[part 2 of 2: packages /CommunicationClusters/CANFD1_Cluster4 to /Gateways]
AUTOSAR XML (schema 00046)
package /CommunicationClusters/CANFD1_Cluster4
  can cluster CANFD1_Cluster4: baudrate=500000, protocol-name=CAN, protocol-version=can2.0b, can-fd-baudrate=1000000
    can physical channel CANFD1_Cluster4: comm-connectors=ECU4_CRN_CANFD1_Cluster4_bx4qzxpu7xp7napnh6bsrtlzq
      frame FBL_CFG_Star3_ST3: id 0x68, to ECU4_CRN, frame-length=1, can-addressing-mode=STANDARD, can-frame-rx-behavior=CAN-20, can-frame-tx-behavior=CAN-20  # FBL_CFG_Star2
        pdu FBL_Cfg_Star3_ST3: length=1, transmission-mode-true-timing=cyclic-timing={time-offset=0.005, time-period=0.2}, unused-bit-pattern=255  # FBL Konfigurationsinfo für Star2 / FBL configuration info for Star2
          signal Platform_Stat_Star3: start 0, 8 bit, little-endian, data-type-policy=OVERRIDE, i-signal-type=PRIMITIVE, init-value=4, base-type=uint8, invalid-value=255, compu-method=c08_Platform_Stat, data-constr=c08_Platform_Stat, transfer-property=PENDING, to ECU4_CRN  # Plattformstatus / Platform state
      frame GTS_Main_CAN_CTP: id 0x79, from ECU4_CRN, frame-length=8, can-addressing-mode=STANDARD, can-frame-rx-behavior=CAN-FD, can-frame-tx-behavior=CAN-FD  # Status Uhrsynchronisation / Clock synchronisation state
        carries pdu PKG_CANFD1_Cluster4/GTS_Main_CAN_CTP: packing-byte-order=big-endian, start-position=7
        general purpose pdu GTS_Main_CAN_CTP: category=GLOBAL_TIME, length=8  # Status Uhrsynchronisation / Clock synchronisation state
      frame C04_CANFD_1_Container_ST3: id 0x107, from ECU4_CRN, frame-length=64, can-addressing-mode=STANDARD, can-frame-rx-behavior=CAN-FD, can-frame-tx-behavior=CAN-FD  # C04 CANFD 1 Container ST3
        container i pdu C04_CANFD_1_Container_ST3_ContainerIPdu:  # C04 CANFD 1 Container ST3
          length=64
          contained-pdu-triggering=[C04_CANFD_1_Container_ST3_C04_CANFD_1_Container_ST3_Ign_Stat_ST3_1992kn5c94live1gqwsimzuwp, C04_CANFD_1_Container_ST3_C04_CANFD_1_Container_ST3_VSS_TP_Auth_ST3_2eg1fyiq81m97nelj47qvj2c4, C04_CANFD_1_Container_ST3_C04_CANFD_1_Container_ST3_VSS_TP_RealTmOffset_ST3_767nxsua3lonorooj3kljw1y8, C04_CANFD_1_Container_ST3_C04_CANFD_1_Container_ST3_VSS_TP_SecTickCount_Lvl2_ST3_84mjad6vrcpq4g3ks3442sp4d, C04_CANFD_1_Container_ST3_C04_CANFD_1_Container_ST3_VSS_TP_SharedSecret_ST3_f0ex48v4v693mvj1jphzyeobi, C04_CANFD_1_Container_ST3_C04_CANFD_1_Container_ST3_VSS_TP_VIN_ST3_do07meelbyu42egzxd3kh7khc]
          container-timeout=0.1
          container-trigger=DEFAULT-TRIGGER
          header-type=SHORT-HEADER
          minimum-tx-container-queue-size=2
          rx-accept-contained-i-pdu=ACCEPT-ALL
      frame TPA_Eth_CANFD_ST3: id 0x538, from ECU4_CRN, frame-length=64, can-addressing-mode=STANDARD, can-frame-rx-behavior=CAN-FD, can-frame-tx-behavior=CAN-FD  # Transport Protokoll zwischen Ethernet ECU und CAN-FD ECU / Transport protocol between Ethernet ECU and CAN-FD ECU
        n pdu TPA_Eth_CANFD_ST3: length=64  # Transport Protokoll zwischen Ethernet ECU und CAN-FD ECU / Transport protocol between Ethernet ECU and CAN-FD ECU
      frame TPA_CANFD_Eth_ST3: id 0x539, to ECU4_CRN, frame-length=64, can-addressing-mode=STANDARD, can-frame-rx-behavior=CAN-FD, can-frame-tx-behavior=CAN-FD  # Transport Protokoll zwischen CAN-FD ECU und Ethernet ECU / Transport protocol between CAN-FD ECU and Ethernet ECU
        n pdu TPA_CANFD_Eth_ST3: length=64  # Transport Protokoll zwischen CAN-FD ECU und Ethernet ECU / Transport protocol between CAN-FD ECU and Ethernet ECU
      frame COM_C04_Frm05: id 0xFF04005, from ECU4_CRN, frame-length=64, can-addressing-mode=EXTENDED, can-frame-rx-behavior=CAN-FD, can-frame-tx-behavior=CAN-FD  # COM C04 Pdu 05 and 06 content
        container i pdu COM_C04_Frm05_ContainerIPdu:  # COM C04 Pdu 05 and 06 content
          length=64
          contained-pdu-triggering=[COM_C04_Frm05_COM_C04_Frm05_COM_C04_Pdu05_5cqlmwzd8myffc611phcjhxa4, COM_C04_Frm05_COM_C04_Frm05_COM_C04_Pdu06_folytbvba5csarvaoqp75nzd, COM_C04_Frm05_COM_C04_Frm05_COM_C04_Pdu07_8bg7ik63nrgfru7ss58km9ssf]
          container-timeout=0.01
          container-trigger=DEFAULT-TRIGGER
          header-type=SHORT-HEADER
          minimum-tx-container-queue-size=1
          rx-accept-contained-i-pdu=ACCEPT-CONFIGURED
          threshold-size=60
      frame COM_C04_Frm01_PN08: id 0xFF04008, from ECU4_CRN, frame-length=8, can-addressing-mode=EXTENDED, can-frame-rx-behavior=CAN-FD, can-frame-tx-behavior=CAN-FD
        pdu COM_C04_Pdu01_PN08: length=8, transmission-mode-true-timing=cyclic-timing={time-offset=0.005, time-period=1}, unused-bit-pattern=0
          signal COM_C04_Sig01_PN08: start 0, 8 bit, little-endian, data-type-policy=OVERRIDE, i-signal-type=PRIMITIVE, init-value=255, base-type=uint8, data-constr=DT_uint8, transfer-property=PENDING
      frame COM_C04_Frm01_PN44: id 0xFF04044, from ECU4_CRN, frame-length=8, can-addressing-mode=EXTENDED, can-frame-rx-behavior=CAN-FD, can-frame-tx-behavior=CAN-FD
        pdu COM_C04_Pdu01_PN44: length=8, transmission-mode-true-timing=cyclic-timing={time-offset=0.005, time-period=1}, unused-bit-pattern=0
          signal COM_C04_Sig01_PN44: start 0, 8 bit, little-endian, data-type-policy=OVERRIDE, i-signal-type=PRIMITIVE, init-value=255, base-type=uint8, data-constr=DT_uint8, transfer-property=PENDING
      frame COM_C19_Frm02: id 0xFF19002, to ECU4_CRN, frame-length=64, can-addressing-mode=EXTENDED, can-frame-rx-behavior=CAN-FD, can-frame-tx-behavior=CAN-FD
        container i pdu COM_C19_Frm02_ContainerIPdu: length=64, contained-pdu-triggering=[COM_C19_Frm02_COM_C19_Frm02_COM_C19_Pdu02_37e9ffargwldan1o9511gdf3l, COM_C19_Frm02_COM_C19_Frm02_COM_C19_Pdu03_7s8sxqr1q39kt7z01g1ljxbt4, COM_C19_Frm02_COM_C19_Frm02_COM_C19_Pdu04_2wy38anjtuz6dz1pwsv6c1i23], container-timeout=0.01, container-trigger=DEFAULT-TRIGGER, header-type=SHORT-HEADER, rx-accept-contained-i-pdu=ACCEPT-CONFIGURED, threshold-size=60
      frame COM_C19_Frm01_PN08: id 0xFF19008, to ECU4_CRN, frame-length=8, can-addressing-mode=EXTENDED, can-frame-rx-behavior=CAN-FD, can-frame-tx-behavior=CAN-FD
        pdu COM_C19_Pdu01_PN08: length=8, transmission-mode-true-timing=cyclic-timing=time-period=1, unused-bit-pattern=0
          signal COM_C19_Sig01_PN08: start 0, 8 bit, little-endian, data-type-policy=OVERRIDE, i-signal-type=PRIMITIVE, init-value=255, base-type=uint8, data-constr=DT_uint8, transfer-property=PENDING, to ECU4_CRN(timeout 1.1 s)
      frame COM_C19_Frm01_PN44: id 0xFF19044, to ECU4_CRN, frame-length=8, can-addressing-mode=EXTENDED, can-frame-rx-behavior=CAN-FD, can-frame-tx-behavior=CAN-FD
        pdu COM_C19_Pdu01_PN44: length=8, transmission-mode-true-timing=cyclic-timing=time-period=1, unused-bit-pattern=0
          signal COM_C19_Sig01_PN44: start 0, 8 bit, little-endian, data-type-policy=OVERRIDE, i-signal-type=PRIMITIVE, init-value=255, base-type=uint8, data-constr=DT_uint8, transfer-property=PENDING, to ECU4_CRN(timeout 1.1 s)
      frame NM_C04: id 0x14420004, from ECU4_CRN, frame-length=8, can-addressing-mode=EXTENDED, can-frame-rx-behavior=CAN-20, can-frame-tx-behavior=CAN-20  # NM C04
        nm pdu NM_C04: length=8, nm-data-information=true, unused-bit-pattern=0  # NM C04
          signal NM_C04_PNC: start 8, 56 bit, opaque, data-type-policy=OVERRIDE, i-signal-type=ARRAY, init-value=7 x 0, base-type=uint8, transfer-property=PENDING  # PNC_Vector
      frame NM_Dummy_ST3: id 0x14420FFF, to ECU4_CRN, frame-length=8, can-addressing-mode=EXTENDED, can-frame-rx-behavior=CAN-20, can-frame-tx-behavior=CAN-20, rx-identifier-range={lower-can-id=339869696, upper-can-id=339873791}  # Netzwerk-Management / Network Management
        nm pdu NM_Dummy_ST3: length=8, nm-data-information=true, unused-bit-pattern=0  # Netzwerk-Management / Network Management
          signal NM_Dummy_ST3_PNC: start 8, 56 bit, opaque, data-type-policy=OVERRIDE, i-signal-type=ARRAY, init-value=7 x 0, base-type=uint8, transfer-property=PENDING  # PNC_Vector
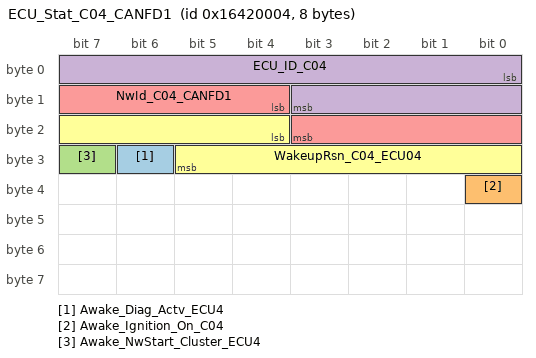
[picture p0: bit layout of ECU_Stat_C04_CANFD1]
      frame ECU_Stat_C04_CANFD1: id 0x16420004, from ECU4_CRN, frame-length=8, can-addressing-mode=EXTENDED, can-frame-rx-behavior=CAN-FD, can-frame-tx-behavior=CAN-FD
        pdu ECU_Stat_C04_CANFD1: length=8, transmission-mode-true-timing=cyclic-timing={time-offset=0.01, time-period=1}, unused-bit-pattern=255
          signal Awake_Diag_Actv_ECU4: start 30, 1 bit, little-endian, data-type-policy=OVERRIDE, i-signal-type=PRIMITIVE, init-value=1, base-type=boolean, transfer-property=PENDING
          signal Awake_Ignition_On_C04: start 32, 1 bit, little-endian, data-type-policy=OVERRIDE, i-signal-type=PRIMITIVE, init-value=1, base-type=boolean, transfer-property=PENDING
          signal Awake_NwStart_Cluster_ECU4: start 31, 1 bit, little-endian, data-type-policy=OVERRIDE, i-signal-type=PRIMITIVE, init-value=0, base-type=boolean, transfer-property=PENDING
          signal ECU_ID_C04: start 0, 12 bit, little-endian, data-type-policy=OVERRIDE, i-signal-type=PRIMITIVE, init-value=4, base-type=uint16, invalid-value=4095, data-constr=c12_na_0_to_4095_1, transfer-property=PENDING
          signal NwId_C04_CANFD1: start 12, 8 bit, little-endian, data-type-policy=OVERRIDE, i-signal-type=PRIMITIVE, init-value=3, base-type=uint8, invalid-value=255, data-constr=c08_na_0_to_255_1, transfer-property=PENDING
          signal WakeupRsn_C04_ECU04: start 20, 10 bit, little-endian, data-type-policy=OVERRIDE, i-signal-type=PRIMITIVE, init-value=1023, base-type=uint16, invalid-value=1023, compu-method=c10_WU_REASON_ECUx, data-constr=c10_WU_REASON_ECUx, transfer-property=PENDING
      frame DIAG_ECU4_CTP_03_ExtCAN_RS_FD_ST3: id 0x18E00481, from ECU4_CRN, frame-length=64, can-addressing-mode=EXTENDED, can-frame-rx-behavior=CAN-FD, can-frame-tx-behavior=CAN-FD  # Diagnoseanwort an ExtCAN von ECU4_CTP FD / Diagnostic Response to ExtCAN from ECU4_CTP FD
        n pdu DIAG_ECU4_CTP_03_ExtCAN_RS_FD_ST3: length=64  # Diagnoseanwort an ExtCAN von ECU4_CTP FD / Diagnostic Response to ExtCAN from ECU4_CTP FD
      frame DIAG_ECU4_CTP_03_ExtCAN_RQ_FD_ST3: id 0x18E00489, to ECU4_CRN, frame-length=64, can-addressing-mode=EXTENDED, can-frame-rx-behavior=CAN-FD, can-frame-tx-behavior=CAN-FD  # Diagnoseanfrage vom ExtCAN für ECU4_CTP FD / Diagnostic Request from ExtCAN for ECU4_CTP FD
        n pdu DIAG_ECU4_CTP_03_ExtCAN_RQ_FD_ST3: length=64  # Diagnoseanfrage vom ExtCAN für ECU4_CTP FD / Diagnostic Request from ExtCAN for ECU4_CTP FD
      frame DIAG_C19_ExtEth_RS_CANFD1_CTP: id 0x18E01980, to ECU4_CRN, frame-length=64, can-addressing-mode=EXTENDED  # DIAG C19 Ext Eth RS CANFD1 CTP
        n pdu DIAG_C19_ExtEth_RS_CANFD1_CTP: length=64  # DIAG C19 Ext Eth RS CANFD1 CTP
      frame DIAG_C19_IntEth_RS_CANFD1_CTP: id 0x18E01985, to ECU4_CRN, frame-length=64, can-addressing-mode=EXTENDED, can-frame-rx-behavior=CAN-FD, can-frame-tx-behavior=CAN-FD  # DIAG C19 Int Eth RS CANFD1 CTP
        n pdu DIAG_C19_IntEth_RS_CANFD1_CTP: length=64  # DIAG C19 Int Eth RS CANFD1 CTP
      frame DIAG_C19_ExtEth_RQ_CANFD1_CTP: id 0x18E01988, from ECU4_CRN, frame-length=64, can-addressing-mode=EXTENDED, can-frame-rx-behavior=CAN-FD, can-frame-tx-behavior=CAN-FD  # DIAG C19 Ext Eth RQ CANFD1 CTP
        n pdu DIAG_C19_ExtEth_RQ_CANFD1_CTP: length=64  # DIAG C19 Ext Eth RQ CANFD1 CTP
      frame DIAG_C19_IntEth_RQ_CANFD1_CTP: id 0x18E0198D, from ECU4_CRN, frame-length=64, can-addressing-mode=EXTENDED, can-frame-rx-behavior=CAN-FD, can-frame-tx-behavior=CAN-FD  # DIAG C19 Int Eth RQ CANFD1 CTP
        n pdu DIAG_C19_IntEth_RQ_CANFD1_CTP: length=64  # DIAG C19 Int Eth RQ CANFD1 CTP
      frame DIAG_RQ_GLOBAL_ExtEth_FD_ST3: id 0x18EEF888, from ECU4_CRN, frame-length=64, can-addressing-mode=EXTENDED, can-frame-rx-behavior=CAN-FD, can-frame-tx-behavior=CAN-FD  # Funktionaler Diagnose-Request vom Off-Board Tester (via Ethernet) / Functional Diagnostic Request from Off-Board Tester (via Ethernet)
        n pdu DIAG_RQ_GLOBAL_ExtEth_FD_ST3: length=64  # Funktionale Diagnoseanfrage (UDS) vom ExtEth FD / Functional Diagnostic Request (UDS) from ExtEth FD
      frame DIAG_RQ_GLOBAL_ExtCAN_FD_ST3: id 0x18EEF989, to ECU4_CRN, frame-length=64, can-addressing-mode=EXTENDED, can-frame-rx-behavior=CAN-FD, can-frame-tx-behavior=CAN-FD  # Funktionaler Diagnose-Request vom Off-Board Tester (via CAN) / Functional Diagnostic Request from Off-Board Tester (via CAN)
        n pdu DIAG_RQ_GLOBAL_ExtCAN_FD_ST3: length=64  # Funktionale Diagnoseanfrage (UDS) vom ExtCAN FD / Functional Diagnostic Request (UDS) from ExtCAN FD
      frame DIAG_RQ_GLOBAL_IntEth_FD_ST3: id 0x18EF0D8D, from ECU4_CRN, frame-length=64, can-addressing-mode=EXTENDED, can-frame-rx-behavior=CAN-FD, can-frame-tx-behavior=CAN-FD  # Funktionaler Diagnose-Request vom On-Board Tester (via Ethernet) / Functional Diagnostic Request from On-Board Tester (via Ethernet)
        n pdu DIAG_RQ_GLOBAL_IntEth_FD_ST3: length=64  # Funktionale Diagnoseanfrage (UDS) vom IntEth FD / Functional Diagnostic Request (UDS) from IntEth FD
      pdu triggering C04_CANFD_1_Container_ST3_C04_CANFD_1_Container_ST3_Ign_Stat_ST3_eexaxtkd214droewntksh6wv: pdu=C04_CANFD_1_Container_ST3_Ign_Stat_ST3, from ECU4_CRN
      pdu triggering C04_CANFD_1_Container_ST3_C04_CANFD_1_Container_ST3_Ign_Stat_ST3_1992kn5c94live1gqwsimzuwp: pdu=C04_CANFD_1_Container_ST3_C04_CANFD_1_Container_ST3_Ign_Stat_ST3_secured, from ECU4_CRN
      pdu triggering C04_CANFD_1_Container_ST3_C04_CANFD_1_Container_ST3_VSS_TP_Auth_ST3_2eg1fyiq81m97nelj47qvj2c4: pdu=C04_CANFD_1_Container_ST3_VSS_TP_Auth_ST3, from ECU4_CRN
      pdu triggering C04_CANFD_1_Container_ST3_C04_CANFD_1_Container_ST3_VSS_TP_RealTmOffset_ST3_767nxsua3lonorooj3kljw1y8: pdu=C04_CANFD_1_Container_ST3_VSS_TP_RealTmOffset_ST3, from ECU4_CRN
      pdu triggering C04_CANFD_1_Container_ST3_C04_CANFD_1_Container_ST3_VSS_TP_SecTickCount_Lvl2_ST3_84mjad6vrcpq4g3ks3442sp4d: pdu=C04_CANFD_1_Container_ST3_VSS_TP_SecTickCount_Lvl2_ST3, from ECU4_CRN
      pdu triggering C04_CANFD_1_Container_ST3_C04_CANFD_1_Container_ST3_VSS_TP_SharedSecret_ST3_f0ex48v4v693mvj1jphzyeobi: pdu=C04_CANFD_1_Container_ST3_VSS_TP_SharedSecret_ST3, from ECU4_CRN
      pdu triggering C04_CANFD_1_Container_ST3_C04_CANFD_1_Container_ST3_VSS_TP_VIN_ST3_do07meelbyu42egzxd3kh7khc: pdu=C04_CANFD_1_Container_ST3_VSS_TP_VIN_ST3, from ECU4_CRN
      pdu triggering COM_C04_Frm05_COM_C04_Frm05_COM_C04_Pdu05_5cqlmwzd8myffc611phcjhxa4: pdu=COM_C04_Frm05_COM_C04_Pdu05, from ECU4_CRN
      pdu triggering COM_C04_Frm05_COM_C04_Frm05_COM_C04_Pdu06_folytbvba5csarvaoqp75nzd: pdu=COM_C04_Frm05_COM_C04_Pdu06, from ECU4_CRN
      pdu triggering COM_C04_Frm05_COM_C04_Frm05_COM_C04_Pdu07_8bg7ik63nrgfru7ss58km9ssf: pdu=COM_C04_Frm05_COM_C04_Pdu07, from ECU4_CRN
      pdu triggering COM_C19_Frm02_COM_C19_Frm02_COM_C19_Pdu02_37e9ffargwldan1o9511gdf3l: pdu=COM_C19_Frm02_COM_C19_Pdu02, to ECU4_CRN
      pdu triggering COM_C19_Frm02_COM_C19_Frm02_COM_C19_Pdu03_7s8sxqr1q39kt7z01g1ljxbt4: pdu=COM_C19_Frm02_COM_C19_Pdu03, to ECU4_CRN
      pdu triggering COM_C19_Frm02_COM_C19_Frm02_COM_C19_Pdu04_2wy38anjtuz6dz1pwsv6c1i23: pdu=COM_C19_Frm02_COM_C19_Pdu04, to ECU4_CRN
      pdu triggering SDU_DIAG_C19_ExtEth_RQ_CANFD1_CTP_eyvcacykr98fcvkcggj4dhrfu: pdu=SDU_DIAG_C19_ExtEth_RQ_CANFD1_CTP, from ECU4_CRN
      pdu triggering SDU_DIAG_C19_ExtEth_RS_CANFD1_CTP_bhijhykhhudk93cghpikxa48z: pdu=SDU_DIAG_C19_ExtEth_RS_CANFD1_CTP, to ECU4_CRN
      pdu triggering SDU_DIAG_C19_IntEth_RQ_CANFD1_CTP_2akb334vpy7broagwjotlwysj: pdu=SDU_DIAG_C19_IntEth_RQ_CANFD1_CTP, from ECU4_CRN
      pdu triggering SDU_DIAG_C19_IntEth_RS_CANFD1_CTP_2y5n7celggbq23uuvdl3soavl: pdu=SDU_DIAG_C19_IntEth_RS_CANFD1_CTP, to ECU4_CRN
      pdu triggering SDU_DIAG_ECU4_CTP_03_ExtCAN_RQ_FD1_ST3_8f6vot3usfcxgkduwzu8gi3jc: pdu=SDU_DIAG_ECU4_CTP_03_ExtCAN_RQ_FD1_ST3, to ECU4_CRN
      pdu triggering SDU_DIAG_ECU4_CTP_03_ExtCAN_RS_FD1_ST3_by97dcvzr4fgxi453b11nanb4: pdu=SDU_DIAG_ECU4_CTP_03_ExtCAN_RS_FD1_ST3, from ECU4_CRN
      pdu triggering SDU_DIAG_GLOBAL_ExtCAN_RQ_CANFD1_ST3_11tito4firwdw41sk72ywzj3u: pdu=SDU_DIAG_GLOBAL_ExtCAN_RQ_CANFD1_ST3, to ECU4_CRN
      pdu triggering SDU_DIAG_GLOBAL_ExtEth_RQ_CANFD1_ST3_bm2khh4k5j0ahsiarvpnr3xfw: pdu=SDU_DIAG_GLOBAL_ExtEth_RQ_CANFD1_ST3, from ECU4_CRN
      pdu triggering SDU_DIAG_GLOBAL_IntEth_RQ_CANFD1_ST3_er43low3fmuv5pz3oqfwqhzx6: pdu=SDU_DIAG_GLOBAL_IntEth_RQ_CANFD1_ST3, from ECU4_CRN
      pdu triggering SDU_TPA_CANFD_Eth_ST3_223y18kpjajvocx2jd9qi9m6d: pdu=SDU_TPA_CANFD_Eth_ST3, to ECU4_CRN
      pdu triggering SDU_TPA_Eth_CANFD_ST3_3qyvbrq6q4y6bx7f9mo5p0pxc: pdu=SDU_TPA_Eth_CANFD_ST3, from ECU4_CRN
package /CommunicationClusters/Eth_Cluster4
  ethernet cluster Eth_Cluster4: baudrate=100000000, protocol-name=ETHERNET, coupling-port-connection{first-port=COUPLING_PORT, second-port=ECU4_CRN_Switch}
    7 x ethernet physical channel:
      Eth_Cluster4_1: comm-connectors=ECU4_CRN_Eth_Cluster4_7f3fu4rgtopbi2t35la2b13rd
        pdu triggering DIAG_ROE_C04_Container_ST3_DIAG_ROE_C04_Container_ST3_ROE_C04_PDU01_46sqdttlzgs8yhldm3zvniwzz: pdu=DIAG_ROE_C04_Container_ST3_ROE_C04_PDU01, from ECU4_CRN
        pdu triggering DIAG_RQ_Eth_CTP_92bp3piwe38d7dnrvgoj3ceig: pdu=PKG_Eth_Cluster4_1/DIAG_RQ_Eth_CTP_2, to ECU4_CRN
        pdu triggering DIAG_RS_Eth_CTP_a6gdsu2lmo0bwmubukysvxxv4: pdu=PKG_Eth_Cluster4_1/DIAG_RS_Eth_CTP, from ECU4_CRN
        pdu triggering DIAG_RS_Eth_CTP_apthu8x7onsavwv8i2qflovju: pdu=PKG_Eth_Cluster4_1/DIAG_RS_Eth_CTP_2, from ECU4_CRN
        pdu triggering SDU_DIAG_RQ_ExtEth_MAIN_OFBD_ST3_ECU04_C04_4dmveypo3w1bhqotywiq097t1: pdu=SDU_DIAG_RQ_ExtEth_MAIN_OFBD_ST3_ECU04_C04, to ECU4_CRN
        pdu triggering SDU_DIAG_RQ_ExtEth_MAIN_OFBD_ST3_ECU04_C10_8bs9x8gur62w6bwg0or3xlt1n: pdu=SDU_DIAG_RQ_ExtEth_MAIN_OFBD_ST3_ECU04_C10, to ECU4_CRN
        pdu triggering SDU_DIAG_RQ_ExtEth_MAIN_OFBD_ST3_ECU04_C19_e3yd3agiopsan0f18roz4lg4c: pdu=SDU_DIAG_RQ_ExtEth_MAIN_OFBD_ST3_ECU04_C19, to ECU4_CRN
        pdu triggering SDU_DIAG_RQ_ExtEth_MAIN_OFBD_ST3_ECU04_GLOBAL_6t0nz984eogl3mw7cjfi70hic: pdu=SDU_DIAG_RQ_ExtEth_MAIN_OFBD_ST3_ECU04_GLOBAL, to ECU4_CRN
        pdu triggering SDU_DIAG_RQ_ExtEth_MAIN_OFBD_ST3_ECU04_Lin_S5_6ggxi1acxe71ypczxg09dp6fi: pdu=SDU_DIAG_RQ_ExtEth_MAIN_OFBD_ST3_ECU04_Lin_S5, to ECU4_CRN
        pdu triggering SDU_DIAG_RS_ExtEth_MAIN_OFBD_ST3_ECU04_C04_3vlwsmbmh08dnwhynpcmg7w3: pdu=SDU_DIAG_RS_ExtEth_MAIN_OFBD_ST3_ECU04_C04, from ECU4_CRN
        pdu triggering SDU_DIAG_RS_ExtEth_MAIN_OFBD_ST3_ECU04_C10_4so8pe6xjjiiuv0vyru6o8ni0: pdu=SDU_DIAG_RS_ExtEth_MAIN_OFBD_ST3_ECU04_C10, from ECU4_CRN
        pdu triggering SDU_DIAG_RS_ExtEth_MAIN_OFBD_ST3_ECU04_C19_2rqbwg8zxyohi6w3cknvf6a5o: pdu=SDU_DIAG_RS_ExtEth_MAIN_OFBD_ST3_ECU04_C19, from ECU4_CRN
        pdu triggering SDU_DIAG_RS_ExtEth_MAIN_OFBD_ST3_ECU04_Lin_S5_68xvz5qpob04lqj41rwbz17ff: pdu=SDU_DIAG_RS_ExtEth_MAIN_OFBD_ST3_ECU04_Lin_S5, from ECU4_CRN
        pdu triggering DIAG_RS_Eth_CTP_TCP_SC_DoIP_NACK_TCP_Any_13400: pdu=PKG_Eth_Cluster4_1/DIAG_RS_Eth_CTP_TCP_2, from ECU4_CRN
        pdu triggering DIAG_RS_Eth_CTP_TCP_SC_ECU4_CRN_TCP_XDIS_1fowdhneodog21hxguso5ftv0: pdu=PKG_Eth_Cluster4_1/DIAG_RS_Eth_CTP_TCP, from ECU4_CRN
        pdu triggering DIAG_RQ_Eth_CTP_TCP_SC_DoIP_NACK_TCP_Any_13400: pdu=PKG_Eth_Cluster4_1/DIAG_RQ_Eth_CTP_TCP_2, to ECU4_CRN
        pdu triggering DIAG_RQ_Eth_CTP_TCP_SC_ECU4_CRN_TCP_XDIS_1fowdhneodog21hxguso5ftv0: pdu=PKG_Eth_Cluster4_1/DIAG_RQ_Eth_CTP_TCP, to ECU4_CRN
        4 x network endpoint:
          NE_dhcpv4AndFixed_169_254_17_4: infrastructure-services=do-ip-entity=do-ip-entity-role=GATEWAY, priority=0
            network-endpoint-addresses:
              assignment-priority=1, ip-address-keep-behavior=FORGET, ipv-4-address-source=DHCPV-4, ttl=1
              assignment-priority=2, ip-address-keep-behavior=FORGET, ipv-4-address=169.254.17.4, ipv-4-address-source=FIXED, network-mask=255.255.0.0, ttl=1
          NE_fixed_255_255_255_255: network-endpoint-addresses=ipv-4-configuration={ipv-4-address=255.255.255.255, ipv-4-address-source=FIXED}
          NE_Any: network-endpoint-addresses=ipv-4-configuration=ipv-4-address=ANY
          NE_Multicast_Rx_fixed_239_1_0_8: network-endpoint-addresses=ipv-4-configuration={ipv-4-address=239.1.0.8, ipv-4-address-source=FIXED}
        so-ad-config:
          socket connection bundle SCB_ECU4_CRN_UDP_dhcpv4AndFixed_169_254_17_4_13400: server-port=SA_ECU4_CRN_UDP_dhcpv4AndFixed_169_254_17_4_13400
            bundled-connections:
              {client-port=Eth_Cluster4_1/SA_ECU4_CRN_UDP_fixed_255_255_255_255_13400_Remote, pdus=socket-connection-ipdu-identifier={pdu-collection-semantics=QUEUED, pdu-triggering=DIAG_RS_Eth_CTP_a6gdsu2lmo0bwmubukysvxxv4}, short-label=SC_ECU4_CRN_DoIP_Broad_UDP_fixed_255_255_255_255_13400_Remote}
              {client-port-from-connection-request=true, client-port=Eth_Cluster4_1/SA_ECU4_CRN_UDP_Any_DynamicPort_Remote, pdus=[{pdu-collection-semantics=QUEUED, pdu-triggering=DIAG_RS_Eth_CTP_apthu8x7onsavwv8i2qflovju}, {pdu-collection-semantics=QUEUED, pdu-triggering=DIAG_RQ_Eth_CTP_92bp3piwe38d7dnrvgoj3ceig}], short-label=SC_ECU4_CRN_UDP_Any_DynamicPort_Remote}
          socket connection bundle SCB_ECU4_CRN_UDP_dhcpv4AndFixed_169_254_17_4_60000: socket-connection{client-port=SA_ECU4_CRN_UDP_Multicast_fixed_239_1_0_8_60000_Remote, pdus=socket-connection-ipdu-identifier={header-id=1073840129, pdu-collection-pdu-timeout=0.02, pdu-collection-semantics=QUEUED, pdu-collection-trigger=NEVER, pdu-triggering=DIAG_ROE_C04_Container_ST3_DIAG_ROE_C04_Container_ST3_ROE_C04_PDU01_46sqdttlzgs8yhldm3zvniwzz}, pdu-collection-max-buffer-size=1472, pdu-collection-timeout=0.1, short-label=SC_ECU4_CRN_UDP_Multicast_fixed_239_1_0_8_60000_Remote}, server-port=SA_ECU4_CRN_UDP_dhcpv4AndFixed_169_254_17_4_60000
          socket connection bundle SCB_ECU4_CRN_DoIP_TCP_dhcpv4AndFixed_169_254_17_4_13400: server-port=SA_TCP_dhcpv4AndFixed_169_254_17_4_13400
            bundled-connections:
              client-ip-addr-from-connection-request=true, client-port-from-connection-request=true, client-port=Eth_Cluster4_1/SA_TCP_Any_DynamicPort, pdus=[DIAG_RS_Eth_CTP_TCP_SC_ECU4_CRN_TCP_XDIS_1fowdhneodog21hxguso5ftv0, DIAG_RQ_Eth_CTP_TCP_SC_ECU4_CRN_TCP_XDIS_1fowdhneodog21hxguso5ftv0], short-label=SC_ECU4_CRN_TCP_XDIS_1fowdhneodog21hxguso5ftv0
              client-ip-addr-from-connection-request=true, client-port-from-connection-request=true, client-port=Eth_Cluster4_1/SA_TCP_Any_13400, pdus=[Eth_Cluster4_1/DIAG_RS_Eth_CTP_TCP_SC_DoIP_NACK_TCP_Any_13400, Eth_Cluster4_1/DIAG_RQ_Eth_CTP_TCP_SC_DoIP_NACK_TCP_Any_13400], short-label=SC_DoIP_NACK_TCP_Any_13400
          8 x socket address:
            SA_ECU4_CRN_UDP_dhcpv4AndFixed_169_254_17_4_13400: connector=ECU4_CRN_Eth_Cluster4_7f3fu4rgtopbi2t35la2b13rd
              application endpoint AE_ECU4_CRN_UDP_dhcpv4AndFixed_169_254_17_4_13400: network-endpoint=NE_dhcpv4AndFixed_169_254_17_4, tp-configuration=udp-tp=udp-tp-port=port-number=13400
            SA_ECU4_CRN_UDP_fixed_255_255_255_255_13400_Remote
              application endpoint AE_ECU4_CRN_UDP_fixed_255_255_255_255_13400_Remote: network-endpoint=Eth_Cluster4_1/NE_fixed_255_255_255_255, tp-configuration=udp-tp=udp-tp-port=port-number=13400
            SA_ECU4_CRN_UDP_Any_DynamicPort_Remote
              application endpoint AE_ECU4_CRN_UDP_Any_DynamicPort_Remote: network-endpoint=Eth_Cluster4_1/NE_Any, tp-configuration=udp-tp=udp-tp-port=dynamically-assigned=true
            SA_ECU4_CRN_UDP_dhcpv4AndFixed_169_254_17_4_60000: connector=ECU4_CRN_Eth_Cluster4_7f3fu4rgtopbi2t35la2b13rd
              application endpoint AE_ECU4_CRN_UDP_dhcpv4AndFixed_169_254_17_4_60000: network-endpoint=NE_dhcpv4AndFixed_169_254_17_4, tp-configuration=udp-tp=udp-tp-port=port-number=60000
            SA_ECU4_CRN_UDP_Multicast_fixed_239_1_0_8_60000_Remote
              application endpoint AE_ECU4_CRN_UDP_Multicast_fixed_239_1_0_8_60000_Remote: network-endpoint=NE_Multicast_Rx_fixed_239_1_0_8, tp-configuration=udp-tp=udp-tp-port=port-number=60000
            SA_TCP_dhcpv4AndFixed_169_254_17_4_13400: connector=ECU4_CRN_Eth_Cluster4_7f3fu4rgtopbi2t35la2b13rd
              application endpoint AE_TCP_dhcpv4AndFixed_169_254_17_4_13400: network-endpoint=NE_dhcpv4AndFixed_169_254_17_4, tp-configuration=tcp-tp=tcp-tp-port=port-number=13400
            SA_TCP_Any_DynamicPort
              application endpoint AE_TCP_Any_DynamicPort: network-endpoint=Eth_Cluster4_1/NE_Any, tp-configuration=tcp-tp=tcp-tp-port=dynamically-assigned=true
            SA_TCP_Any_13400
              application endpoint AE_TCP_Any_13400: network-endpoint=Eth_Cluster4_1/NE_Any, tp-configuration=tcp-tp=tcp-tp-port=port-number=13400
        vlan Eth_Cluster4_1: vlan-identifier=1
      Eth_Cluster4_127: comm-connectors=ECU4_CRN_Eth_Cluster4_3g6xoesclytkmkqofl9pi6ol1, managed-physical-channel=[Eth_Cluster4_1, Eth_Cluster4_2, Eth_Cluster4_20]
        pdu triggering ECU_Stat_C04_ETH_Container_ECU_Stat_C04_ETH_Container_ECU_Stat_C04_ETH_50cq56gch124sh541fjk0jp4e: pdu=ECU_Stat_C04_ETH_Container_ECU_Stat_C04_ETH, from ECU4_CRN
        pdu triggering NM_C04_66vse8d86zvcn96zhhel5euom: pdu=PKG_Eth_Cluster4_127/NM_C04, from ECU4_CRN
        pdu triggering NM_Dummy__ST3_d8seiuisaba6dac7c7f43ftk6: pdu=NM_Dummy__ST3, to ECU4_CRN
        6 x network endpoint:
          NE_Multicast_Rx_fixed_239_127_0_1: network-endpoint-addresses=ipv-4-configuration={ipv-4-address=239.127.0.1, ipv-4-address-source=FIXED}
          NE_Any: network-endpoint-addresses=ipv-4-configuration=ipv-4-address=ANY
          NE_fixed_10_127_1_4: network-endpoint-addresses=ipv-4-configuration={ipv-4-address=10.127.1.4, ipv-4-address-source=FIXED, network-mask=255.255.0.0, ttl=1}, priority=5
          NE_fixed_10_127_1_1: network-endpoint-addresses=ipv-4-configuration={ipv-4-address=10.127.1.1, ipv-4-address-source=FIXED, network-mask=255.255.0.0, ttl=1}, priority=5
          NE_fixed_10_127_1_5: network-endpoint-addresses=ipv-4-configuration={ipv-4-address=10.127.1.5, ipv-4-address-source=FIXED, network-mask=255.255.0.0, ttl=1}, priority=5
          NE_fixed_10_127_1_7: network-endpoint-addresses=ipv-4-configuration={ipv-4-address=10.127.1.7, ipv-4-address-source=FIXED, network-mask=255.255.0.0, ttl=1}, priority=5
        so-ad-config:
          socket connection bundle SCB_ECU4_CRN_UDP_Multicast_Rx_fixed_239_127_0_1_20000: socket-connection{client-port-from-connection-request=true, client-port=Eth_Cluster4_127/SA_ECU4_CRN_UDP_Any_DynamicPort_Remote, pdus=socket-connection-ipdu-identifier={pdu-collection-semantics=QUEUED, pdu-triggering=NM_Dummy__ST3_d8seiuisaba6dac7c7f43ftk6}, short-label=SC_ECU4_CRN_UDP_Any_DynamicPort_Remote}, server-port=SA_ECU4_CRN_UDP_Multicast_Rx_fixed_239_127_0_1_20000
          socket connection bundle SCB_ECU4_CRN_UDP_fixed_10_127_1_4_20000: socket-connection{client-ip-addr-from-connection-request=true, client-port-from-connection-request=true, client-port=SA_ECU4_CRN_UDP_Multicast_fixed_239_127_0_1_20000_Remote, pdus=socket-connection-ipdu-identifier={pdu-collection-semantics=QUEUED, pdu-triggering=NM_C04_66vse8d86zvcn96zhhel5euom}, short-label=SC_ECU4_CRN_UDP_Multicast_fixed_239_127_0_1_20000_Remote}, server-port=SA_ECU4_CRN_UDP_fixed_10_127_1_4_20000
          socket connection bundle SCB_ECU4_CRN_UDP_fixed_10_127_1_4_40002: server-port=SA_ECU4_CRN_UDP_fixed_10_127_1_4_40002
            bundled-connections:
              {client-port=SA_ECU4_CRN_UDP_fixed_10_127_1_1_40002_Remote, pdus=socket-connection-ipdu-identifier={header-id=972980228, pdu-collection-semantics=QUEUED, pdu-collection-trigger=NEVER, pdu-triggering=ECU_Stat_C04_ETH_Container_ECU_Stat_C04_ETH_Container_ECU_Stat_C04_ETH_50cq56gch124sh541fjk0jp4e}, pdu-collection-max-buffer-size=1472, pdu-collection-timeout=0.01, short-label=SC_ECU4_CRN_UDP_fixed_10_127_1_1_40002_Remote}
              {client-port=SA_ECU4_CRN_UDP_fixed_10_127_1_5_40002_Remote, pdus=socket-connection-ipdu-identifier={header-id=972980228, pdu-collection-semantics=QUEUED, pdu-collection-trigger=NEVER, pdu-triggering=ECU_Stat_C04_ETH_Container_ECU_Stat_C04_ETH_Container_ECU_Stat_C04_ETH_50cq56gch124sh541fjk0jp4e}, pdu-collection-max-buffer-size=1472, pdu-collection-timeout=0.01, short-label=SC_ECU4_CRN_UDP_fixed_10_127_1_5_40002_Remote}
              {client-port=SA_ECU4_CRN_UDP_fixed_10_127_1_7_40002_Remote, pdus=socket-connection-ipdu-identifier={header-id=972980228, pdu-collection-semantics=QUEUED, pdu-collection-trigger=NEVER, pdu-triggering=ECU_Stat_C04_ETH_Container_ECU_Stat_C04_ETH_Container_ECU_Stat_C04_ETH_50cq56gch124sh541fjk0jp4e}, pdu-collection-max-buffer-size=1472, pdu-collection-timeout=0.01, short-label=SC_ECU4_CRN_UDP_fixed_10_127_1_7_40002_Remote}
          8 x socket address:
            SA_ECU4_CRN_UDP_Multicast_Rx_fixed_239_127_0_1_20000: multicast-connector=ECU4_CRN_Eth_Cluster4_3g6xoesclytkmkqofl9pi6ol1
              application endpoint AE_ECU4_CRN_UDP_Multicast_Rx_fixed_239_127_0_1_20000: network-endpoint=NE_Multicast_Rx_fixed_239_127_0_1, tp-configuration=udp-tp=udp-tp-port=port-number=20000
            SA_ECU4_CRN_UDP_Any_DynamicPort_Remote
              application endpoint AE_ECU4_CRN_UDP_Any_DynamicPort_Remote: network-endpoint=Eth_Cluster4_127/NE_Any, tp-configuration=udp-tp=udp-tp-port=dynamically-assigned=true
            SA_ECU4_CRN_UDP_fixed_10_127_1_4_20000: connector=ECU4_CRN_Eth_Cluster4_3g6xoesclytkmkqofl9pi6ol1
              application endpoint AE_ECU4_CRN_UDP_fixed_10_127_1_4_20000: network-endpoint=NE_fixed_10_127_1_4, tp-configuration=udp-tp=udp-tp-port=port-number=20000
            SA_ECU4_CRN_UDP_Multicast_fixed_239_127_0_1_20000_Remote
              application endpoint AE_ECU4_CRN_UDP_Multicast_fixed_239_127_0_1_20000_Remote: network-endpoint=NE_Multicast_Rx_fixed_239_127_0_1, tp-configuration=udp-tp=udp-tp-port=port-number=20000
            SA_ECU4_CRN_UDP_fixed_10_127_1_4_40002: connector=ECU4_CRN_Eth_Cluster4_3g6xoesclytkmkqofl9pi6ol1
              application endpoint AE_ECU4_CRN_UDP_fixed_10_127_1_4_40002: network-endpoint=NE_fixed_10_127_1_4, tp-configuration=udp-tp=udp-tp-port=port-number=40002
            SA_ECU4_CRN_UDP_fixed_10_127_1_1_40002_Remote
              application endpoint AE_ECU4_CRN_UDP_fixed_10_127_1_1_40002_Remote: network-endpoint=NE_fixed_10_127_1_1, tp-configuration=udp-tp=udp-tp-port=port-number=40002
            SA_ECU4_CRN_UDP_fixed_10_127_1_5_40002_Remote
              application endpoint AE_ECU4_CRN_UDP_fixed_10_127_1_5_40002_Remote: network-endpoint=NE_fixed_10_127_1_5, tp-configuration=udp-tp=udp-tp-port=port-number=40002
            SA_ECU4_CRN_UDP_fixed_10_127_1_7_40002_Remote
              application endpoint AE_ECU4_CRN_UDP_fixed_10_127_1_7_40002_Remote: network-endpoint=NE_fixed_10_127_1_7, tp-configuration=udp-tp=udp-tp-port=port-number=40002
        vlan Eth_Cluster4_127: vlan-identifier=127
      Eth_Cluster4_2: comm-connectors=ECU4_CRN_Eth_Cluster4_a4tivcve7b3dlvxw1emxbqzmz
        pdu triggering DIAG_C01_ONBD_Container_ST3_DIAG_C01_ONBD_Container_ST3_DIAG_Stat_ST3_ai26rj2l6x4vcdimgt9rtd4lr: pdu=DIAG_C01_ONBD_Container_ST3_DIAG_Stat_ST3, to ECU4_CRN
        pdu triggering DIAG_RQ_Eth_CTP_36cxv9alsl7ovfjegh7ccgshu: pdu=PKG_Eth_Cluster4_2/DIAG_RQ_Eth_CTP_2, to ECU4_CRN
        pdu triggering DIAG_RS_Eth_CTP_4zfaog9k8ca7q3h7nr30e3lyk: pdu=PKG_Eth_Cluster4_2/DIAG_RS_Eth_CTP, from ECU4_CRN
        pdu triggering DIAG_RS_Eth_CTP_4wn8ypb98gjeuccwqbke7b5iq: pdu=PKG_Eth_Cluster4_2/DIAG_RS_Eth_CTP_2, from ECU4_CRN
        pdu triggering SDU_DIAG_RQ_IntEth_MAIN_ONBD_ST3_ECU04_C04_9sg7qwlojfjz042n6cetze6lz: pdu=SDU_DIAG_RQ_IntEth_MAIN_ONBD_ST3_ECU04_C04, to ECU4_CRN
        pdu triggering SDU_DIAG_RQ_IntEth_MAIN_ONBD_ST3_ECU04_C10_bu43aca6egev4kodpfgkbh2q1: pdu=SDU_DIAG_RQ_IntEth_MAIN_ONBD_ST3_ECU04_C10, to ECU4_CRN
        pdu triggering SDU_DIAG_RQ_IntEth_MAIN_ONBD_ST3_ECU04_C19_ewow239n0d9my3gr29d7sf5d9: pdu=SDU_DIAG_RQ_IntEth_MAIN_ONBD_ST3_ECU04_C19, to ECU4_CRN
        pdu triggering SDU_DIAG_RQ_IntEth_MAIN_ONBD_ST3_ECU04_GLOBAL_18bpy3o9ynyikhmp6htlekvij: pdu=SDU_DIAG_RQ_IntEth_MAIN_ONBD_ST3_ECU04_GLOBAL, to ECU4_CRN
        pdu triggering SDU_DIAG_RQ_IntEth_MAIN_ONBD_ST3_ECU04_Lin_S5_1axuns5to494ige1q6fv1uhrf: pdu=SDU_DIAG_RQ_IntEth_MAIN_ONBD_ST3_ECU04_Lin_S5, to ECU4_CRN
        pdu triggering SDU_DIAG_RS_IntEth_MAIN_ONBD_ST3_ECU04_C04_27f5t9nk82ncecf7od0bwxpx4: pdu=SDU_DIAG_RS_IntEth_MAIN_ONBD_ST3_ECU04_C04, from ECU4_CRN
        pdu triggering SDU_DIAG_RS_IntEth_MAIN_ONBD_ST3_ECU04_C10_b7en6eeo4kov60pvr8pzr8ijy: pdu=SDU_DIAG_RS_IntEth_MAIN_ONBD_ST3_ECU04_C10, from ECU4_CRN
        pdu triggering SDU_DIAG_RS_IntEth_MAIN_ONBD_ST3_ECU04_C19_b9uku0tcwh0dsl79rtmnbfkkp: pdu=SDU_DIAG_RS_IntEth_MAIN_ONBD_ST3_ECU04_C19, from ECU4_CRN
        pdu triggering SDU_DIAG_RS_IntEth_MAIN_ONBD_ST3_ECU04_Lin_S5_6wuc0r472khlvbka0p3xs4gvu: pdu=SDU_DIAG_RS_IntEth_MAIN_ONBD_ST3_ECU04_Lin_S5, from ECU4_CRN
        pdu triggering DIAG_RS_Eth_CTP_TCP_SC_DoIP_NACK_TCP_Any_13400: pdu=PKG_Eth_Cluster4_2/DIAG_RS_Eth_CTP_TCP_2, from ECU4_CRN
        pdu triggering DIAG_RS_Eth_CTP_TCP_SC_ECU4_CRN_TCP_XDIS_5ihozhx5chpshf5e200ea13ho: pdu=PKG_Eth_Cluster4_2/DIAG_RS_Eth_CTP_TCP, from ECU4_CRN
        pdu triggering DIAG_RQ_Eth_CTP_TCP_SC_DoIP_NACK_TCP_Any_13400: pdu=PKG_Eth_Cluster4_2/DIAG_RQ_Eth_CTP_TCP_2, to ECU4_CRN
        pdu triggering DIAG_RQ_Eth_CTP_TCP_SC_ECU4_CRN_TCP_XDIS_5ihozhx5chpshf5e200ea13ho: pdu=PKG_Eth_Cluster4_2/DIAG_RQ_Eth_CTP_TCP, to ECU4_CRN
        5 x network endpoint:
          NE_Multicast_Rx_fixed_239_2_0_17: network-endpoint-addresses=ipv-4-configuration={ipv-4-address=239.2.0.17, ipv-4-address-source=FIXED}
          NE_fixed_10_2_1_1: infrastructure-services=do-ip-entity=do-ip-entity-role=GATEWAY, network-endpoint-addresses=ipv-4-configuration={ipv-4-address=10.2.1.1, ipv-4-address-source=FIXED, network-mask=255.255.0.0, ttl=1}, priority=0
          NE_fixed_10_2_1_4: infrastructure-services=do-ip-entity=do-ip-entity-role=GATEWAY, network-endpoint-addresses=ipv-4-configuration={ipv-4-address=10.2.1.4, ipv-4-address-source=FIXED, network-mask=255.255.0.0, ttl=1}, priority=0
          NE_fixed_255_255_255_255: network-endpoint-addresses=ipv-4-configuration={ipv-4-address=255.255.255.255, ipv-4-address-source=FIXED}
          NE_Any: network-endpoint-addresses=ipv-4-configuration=ipv-4-address=ANY
        so-ad-config:
          socket connection bundle SCB_ECU4_CRN_UDP_Multicast_Rx_fixed_239_2_0_17_40001: socket-connection{client-port=SA_ECU4_CRN_UDP_fixed_10_2_1_1_40001_Remote, pdus=socket-connection-ipdu-identifier={header-id=973242368, pdu-collection-semantics=QUEUED, pdu-triggering=DIAG_C01_ONBD_Container_ST3_DIAG_C01_ONBD_Container_ST3_DIAG_Stat_ST3_ai26rj2l6x4vcdimgt9rtd4lr}, short-label=SC_ECU4_CRN_UDP_fixed_10_2_1_1_40001_Remote}, server-port=SA_ECU4_CRN_UDP_Multicast_Rx_fixed_239_2_0_17_40001
          socket connection bundle SCB_ECU4_CRN_UDP_fixed_10_2_1_4_13400: server-port=SA_ECU4_CRN_UDP_fixed_10_2_1_4_13400
            bundled-connections:
              {client-port=Eth_Cluster4_2/SA_ECU4_CRN_UDP_fixed_255_255_255_255_13400_Remote, pdus=socket-connection-ipdu-identifier={pdu-collection-semantics=QUEUED, pdu-triggering=DIAG_RS_Eth_CTP_4zfaog9k8ca7q3h7nr30e3lyk}, short-label=SC_ECU4_CRN_DoIP_Broad_UDP_fixed_255_255_255_255_13400_Remote}
              {client-port-from-connection-request=true, client-port=Eth_Cluster4_2/SA_ECU4_CRN_UDP_Any_DynamicPort_Remote, pdus=[{pdu-collection-semantics=QUEUED, pdu-triggering=DIAG_RQ_Eth_CTP_36cxv9alsl7ovfjegh7ccgshu}, {pdu-collection-semantics=QUEUED, pdu-triggering=DIAG_RS_Eth_CTP_4wn8ypb98gjeuccwqbke7b5iq}], short-label=SC_ECU4_CRN_UDP_Any_DynamicPort_Remote}
          socket connection bundle SCB_ECU4_CRN_DoIP_TCP_fixed_10_2_1_4_13400: server-port=SA_TCP_fixed_10_2_1_4_13400
            bundled-connections:
              client-ip-addr-from-connection-request=true, client-port-from-connection-request=true, client-port=Eth_Cluster4_2/SA_TCP_Any_DynamicPort, pdus=[DIAG_RQ_Eth_CTP_TCP_SC_ECU4_CRN_TCP_XDIS_5ihozhx5chpshf5e200ea13ho, DIAG_RS_Eth_CTP_TCP_SC_ECU4_CRN_TCP_XDIS_5ihozhx5chpshf5e200ea13ho], short-label=SC_ECU4_CRN_TCP_XDIS_5ihozhx5chpshf5e200ea13ho
              client-ip-addr-from-connection-request=true, client-port-from-connection-request=true, client-port=Eth_Cluster4_2/SA_TCP_Any_13400, pdus=[Eth_Cluster4_2/DIAG_RQ_Eth_CTP_TCP_SC_DoIP_NACK_TCP_Any_13400, Eth_Cluster4_2/DIAG_RS_Eth_CTP_TCP_SC_DoIP_NACK_TCP_Any_13400], short-label=SC_DoIP_NACK_TCP_Any_13400
          8 x socket address:
            SA_ECU4_CRN_UDP_Multicast_Rx_fixed_239_2_0_17_40001: multicast-connector=ECU4_CRN_Eth_Cluster4_a4tivcve7b3dlvxw1emxbqzmz
              application endpoint AE_ECU4_CRN_UDP_Multicast_Rx_fixed_239_2_0_17_40001: network-endpoint=NE_Multicast_Rx_fixed_239_2_0_17, tp-configuration=udp-tp=udp-tp-port=port-number=40001
            SA_ECU4_CRN_UDP_fixed_10_2_1_1_40001_Remote
              application endpoint AE_ECU4_CRN_UDP_fixed_10_2_1_1_40001_Remote: network-endpoint=NE_fixed_10_2_1_1, tp-configuration=udp-tp=udp-tp-port=port-number=40001
            SA_ECU4_CRN_UDP_fixed_10_2_1_4_13400: connector=ECU4_CRN_Eth_Cluster4_a4tivcve7b3dlvxw1emxbqzmz
              application endpoint AE_ECU4_CRN_UDP_fixed_10_2_1_4_13400: network-endpoint=NE_fixed_10_2_1_4, tp-configuration=udp-tp=udp-tp-port=port-number=13400
            SA_ECU4_CRN_UDP_fixed_255_255_255_255_13400_Remote
              application endpoint AE_ECU4_CRN_UDP_fixed_255_255_255_255_13400_Remote: network-endpoint=Eth_Cluster4_2/NE_fixed_255_255_255_255, tp-configuration=udp-tp=udp-tp-port=port-number=13400
            SA_ECU4_CRN_UDP_Any_DynamicPort_Remote
              application endpoint AE_ECU4_CRN_UDP_Any_DynamicPort_Remote: network-endpoint=Eth_Cluster4_2/NE_Any, tp-configuration=udp-tp=udp-tp-port=dynamically-assigned=true
            SA_TCP_fixed_10_2_1_4_13400: connector=ECU4_CRN_Eth_Cluster4_a4tivcve7b3dlvxw1emxbqzmz
              application endpoint AE_TCP_fixed_10_2_1_4_13400: network-endpoint=NE_fixed_10_2_1_4, tp-configuration=tcp-tp=tcp-tp-port=port-number=13400
            SA_TCP_Any_DynamicPort
              application endpoint AE_TCP_Any_DynamicPort: network-endpoint=Eth_Cluster4_2/NE_Any, tp-configuration=tcp-tp=tcp-tp-port=dynamically-assigned=true
            SA_TCP_Any_13400
              application endpoint AE_TCP_Any_13400: network-endpoint=Eth_Cluster4_2/NE_Any, tp-configuration=tcp-tp=tcp-tp-port=port-number=13400
        vlan Eth_Cluster4_2: vlan-identifier=2
      Eth_Cluster4_20: comm-connectors=ECU4_CRN_Eth_Cluster4_3l8iyw65auc022so95pkbhyzp
        pdu triggering COM_C01_Pdu01_PN08_14nchd0xrsp16eatohwyvd0yn: pdu=COM_C01_Pdu01_PN08, to ECU4_CRN
        pdu triggering COM_C01_Pdu01_PN17_t5x7ypqupmw6t1vvvbdfiq1q: pdu=COM_C01_Pdu01_PN17, to ECU4_CRN
        pdu triggering COM_C01_Pdu01_PN44_79jo2y5q2g7vui3dm644yi6a8: pdu=COM_C01_Pdu01_PN44, to ECU4_CRN
        pdu triggering COM_C01_Pdu01_PN53_bn79607brxh5lqo6npnnk39v4: pdu=COM_C01_Pdu01_PN53, to ECU4_CRN
        pdu triggering COM_C01_Pdu01_PN62_3ewvslo65igcqw48k8or945c5: pdu=COM_C01_Pdu01_PN62, to ECU4_CRN
        pdu triggering COM_C04_C08_Pdu02_TpConnection_38mgt7iec7njwdafureyvik07: pdu=COM_C04_C08_Pdu02_TpConnection, from ECU4_CRN
        pdu triggering COM_C04_C14_Pdu01_TpConnection_2suv1h3y7s8zil9mqelpj09fb: pdu=COM_C04_C14_Pdu01_TpConnection, from ECU4_CRN
        pdu triggering COM_C04_Pdu01_PN08_9xfkwwsurl5dz23x6gzupcla0: pdu=PKG_Eth_Cluster4_20/COM_C04_Pdu01_PN08, from ECU4_CRN
        pdu triggering COM_C04_Pdu01_PN17_dyd4zz2qvz0iunxjvi4dz22je: pdu=PKG_Eth_Cluster4_20/COM_C04_Pdu01_PN17, from ECU4_CRN
        pdu triggering COM_C04_Pdu01_PN44_bwqmtrj1w4ncbhb1i3862q7ph: pdu=PKG_Eth_Cluster4_20/COM_C04_Pdu01_PN44, from ECU4_CRN
        pdu triggering COM_C04_Pdu01_PN53_2ow5jv5l0jpimjovzueadkz22: pdu=COM_C04_Pdu01_PN53, from ECU4_CRN
        pdu triggering COM_C04_Pdu01_PN62_8akuj9pa5l45hl8tene7v58yj: pdu=COM_C04_Pdu01_PN62, from ECU4_CRN
        pdu triggering COM_C07_Pdu01_PN08_e7kh7yba4tumnm1xmzc547zxg: pdu=COM_C07_Pdu01_PN08, to ECU4_CRN
        pdu triggering COM_C07_Pdu01_PN44_193fgvg43ycmn2q8rdwahkz7i: pdu=COM_C07_Pdu01_PN44, to ECU4_CRN
        pdu triggering COM_C07_Pdu01_PN53_bxee2qebk053r5722p382iw1r: pdu=COM_C07_Pdu01_PN53, to ECU4_CRN
        pdu triggering COM_C08_C04_Pdu02_TpConnection_ahupw1o3wkhij3htd6mdolsex: pdu=COM_C08_C04_Pdu02_TpConnection, to ECU4_CRN
        pdu triggering COM_C14_C04_Pdu01_TpConnection_99bzc1cznv5p7ploau5n3z3zj: pdu=COM_C14_C04_Pdu01_TpConnection, to ECU4_CRN
        pdu triggering DI_OdoSpeedometer_ST3_7jb3acjj567zcinfjaciyzmox: pdu=DI_OdoSpeedometer_ST3, to ECU4_CRN
        pdu triggering DI_OdoSpeedometer_ST3_6dk4m56tw8zae1rhfo9kqar8l: pdu=DI_OdoSpeedometer_ST3_secured, to ECU4_CRN
        pdu triggering Ign_Stat_ST3_30i7ve981yksfyg7upd5w1x1e: pdu=PKG_Eth_Cluster4_20/Ign_Stat_ST3, to ECU4_CRN
        pdu triggering Ign_Stat_ST3_323m4iypknq8f8i8a46eo81mh: pdu=PKG_Eth_Cluster4_20/Ign_Stat_ST3_secured, to ECU4_CRN
        pdu triggering PN14_Master_Stat1_ST3_1c1yt5wkb7eltvmd1nhzl575e: pdu=PN14_Master_Stat1_ST3, to ECU4_CRN
        pdu triggering PN14_Master_Stat1_ST3_7bsnhlhyrlzz28b3fagttaog4: pdu=PN14_Master_Stat1_ST3_secured, to ECU4_CRN
        pdu triggering PT4_PTCoor4_ST3_1rx6hv5wn01u44037z5f7jia2: pdu=PT4_PTCoor4_ST3, to ECU4_CRN
        pdu triggering PT4_PTCoor4_ST3_7w1aheif1ybq7bpqs3bcbtqsf: pdu=PT4_PTCoor4_ST3_secured, to ECU4_CRN
        pdu triggering VSS_TP_Auth_ST3_brlg54e6j6ut3jgrbyrvds5r1: pdu=PKG_Eth_Cluster4_20/VSS_TP_Auth_ST3, to ECU4_CRN
        pdu triggering VSS_TP_RealTmOffset_ST3_4ref1poho6hv4l0gks5bbceub: pdu=PKG_Eth_Cluster4_20/VSS_TP_RealTmOffset_ST3, to ECU4_CRN
        pdu triggering VSS_TP_SecTickCount_Lvl1_ST3_de7lqhsqtn1u4kjz85fjvrjll: pdu=VSS_TP_SecTickCount_Lvl1_ST3, to ECU4_CRN
        pdu triggering VSS_TP_SharedSecret_ST3_107qjbgt3r0kjosska3jxxrb9: pdu=PKG_Eth_Cluster4_20/VSS_TP_SharedSecret_ST3, to ECU4_CRN
        pdu triggering VSS_TP_VIN_ST3_6rtjf8y29spxl705nvbfxtc9t: pdu=PKG_Eth_Cluster4_20/VSS_TP_VIN_ST3, to ECU4_CRN
        pdu triggering COM_C04_Pdu02_b7b80koapl4g7495qodougyua: pdu=COM_C04_Pdu02, from ECU4_CRN
        pdu triggering COM_C04_Pdu02_Call_6fdemzkhykz9nccnggqbr6j2g: pdu=COM_C04_Pdu02_Call, to ECU4_CRN
        pdu triggering COM_C04_Pdu03_bpm1c6e6o44uhe1w6yumyf8wa: pdu=COM_C04_Pdu03, from ECU4_CRN
        pdu triggering COM_C04_Pdu03_ee8amlymwx093h6g6qybwhgyu: pdu=COM_C04_Pdu03_secured, from ECU4_CRN
        pdu triggering VehSpd_8_ST3_rw4rwzepv4zq3afl7px8fqvx: pdu=VehSpd_8_ST3, to ECU4_CRN
        pdu triggering VehSpd_8_ST3_lvrrj7faag04zml4ehjh0nq4: pdu=VehSpd_8_ST3_secured, to ECU4_CRN
        pdu triggering COM_C04_Pdu10_erod9kvk36fdl7uszv8ct7ly3: pdu=COM_C04_Pdu10, from ECU4_CRN
        pdu triggering COM_C04_Pdu11_b2vr7gb4fbovbo7a82cc99g5l: pdu=COM_C04_Pdu11, from ECU4_CRN
        pdu triggering COM_C04_Pdu12_694wnjkk2c76ymtfqqtfny3oy: pdu=COM_C04_Pdu12, from ECU4_CRN
        pdu triggering COM_C04_Pdu13_rro8jh3ligzel60xvn5stk66: pdu=COM_C04_Pdu13, from ECU4_CRN
        pdu triggering COM_C04_Pdu14_91aobymftfp4im9g50r12g4w7: pdu=COM_C04_Pdu14, from ECU4_CRN
        pdu triggering COM_C04_Pdu15_36kogvjrphv5uhgliggs4fgyy: pdu=COM_C04_Pdu15, from ECU4_CRN
        pdu triggering COM_C04_Pdu16_4sqcx4cxbiooq3eo7th24hsv8: pdu=COM_C04_Pdu16, from ECU4_CRN
        pdu triggering COM_C04_Pdu17_3p34yat25qrg7x8cu11w6lb8y: pdu=COM_C04_Pdu17, from ECU4_CRN
        pdu triggering COM_C04_Pdu18_15otxcsgh4z345of59njrx4j5: pdu=COM_C04_Pdu18, from ECU4_CRN
        pdu triggering COM_C04_Pdu19_5qytogopzq6pxkd8la5uyb3zn: pdu=COM_C04_Pdu19, from ECU4_CRN
        pdu triggering COM_C04_Pdu20_9id8jbpo37ngpr9vzagg7wxtz: pdu=COM_C04_Pdu20, from ECU4_CRN
        pdu triggering COM_C04_Pdu20_23k4flf2cc5dnz7yqehkllajo: pdu=COM_C04_Pdu20_secured, from ECU4_CRN
        pdu triggering COM_C04_Pdu21_483xtibj7phlywn0mrpsj0p4u: pdu=COM_C04_Pdu21, from ECU4_CRN
        pdu triggering COM_C04_Pdu21_eb0pqzdto0c4dh129x7n7b0bm: pdu=COM_C04_Pdu21_secured, from ECU4_CRN
        pdu triggering COM_C0X_Pdu10_78pflb0dh807b7g4sj26x9nxn: pdu=COM_C0X_Pdu10, to ECU4_CRN
        pdu triggering COM_C0X_Pdu11_96p7zk2fk1ycqwn7z9eoypj37: pdu=COM_C0X_Pdu11, to ECU4_CRN
        pdu triggering COM_C0X_Pdu12_9d33ltenthreeih3018061do8: pdu=COM_C0X_Pdu12, to ECU4_CRN
        pdu triggering COM_C0X_Pdu13_bx0r89ifrdctz8gbavwlv3vza: pdu=COM_C0X_Pdu13, to ECU4_CRN
        pdu triggering COM_C0X_Pdu14_34r3khbc2vm54zao5ln016daw: pdu=COM_C0X_Pdu14, to ECU4_CRN
        pdu triggering COM_C0X_Pdu15_5ij249g44iv5zya2pneoifwni: pdu=COM_C0X_Pdu15, to ECU4_CRN
        pdu triggering COM_C0X_Pdu16_3f1v9nrhmarb9dws1h2jbee0b: pdu=COM_C0X_Pdu16, to ECU4_CRN
        pdu triggering COM_C0X_Pdu17_14bidtywh5l2p3q3fovab8ka9: pdu=COM_C0X_Pdu17, to ECU4_CRN
        pdu triggering COM_C0X_Pdu18_88czwl82bbw5mwmq8lydbq9cu: pdu=COM_C0X_Pdu18, to ECU4_CRN
        pdu triggering COM_C0X_Pdu19_74kb362y50jt1pcwosz97j0uk: pdu=COM_C0X_Pdu19, to ECU4_CRN
        pdu triggering COM_C0X_Pdu20_dqc5kce35r6zcc0zkw8xmpfiv: pdu=COM_C0X_Pdu20, to ECU4_CRN
        pdu triggering COM_C0X_Pdu20_6gautmu8u3v0gfc0bjkiaecqn: pdu=COM_C0X_Pdu20_secured, to ECU4_CRN
        pdu triggering COM_C0X_Pdu21_bm3n8flkrwzfl90nw3nm3vvzs: pdu=COM_C0X_Pdu21, to ECU4_CRN
        pdu triggering COM_C0X_Pdu21_4upg7bmsgn7yrmvfjv7sk904t: pdu=COM_C0X_Pdu21_secured, to ECU4_CRN
        pdu triggering CANFD_Eth_ST3_TPA_7ek96ff2ffqu2r1f6vuo3klkz: pdu=CANFD_Eth_ST3_TPA, from ECU4_CRN
        pdu triggering Eth_CANFD_ST3_TPA_4j0ewx68js6iny6awlpfddx9g: pdu=Eth_CANFD_ST3_TPA, to ECU4_CRN
        pdu triggering ECU4_CRN_SD_Ctrl_Rx_TRIGGERING: pdu=SD_Ctrl_Rx, to ECU4_CRN
        pdu triggering ECU4_CRN_SD_Ctrl_Rx_Multicast_TRIGGERING: pdu=SD_Ctrl_Rx_Multicast, to ECU4_CRN
        pdu triggering ECU4_CRN_SD_Ctrl_Tx_TRIGGERING: pdu=SD_Ctrl_Tx, from ECU4_CRN
        7 x network endpoint:
          NE_fixed_10_20_1_1: network-endpoint-addresses=ipv-4-configuration={ipv-4-address=10.20.1.1, ipv-4-address-source=FIXED, network-mask=255.255.0.0, ttl=1}, priority=5
          NE_fixed_10_20_1_4: network-endpoint-addresses=ipv-4-configuration={ipv-4-address=10.20.1.4, ipv-4-address-source=FIXED, network-mask=255.255.0.0, ttl=1}, priority=5
          NE_fixed_10_20_1_7: network-endpoint-addresses=ipv-4-configuration={ipv-4-address=10.20.1.7, ipv-4-address-source=FIXED, network-mask=255.255.0.0, ttl=1}, priority=5
          NE_Multicast_Rx_Any: network-endpoint-addresses=ipv-4-configuration=ipv-4-address=239.20.0.3
          NE_Multicast_Rx_fixed_239_20_0_3: network-endpoint-addresses=ipv-4-configuration={ipv-4-address=239.20.0.3, ipv-4-address-source=FIXED}
          NE_Any: network-endpoint-addresses=ipv-4-configuration=ipv-4-address=ANY
          NE_Multicast_Rx_fixed_239_20_0_2: network-endpoint-addresses=ipv-4-configuration={ipv-4-address=239.20.0.2, ipv-4-address-source=FIXED}
        so-ad-config:
          23 x socket connection bundle:
            SCB_TCP_fixed_10_20_1_1_50022: socket-connection{client-port=SA_TCP_fixed_10_20_1_4_50022, pdus=socket-connection-ipdu-identifier={header-id=4261494788, pdu-collection-semantics=QUEUED, pdu-triggering=COM_C14_C04_Pdu01_TpConnection_99bzc1cznv5p7ploau5n3z3zj}, short-label=SC_ECU4_CRN_TCP_fixed_10_20_1_4_50022}, server-port=SA_TCP_fixed_10_20_1_1_50022
            SCB_TCP_fixed_10_20_1_1_50031: socket-connection{client-port=SA_TCP_fixed_10_20_1_4_50031, pdus=socket-connection-ipdu-identifier={header-id=4261445636, pdu-collection-semantics=QUEUED, pdu-triggering=COM_C08_C04_Pdu02_TpConnection_ahupw1o3wkhij3htd6mdolsex}, short-label=SC_ECU4_CRN_TCP_fixed_10_20_1_4_50031}, server-port=SA_TCP_fixed_10_20_1_1_50031
            SCB_ECU4_CRN_UDP_fixed_10_20_1_4_50001: socket-connection{client-port=SA_ECU4_CRN_UDP_fixed_10_20_1_1_50001_Remote, pdus=socket-connection-ipdu-identifier={pdu-collection-semantics=QUEUED, pdu-triggering=COM_C01_Pdu01_PN08_14nchd0xrsp16eatohwyvd0yn}, short-label=SC_ECU4_CRN_UDP_fixed_10_20_1_1_50001_Remote}, server-port=SA_ECU4_CRN_UDP_fixed_10_20_1_4_50001
            SCB_ECU4_CRN_UDP_fixed_10_20_1_4_50002: socket-connection{client-port=SA_ECU4_CRN_UDP_fixed_10_20_1_1_50002_Remote, pdus=socket-connection-ipdu-identifier={pdu-collection-semantics=QUEUED, pdu-triggering=COM_C01_Pdu01_PN17_t5x7ypqupmw6t1vvvbdfiq1q}, short-label=SC_ECU4_CRN_UDP_fixed_10_20_1_1_50002_Remote}, server-port=SA_ECU4_CRN_UDP_fixed_10_20_1_4_50002
            SCB_ECU4_CRN_UDP_fixed_10_20_1_4_50005: socket-connection{client-port=SA_ECU4_CRN_UDP_fixed_10_20_1_1_50005_Remote, pdus=socket-connection-ipdu-identifier={pdu-collection-semantics=QUEUED, pdu-triggering=COM_C01_Pdu01_PN44_79jo2y5q2g7vui3dm644yi6a8}, short-label=SC_ECU4_CRN_UDP_fixed_10_20_1_1_50005_Remote}, server-port=SA_ECU4_CRN_UDP_fixed_10_20_1_4_50005
            SCB_ECU4_CRN_UDP_fixed_10_20_1_4_50006: socket-connection{client-port=SA_ECU4_CRN_UDP_fixed_10_20_1_1_50006_Remote, pdus=socket-connection-ipdu-identifier={pdu-collection-semantics=QUEUED, pdu-triggering=COM_C01_Pdu01_PN53_bn79607brxh5lqo6npnnk39v4}, short-label=SC_ECU4_CRN_UDP_fixed_10_20_1_1_50006_Remote}, server-port=SA_ECU4_CRN_UDP_fixed_10_20_1_4_50006
            SCB_ECU4_CRN_UDP_fixed_10_20_1_4_50007: socket-connection{client-port=SA_ECU4_CRN_UDP_fixed_10_20_1_1_50007_Remote, pdus=socket-connection-ipdu-identifier={pdu-collection-semantics=QUEUED, pdu-triggering=COM_C01_Pdu01_PN62_3ewvslo65igcqw48k8or945c5}, short-label=SC_ECU4_CRN_UDP_fixed_10_20_1_1_50007_Remote}, server-port=SA_ECU4_CRN_UDP_fixed_10_20_1_4_50007
            SCB_ECU4_CRN_UDP_fixed_10_20_1_4_50013: server-port=SA_ECU4_CRN_UDP_fixed_10_20_1_4_50013
              bundled-connections:
                {client-port=SA_ECU4_CRN_UDP_fixed_10_20_1_1_50013_Remote, pdus=socket-connection-ipdu-identifier={pdu-collection-semantics=QUEUED, pdu-triggering=COM_C04_Pdu01_PN08_9xfkwwsurl5dz23x6gzupcla0}, short-label=SC_ECU4_CRN_UDP_fixed_10_20_1_1_50013_Remote}
                {client-port=SA_ECU4_CRN_UDP_fixed_10_20_1_7_50013_Remote, pdus=socket-connection-ipdu-identifier={pdu-collection-semantics=QUEUED, pdu-triggering=COM_C04_Pdu01_PN08_9xfkwwsurl5dz23x6gzupcla0}, short-label=SC_ECU4_CRN_UDP_fixed_10_20_1_7_50013_Remote}
            SCB_ECU4_CRN_UDP_fixed_10_20_1_4_50014: socket-connection{client-port=SA_ECU4_CRN_UDP_fixed_10_20_1_1_50014_Remote, pdus=socket-connection-ipdu-identifier={pdu-collection-semantics=QUEUED, pdu-triggering=COM_C04_Pdu01_PN17_dyd4zz2qvz0iunxjvi4dz22je}, short-label=SC_ECU4_CRN_UDP_fixed_10_20_1_1_50014_Remote}, server-port=SA_ECU4_CRN_UDP_fixed_10_20_1_4_50014
            SCB_ECU4_CRN_UDP_fixed_10_20_1_4_50015: server-port=SA_ECU4_CRN_UDP_fixed_10_20_1_4_50015
              bundled-connections:
                {client-port=SA_ECU4_CRN_UDP_fixed_10_20_1_1_50015_Remote, pdus=socket-connection-ipdu-identifier={pdu-collection-semantics=QUEUED, pdu-triggering=COM_C04_Pdu01_PN44_bwqmtrj1w4ncbhb1i3862q7ph}, short-label=SC_ECU4_CRN_UDP_fixed_10_20_1_1_50015_Remote}
                {client-port=SA_ECU4_CRN_UDP_fixed_10_20_1_7_50015_Remote, pdus=socket-connection-ipdu-identifier={pdu-collection-semantics=QUEUED, pdu-triggering=COM_C04_Pdu01_PN44_bwqmtrj1w4ncbhb1i3862q7ph}, short-label=SC_ECU4_CRN_UDP_fixed_10_20_1_7_50015_Remote}
            SCB_ECU4_CRN_UDP_fixed_10_20_1_4_50016: server-port=SA_ECU4_CRN_UDP_fixed_10_20_1_4_50016
              bundled-connections:
                {client-port=SA_ECU4_CRN_UDP_fixed_10_20_1_1_50016_Remote, pdus=socket-connection-ipdu-identifier={pdu-collection-semantics=QUEUED, pdu-triggering=COM_C04_Pdu01_PN53_2ow5jv5l0jpimjovzueadkz22}, short-label=SC_ECU4_CRN_UDP_fixed_10_20_1_1_50016_Remote}
                {client-port=SA_ECU4_CRN_UDP_fixed_10_20_1_7_50016_Remote, pdus=socket-connection-ipdu-identifier={pdu-collection-semantics=QUEUED, pdu-triggering=COM_C04_Pdu01_PN53_2ow5jv5l0jpimjovzueadkz22}, short-label=SC_ECU4_CRN_UDP_fixed_10_20_1_7_50016_Remote}
            SCB_ECU4_CRN_UDP_fixed_10_20_1_4_50017: socket-connection{client-port=SA_ECU4_CRN_UDP_fixed_10_20_1_1_50017_Remote, pdus=socket-connection-ipdu-identifier={pdu-collection-semantics=QUEUED, pdu-triggering=COM_C04_Pdu01_PN62_8akuj9pa5l45hl8tene7v58yj}, short-label=SC_ECU4_CRN_UDP_fixed_10_20_1_1_50017_Remote}, server-port=SA_ECU4_CRN_UDP_fixed_10_20_1_4_50017
            SCB_ECU4_CRN_TCP_fixed_10_20_1_4_50021: socket-connection{client-port=SA_TCP_fixed_10_20_1_1_50021, pdus=socket-connection-ipdu-identifier={header-id=4261429268, pdu-collection-semantics=QUEUED, pdu-triggering=COM_C04_C14_Pdu01_TpConnection_2suv1h3y7s8zil9mqelpj09fb}, short-label=SC_ECU1_CRN_TCP_fixed_10_20_1_1_50021}, server-port=SA_TCP_fixed_10_20_1_4_50021
            SCB_ECU4_CRN_TCP_fixed_10_20_1_4_50030: server-port=SA_TCP_fixed_10_20_1_4_50030
              bundled-connections:
                {client-port=SA_TCP_fixed_10_20_1_1_50030, pdus=socket-connection-ipdu-identifier={header-id=4261429256, pdu-collection-semantics=QUEUED, pdu-triggering=COM_C04_C08_Pdu02_TpConnection_38mgt7iec7njwdafureyvik07}, short-label=SC_ECU1_CRN_TCP_fixed_10_20_1_1_50030}
                {client-port=SA_ECU4_CRN_UDP_fixed_10_20_1_7_50030_Remote, pdus=socket-connection-ipdu-identifier={header-id=268992513, pdu-collection-semantics=QUEUED, pdu-triggering=COM_C07_Pdu01_PN08_e7kh7yba4tumnm1xmzc547zxg}, short-label=SC_ECU4_CRN_UDP_fixed_10_20_1_7_50030_Remote}
            SCB_ECU4_CRN_UDP_fixed_10_20_1_4_50031: socket-connection{client-port=SA_ECU4_CRN_UDP_fixed_10_20_1_7_50031_Remote, pdus=socket-connection-ipdu-identifier={header-id=268992514, pdu-collection-semantics=QUEUED, pdu-triggering=COM_C07_Pdu01_PN44_193fgvg43ycmn2q8rdwahkz7i}, short-label=SC_ECU4_CRN_UDP_fixed_10_20_1_7_50031_Remote}, server-port=SA_ECU4_CRN_UDP_fixed_10_20_1_4_50031
            SCB_ECU4_CRN_UDP_fixed_10_20_1_4_50032: socket-connection{client-port=SA_ECU4_CRN_UDP_fixed_10_20_1_7_50032_Remote, pdus=socket-connection-ipdu-identifier={header-id=268992515, pdu-collection-semantics=QUEUED, pdu-triggering=COM_C07_Pdu01_PN53_bxee2qebk053r5722p382iw1r}, short-label=SC_ECU4_CRN_UDP_fixed_10_20_1_7_50032_Remote}, server-port=SA_ECU4_CRN_UDP_fixed_10_20_1_4_50032
            SCB_ECU4_CRN_UDP_fixed_10_20_1_4_40000: server-port=SA_ECU4_CRN_UDP_fixed_10_20_1_4_40000
              bundled-connections:
                client-port=SA_ECU4_CRN_UDP_Multicast_fixed_239_20_0_3_40000_Remote, pdu-collection-max-buffer-size=1472, pdu-collection-timeout=0.01, short-label=SC_ECU4_CRN_UDP_Multicast_fixed_239_20_0_3_40000_Remote
                client-ip-addr-from-connection-request=true, client-port-from-connection-request=true, client-port=Eth_Cluster4_20/SA_ECU4_CRN_UDP_Any_DynamicPort_Remote, pdu-collection-max-buffer-size=1472, pdu-collection-timeout=0.01, runtime-ip-address-configuration=SD, runtime-port-configuration=SD, short-label=SC_ECU4_CRN_{0..6}_UDP_Any_DynamicPort_Remote
              pdus:
                header-id=1090551808, pdu-collection-semantics=QUEUED, pdu-collection-trigger=NEVER, pdu-triggering=VSS_TP_VIN_ST3_6rtjf8y29spxl705nvbfxtc9t, routing-group=Service_Id_16640_SI_ID_0_VSS_ACT
                header-id=1090551809, pdu-collection-semantics=QUEUED, pdu-collection-trigger=NEVER, pdu-triggering=VSS_TP_Auth_ST3_brlg54e6j6ut3jgrbyrvds5r1, routing-group=Service_Id_16640_SI_ID_0_VSS_ACT
                header-id=1090551811, pdu-collection-semantics=QUEUED, pdu-collection-trigger=NEVER, pdu-triggering=VSS_TP_SharedSecret_ST3_107qjbgt3r0kjosska3jxxrb9, routing-group=Service_Id_16640_SI_ID_0_VSS_ACT
                header-id=1090551810, pdu-collection-semantics=QUEUED, pdu-collection-trigger=NEVER, pdu-triggering=VSS_TP_RealTmOffset_ST3_4ref1poho6hv4l0gks5bbceub, routing-group=Service_Id_16640_SI_ID_0_VSS_ACT
                header-id=1090551812, pdu-collection-semantics=QUEUED, pdu-collection-trigger=NEVER, pdu-triggering=VSS_TP_SecTickCount_Lvl1_ST3_de7lqhsqtn1u4kjz85fjvrjll, routing-group=Service_Id_16640_SI_ID_0_VSS_ACT
                header-id=956596230, pdu-collection-semantics=QUEUED, pdu-collection-trigger=NEVER, pdu-triggering=PT4_PTCoor4_ST3_7w1aheif1ybq7bpqs3bcbtqsf, routing-group=Service_Id_14596_SI_ID_0_PT4_PTCoor4_AC
                header-id=67174401, pdu-collection-semantics=QUEUED, pdu-collection-trigger=NEVER, pdu-triggering=COM_C04_Pdu02_Call_6fdemzkhykz9nccnggqbr6j2g, routing-group=Service_1025_SI_ID_1_Methods
                header-id=511868937, pdu-collection-semantics=QUEUED, pdu-collection-trigger=NEVER, pdu-triggering=VehSpd_8_ST3_lvrrj7faag04zml4ehjh0nq4, routing-group=Service_Id_7810_SI_ID_1_Vehspd_8_AC
                header-id=839155712, pdu-collection-semantics=QUEUED, pdu-collection-trigger=NEVER, pdu-triggering=DI_OdoSpeedometer_ST3_6dk4m56tw8zae1rhfo9kqar8l, routing-group=Service_Id_12804_SI_ID_0_DI_Master_Odometer_AC
                header-id=269778965, pdu-collection-semantics=QUEUED, pdu-collection-trigger=NEVER, pdu-triggering=COM_C04_Pdu15_36kogvjrphv5uhgliggs4fgyy, routing-group=[Service_Id_4116_SI_ID_10_Event_1_AC, Service_Id_4116_SI_ID_10_Event_1_AM, Service_Id_4116_SI_ID_10_Event_2_AC, Service_Id_4116_SI_ID_10_Event_2_AM]
                header-id=269778968, pdu-collection-semantics=QUEUED, pdu-collection-trigger=NEVER, pdu-triggering=COM_C04_Pdu18_15otxcsgh4z345of59njrx4j5, routing-group=[Service_Id_4116_SI_ID_10_Event_1_AC, Service_Id_4116_SI_ID_10_Event_1_AM]
                header-id=269778969, pdu-collection-semantics=QUEUED, pdu-collection-trigger=NEVER, pdu-triggering=COM_C04_Pdu19_5qytogopzq6pxkd8la5uyb3zn, routing-group=[Service_Id_4116_SI_ID_10_Event_1_AC, Service_Id_4116_SI_ID_10_Event_1_AM]
                header-id=269778962, pdu-collection-semantics=QUEUED, pdu-collection-trigger=NEVER, pdu-triggering=COM_C04_Pdu12_694wnjkk2c76ymtfqqtfny3oy, routing-group=[Service_Id_4116_SI_ID_10_Event_1_AC, Service_Id_4116_SI_ID_10_Event_1_AM, Service_Id_4116_SI_ID_10_Event_2_AC, Service_Id_4116_SI_ID_10_Event_2_AM]
                header-id=269778966, pdu-collection-semantics=QUEUED, pdu-collection-trigger=NEVER, pdu-triggering=COM_C04_Pdu16_4sqcx4cxbiooq3eo7th24hsv8, routing-group=[Service_Id_4116_SI_ID_10_Event_1_AC, Service_Id_4116_SI_ID_10_Event_1_AM]
                header-id=269778961, pdu-collection-semantics=QUEUED, pdu-collection-trigger=NEVER, pdu-triggering=COM_C04_Pdu11_b2vr7gb4fbovbo7a82cc99g5l, routing-group=[Service_Id_4116_SI_ID_10_Event_1_AC, Service_Id_4116_SI_ID_10_Event_1_AM, Service_Id_4116_SI_ID_10_Event_2_AC, Service_Id_4116_SI_ID_10_Event_2_AM]
                header-id=269778960, pdu-collection-semantics=QUEUED, pdu-collection-trigger=NEVER, pdu-triggering=COM_C04_Pdu10_erod9kvk36fdl7uszv8ct7ly3, routing-group=[Service_Id_4116_SI_ID_10_Event_1_AC, Service_Id_4116_SI_ID_10_Event_1_AM]
                header-id=269778976, pdu-collection-semantics=QUEUED, pdu-collection-trigger=NEVER, pdu-triggering=COM_C04_Pdu20_23k4flf2cc5dnz7yqehkllajo, routing-group=[Service_Id_4116_SI_ID_10_Event_1_AC, Service_Id_4116_SI_ID_10_Event_1_AM]
                header-id=269778964, pdu-collection-semantics=QUEUED, pdu-collection-trigger=NEVER, pdu-triggering=COM_C04_Pdu14_91aobymftfp4im9g50r12g4w7, routing-group=[Service_Id_4116_SI_ID_10_Event_1_AC, Service_Id_4116_SI_ID_10_Event_1_AM, Service_Id_4116_SI_ID_10_Event_2_AC, Service_Id_4116_SI_ID_10_Event_2_AM]
                header-id=269778963, pdu-collection-semantics=QUEUED, pdu-collection-trigger=NEVER, pdu-triggering=COM_C04_Pdu13_rro8jh3ligzel60xvn5stk66, routing-group=[Service_Id_4116_SI_ID_10_Event_1_AC, Service_Id_4116_SI_ID_10_Event_1_AM, Service_Id_4116_SI_ID_10_Event_2_AC, Service_Id_4116_SI_ID_10_Event_2_AM]
                header-id=269778967, pdu-collection-semantics=QUEUED, pdu-collection-trigger=NEVER, pdu-triggering=COM_C04_Pdu17_3p34yat25qrg7x8cu11w6lb8y, routing-group=[Service_Id_4116_SI_ID_10_Event_1_AC, Service_Id_4116_SI_ID_10_Event_1_AM]
                header-id=269778977, pdu-collection-semantics=QUEUED, pdu-collection-trigger=NEVER, pdu-triggering=COM_C04_Pdu21_eb0pqzdto0c4dh129x7n7b0bm, routing-group=[Service_Id_4116_SI_ID_10_Event_1_AC, Service_Id_4116_SI_ID_10_Event_1_AM]
                header-id=964722688, pdu-collection-semantics=QUEUED, pdu-collection-trigger=NEVER, pdu-triggering=PN14_Master_Stat1_ST3_7bsnhlhyrlzz28b3fagttaog4, routing-group=Service_Id_14720_SI_ID_0_PN14_Master_AC
                header-id=278167571, pdu-collection-semantics=QUEUED, pdu-collection-trigger=NEVER, pdu-triggering=COM_C0X_Pdu13_bx0r89ifrdctz8gbavwlv3vza, routing-group=[Service_Id_4244_SI_ID_10_Event_1_AC, Service_Id_4244_SI_ID_10_Event_2_AC]
                header-id=278167575, pdu-collection-semantics=QUEUED, pdu-collection-trigger=NEVER, pdu-triggering=COM_C0X_Pdu17_14bidtywh5l2p3q3fovab8ka9, routing-group=Service_Id_4244_SI_ID_10_Event_1_AC
                header-id=278167572, pdu-collection-semantics=QUEUED, pdu-collection-trigger=NEVER, pdu-triggering=COM_C0X_Pdu14_34r3khbc2vm54zao5ln016daw, routing-group=[Service_Id_4244_SI_ID_10_Event_1_AC, Service_Id_4244_SI_ID_10_Event_2_AC]
                header-id=278167585, pdu-collection-semantics=QUEUED, pdu-collection-trigger=NEVER, pdu-triggering=COM_C0X_Pdu21_4upg7bmsgn7yrmvfjv7sk904t, routing-group=Service_Id_4244_SI_ID_10_Event_1_AC
                header-id=278167573, pdu-collection-semantics=QUEUED, pdu-collection-trigger=NEVER, pdu-triggering=COM_C0X_Pdu15_5ij249g44iv5zya2pneoifwni, routing-group=[Service_Id_4244_SI_ID_10_Event_1_AC, Service_Id_4244_SI_ID_10_Event_2_AC]
                header-id=278167576, pdu-collection-semantics=QUEUED, pdu-collection-trigger=NEVER, pdu-triggering=COM_C0X_Pdu18_88czwl82bbw5mwmq8lydbq9cu, routing-group=Service_Id_4244_SI_ID_10_Event_1_AC
                header-id=278167570, pdu-collection-semantics=QUEUED, pdu-collection-trigger=NEVER, pdu-triggering=COM_C0X_Pdu12_9d33ltenthreeih3018061do8, routing-group=[Service_Id_4244_SI_ID_10_Event_1_AC, Service_Id_4244_SI_ID_10_Event_2_AC]
                header-id=278167574, pdu-collection-semantics=QUEUED, pdu-collection-trigger=NEVER, pdu-triggering=COM_C0X_Pdu16_3f1v9nrhmarb9dws1h2jbee0b, routing-group=Service_Id_4244_SI_ID_10_Event_1_AC
                header-id=278167577, pdu-collection-semantics=QUEUED, pdu-collection-trigger=NEVER, pdu-triggering=COM_C0X_Pdu19_74kb362y50jt1pcwosz97j0uk, routing-group=Service_Id_4244_SI_ID_10_Event_1_AC
                header-id=278167568, pdu-collection-semantics=QUEUED, pdu-collection-trigger=NEVER, pdu-triggering=COM_C0X_Pdu10_78pflb0dh807b7g4sj26x9nxn, routing-group=Service_Id_4244_SI_ID_10_Event_1_AC
                header-id=278167569, pdu-collection-semantics=QUEUED, pdu-collection-trigger=NEVER, pdu-triggering=COM_C0X_Pdu11_96p7zk2fk1ycqwn7z9eoypj37, routing-group=[Service_Id_4244_SI_ID_10_Event_1_AC, Service_Id_4244_SI_ID_10_Event_2_AC]
                header-id=278167584, pdu-collection-semantics=QUEUED, pdu-collection-trigger=NEVER, pdu-triggering=COM_C0X_Pdu20_6gautmu8u3v0gfc0bjkiaecqn, routing-group=Service_Id_4244_SI_ID_10_Event_1_AC
                header-id=67174401, pdu-collection-pdu-timeout=0, pdu-collection-semantics=QUEUED, pdu-collection-trigger=ALWAYS, pdu-triggering=COM_C04_Pdu02_b7b80koapl4g7495qodougyua, routing-group=Service_1025_SI_ID_1_Methods
                header-id=8421376, pdu-collection-semantics=QUEUED, pdu-collection-trigger=NEVER, pdu-triggering=Ign_Stat_ST3_323m4iypknq8f8i8a46eo81mh, routing-group=Service_Id_128_SI_ID_0_Ign_Stat_ACT
            SCB_ECU4_CRN_UDP_Multicast_Rx_Any_40000: socket-connection{client-ip-addr-from-connection-request=true, client-port-from-connection-request=true, client-port=Eth_Cluster4_20/SA_ECU4_CRN_UDP_Any_DynamicPort_Remote, runtime-ip-address-configuration=SD, runtime-port-configuration=SD, short-label=SC_ECU4_CRN_UDP_Any_DynamicPort_Remote}, server-port=SA_ECU4_CRN_UDP_Multicast_Rx_Any_40000
              pdus:
                header-id=1090551808, pdu-collection-semantics=QUEUED, pdu-triggering=VSS_TP_VIN_ST3_6rtjf8y29spxl705nvbfxtc9t, routing-group=Service_Id_16640_SI_ID_0_VSS_AM
                header-id=1090551809, pdu-collection-semantics=QUEUED, pdu-triggering=VSS_TP_Auth_ST3_brlg54e6j6ut3jgrbyrvds5r1, routing-group=Service_Id_16640_SI_ID_0_VSS_AM
                header-id=1090551811, pdu-collection-semantics=QUEUED, pdu-triggering=VSS_TP_SharedSecret_ST3_107qjbgt3r0kjosska3jxxrb9, routing-group=Service_Id_16640_SI_ID_0_VSS_AM
                header-id=1090551810, pdu-collection-semantics=QUEUED, pdu-triggering=VSS_TP_RealTmOffset_ST3_4ref1poho6hv4l0gks5bbceub, routing-group=Service_Id_16640_SI_ID_0_VSS_AM
                header-id=1090551812, pdu-collection-semantics=QUEUED, pdu-triggering=VSS_TP_SecTickCount_Lvl1_ST3_de7lqhsqtn1u4kjz85fjvrjll, routing-group=Service_Id_16640_SI_ID_0_VSS_AM
                header-id=956596230, pdu-collection-semantics=QUEUED, pdu-triggering=PT4_PTCoor4_ST3_7w1aheif1ybq7bpqs3bcbtqsf, routing-group=Service_Id_14596_SI_ID_0_PT4_PTCoor4_AM
                header-id=511868937, pdu-collection-semantics=QUEUED, pdu-triggering=VehSpd_8_ST3_lvrrj7faag04zml4ehjh0nq4, routing-group=Service_Id_7810_SI_ID_1_Vehspd_8_AM
                header-id=839155712, pdu-collection-semantics=QUEUED, pdu-triggering=DI_OdoSpeedometer_ST3_6dk4m56tw8zae1rhfo9kqar8l
                header-id=964722688, pdu-collection-semantics=QUEUED, pdu-triggering=PN14_Master_Stat1_ST3_7bsnhlhyrlzz28b3fagttaog4, routing-group=Service_Id_14720_SI_ID_0_PN14_Master_AM
                header-id=278167571, pdu-collection-semantics=QUEUED, pdu-triggering=COM_C0X_Pdu13_bx0r89ifrdctz8gbavwlv3vza, routing-group=[Service_Id_4244_SI_ID_10_Event_1_AM, Service_Id_4244_SI_ID_10_Event_2_AM]
                header-id=278167575, pdu-collection-semantics=QUEUED, pdu-triggering=COM_C0X_Pdu17_14bidtywh5l2p3q3fovab8ka9, routing-group=Service_Id_4244_SI_ID_10_Event_1_AM
                header-id=278167572, pdu-collection-semantics=QUEUED, pdu-triggering=COM_C0X_Pdu14_34r3khbc2vm54zao5ln016daw, routing-group=[Service_Id_4244_SI_ID_10_Event_1_AM, Service_Id_4244_SI_ID_10_Event_2_AM]
                header-id=278167585, pdu-collection-semantics=QUEUED, pdu-triggering=COM_C0X_Pdu21_4upg7bmsgn7yrmvfjv7sk904t, routing-group=Service_Id_4244_SI_ID_10_Event_1_AM
                header-id=278167573, pdu-collection-semantics=QUEUED, pdu-triggering=COM_C0X_Pdu15_5ij249g44iv5zya2pneoifwni, routing-group=[Service_Id_4244_SI_ID_10_Event_1_AM, Service_Id_4244_SI_ID_10_Event_2_AM]
                header-id=278167576, pdu-collection-semantics=QUEUED, pdu-triggering=COM_C0X_Pdu18_88czwl82bbw5mwmq8lydbq9cu, routing-group=Service_Id_4244_SI_ID_10_Event_1_AM
                header-id=278167570, pdu-collection-semantics=QUEUED, pdu-triggering=COM_C0X_Pdu12_9d33ltenthreeih3018061do8, routing-group=[Service_Id_4244_SI_ID_10_Event_1_AM, Service_Id_4244_SI_ID_10_Event_2_AM]
                header-id=278167574, pdu-collection-semantics=QUEUED, pdu-triggering=COM_C0X_Pdu16_3f1v9nrhmarb9dws1h2jbee0b, routing-group=Service_Id_4244_SI_ID_10_Event_1_AM
                header-id=278167577, pdu-collection-semantics=QUEUED, pdu-triggering=COM_C0X_Pdu19_74kb362y50jt1pcwosz97j0uk, routing-group=Service_Id_4244_SI_ID_10_Event_1_AM
                header-id=278167568, pdu-collection-semantics=QUEUED, pdu-triggering=COM_C0X_Pdu10_78pflb0dh807b7g4sj26x9nxn, routing-group=Service_Id_4244_SI_ID_10_Event_1_AM
                header-id=278167569, pdu-collection-semantics=QUEUED, pdu-triggering=COM_C0X_Pdu11_96p7zk2fk1ycqwn7z9eoypj37, routing-group=[Service_Id_4244_SI_ID_10_Event_1_AM, Service_Id_4244_SI_ID_10_Event_2_AM]
                header-id=278167584, pdu-collection-semantics=QUEUED, pdu-triggering=COM_C0X_Pdu20_6gautmu8u3v0gfc0bjkiaecqn, routing-group=Service_Id_4244_SI_ID_10_Event_1_AM
                header-id=8421376, pdu-collection-semantics=QUEUED, pdu-triggering=Ign_Stat_ST3_323m4iypknq8f8i8a46eo81mh, routing-group=Service_Id_128_SI_ID_0_Ign_Stat_AM
            SCB_ECU4_CRN_TCP_TX_fixed_10_20_1_4_45000:
              socket-connection{client-ip-addr-from-connection-request=true, client-port-from-connection-request=true, client-port=SA_TCP_TX_Any_DynamicPort, pdu-collection-max-buffer-size=1472, pdu-collection-timeout=0, short-label=SC_ECU4_CRN_TCP_TX_Any_DynamicPort}
              pdus=socket-connection-ipdu-identifier={header-id=67272706, pdu-collection-pdu-timeout=0, pdu-collection-semantics=QUEUED, pdu-collection-trigger=ALWAYS, pdu-triggering=COM_C04_Pdu03_ee8amlymwx093h6g6qybwhgyu, routing-group=Service_Id_1026_SI_ID_1_EG01_AC}
              server-port=SA_TCP_TX_fixed_10_20_1_4_45000
            SCB_ECU4_CRN_TCP_TX_fixed_10_20_1_4_50022:
              socket-connection{client-ip-addr-from-connection-request=true, client-port-from-connection-request=true, client-port=SA_TCP_TX_Any_DynamicPort, pdu-collection-max-buffer-size=1472, pdu-collection-timeout=0.01, short-label=SC_ECU4_CRN_TCP_TX_Any_DynamicPort}
              pdus=socket-connection-ipdu-identifier={header-id=824213505, pdu-collection-semantics=QUEUED, pdu-triggering=CANFD_Eth_ST3_TPA_7ek96ff2ffqu2r1f6vuo3klkz, routing-group=Service_Id_12576_SI_ID_10_CANFD_Eth_AC}
              server-port=SA_TCP_TX_fixed_10_20_1_4_50022
            SCB_ECU4_CRN_TCP_RX_Any_DynamicPort:
              socket-connection{client-port=SA_TCP_RX_fixed_10_20_1_4_50023, runtime-ip-address-configuration=SD, runtime-port-configuration=SD, short-label=SC_ECU4_CRN_TCP_RX_fixed_10_20_1_4_50023}
              pdus=socket-connection-ipdu-identifier={header-id=824279041, pdu-collection-semantics=QUEUED, pdu-triggering=Eth_CANFD_ST3_TPA_4j0ewx68js6iny6awlpfddx9g, routing-group=Service_Id_12577_SI_ID_10_Eth_CANFD_AC}
              server-port=SA_TCP_RX_Any_DynamicPort
            ECU4_CRN_SD_Bundle: socket-connection{client-ip-addr-from-connection-request=true, client-port-from-connection-request=true, client-port=SA_ECU4_CRN_SD_DATA_UDP_Any_DynamicPort_Remote, pdus=[{header-id=4294934784, pdu-triggering=ECU4_CRN_SD_Ctrl_Rx_TRIGGERING}, {header-id=4294934784, pdu-triggering=ECU4_CRN_SD_Ctrl_Tx_TRIGGERING}], runtime-ip-address-configuration=SD, runtime-port-configuration=SD, short-label=SC_ECU4_CRN_SD_DATA_UDP_Any_DynamicPort_Remote}, server-port=SA_ECU4_CRN_SD_Ctrl_UDP_fixed_10_20_1_4_30490
            ECU4_CRN_SD_Bundle_Multicast_Rx: socket-connection{client-ip-addr-from-connection-request=true, client-port-from-connection-request=true, client-port=SA_ECU4_CRN_SD_DATA_UDP_Any_DynamicPort_Remote, pdus=socket-connection-ipdu-identifier={header-id=4294934784, pdu-triggering=ECU4_CRN_SD_Ctrl_Rx_Multicast_TRIGGERING}, runtime-ip-address-configuration=SD, runtime-port-configuration=SD, short-label=SC_ECU4_CRN_SD_DATA_UDP_Any_DynamicPort_Remote}, server-port=SA_ECU4_CRN_SD_Ctrl_UDP_Multicast_Rx_fixed_239_20_0_2_30490
          48 x socket address:
            SA_TCP_fixed_10_20_1_1_50022
              application endpoint AE_TCP_fixed_10_20_1_1_50022: network-endpoint=NE_fixed_10_20_1_1, tp-configuration=tcp-tp=tcp-tp-port=port-number=50022
            SA_TCP_fixed_10_20_1_4_50022: connector=ECU4_CRN_Eth_Cluster4_3l8iyw65auc022so95pkbhyzp
              application endpoint AE_TCP_fixed_10_20_1_4_50022: network-endpoint=NE_fixed_10_20_1_4, tp-configuration=tcp-tp=tcp-tp-port=port-number=50022
            SA_TCP_fixed_10_20_1_1_50031
              application endpoint AE_TCP_fixed_10_20_1_1_50031: network-endpoint=NE_fixed_10_20_1_1, tp-configuration=tcp-tp=tcp-tp-port=port-number=50031
            SA_TCP_fixed_10_20_1_4_50031: connector=ECU4_CRN_Eth_Cluster4_3l8iyw65auc022so95pkbhyzp
              application endpoint AE_TCP_fixed_10_20_1_4_50031: network-endpoint=NE_fixed_10_20_1_4, tp-configuration=tcp-tp=tcp-tp-port=port-number=50031
            SA_ECU4_CRN_UDP_fixed_10_20_1_4_50001: connector=ECU4_CRN_Eth_Cluster4_3l8iyw65auc022so95pkbhyzp
              application endpoint AE_ECU4_CRN_UDP_fixed_10_20_1_4_50001: network-endpoint=NE_fixed_10_20_1_4, tp-configuration=udp-tp=udp-tp-port=port-number=50001
            SA_ECU4_CRN_UDP_fixed_10_20_1_1_50001_Remote
              application endpoint AE_ECU4_CRN_UDP_fixed_10_20_1_1_50001_Remote: network-endpoint=NE_fixed_10_20_1_1, tp-configuration=udp-tp=udp-tp-port=port-number=50001
            SA_ECU4_CRN_UDP_fixed_10_20_1_4_50002: connector=ECU4_CRN_Eth_Cluster4_3l8iyw65auc022so95pkbhyzp
              application endpoint AE_ECU4_CRN_UDP_fixed_10_20_1_4_50002: network-endpoint=NE_fixed_10_20_1_4, tp-configuration=udp-tp=udp-tp-port=port-number=50002
            SA_ECU4_CRN_UDP_fixed_10_20_1_1_50002_Remote
              application endpoint AE_ECU4_CRN_UDP_fixed_10_20_1_1_50002_Remote: network-endpoint=NE_fixed_10_20_1_1, tp-configuration=udp-tp=udp-tp-port=port-number=50002
            SA_ECU4_CRN_UDP_fixed_10_20_1_4_50005: connector=ECU4_CRN_Eth_Cluster4_3l8iyw65auc022so95pkbhyzp
              application endpoint AE_ECU4_CRN_UDP_fixed_10_20_1_4_50005: network-endpoint=NE_fixed_10_20_1_4, tp-configuration=udp-tp=udp-tp-port=port-number=50005
            SA_ECU4_CRN_UDP_fixed_10_20_1_1_50005_Remote
              application endpoint AE_ECU4_CRN_UDP_fixed_10_20_1_1_50005_Remote: network-endpoint=NE_fixed_10_20_1_1, tp-configuration=udp-tp=udp-tp-port=port-number=50005
            SA_ECU4_CRN_UDP_fixed_10_20_1_4_50006: connector=ECU4_CRN_Eth_Cluster4_3l8iyw65auc022so95pkbhyzp
              application endpoint AE_ECU4_CRN_UDP_fixed_10_20_1_4_50006: network-endpoint=NE_fixed_10_20_1_4, tp-configuration=udp-tp=udp-tp-port=port-number=50006
            SA_ECU4_CRN_UDP_fixed_10_20_1_1_50006_Remote
              application endpoint AE_ECU4_CRN_UDP_fixed_10_20_1_1_50006_Remote: network-endpoint=NE_fixed_10_20_1_1, tp-configuration=udp-tp=udp-tp-port=port-number=50006
            SA_ECU4_CRN_UDP_fixed_10_20_1_4_50007: connector=ECU4_CRN_Eth_Cluster4_3l8iyw65auc022so95pkbhyzp
              application endpoint AE_ECU4_CRN_UDP_fixed_10_20_1_4_50007: network-endpoint=NE_fixed_10_20_1_4, tp-configuration=udp-tp=udp-tp-port=port-number=50007
            SA_ECU4_CRN_UDP_fixed_10_20_1_1_50007_Remote
              application endpoint AE_ECU4_CRN_UDP_fixed_10_20_1_1_50007_Remote: network-endpoint=NE_fixed_10_20_1_1, tp-configuration=udp-tp=udp-tp-port=port-number=50007
            SA_ECU4_CRN_UDP_fixed_10_20_1_4_50013: connector=ECU4_CRN_Eth_Cluster4_3l8iyw65auc022so95pkbhyzp
              application endpoint AE_ECU4_CRN_UDP_fixed_10_20_1_4_50013: network-endpoint=NE_fixed_10_20_1_4, tp-configuration=udp-tp=udp-tp-port=port-number=50013
            SA_ECU4_CRN_UDP_fixed_10_20_1_1_50013_Remote
              application endpoint AE_ECU4_CRN_UDP_fixed_10_20_1_1_50013_Remote: network-endpoint=NE_fixed_10_20_1_1, tp-configuration=udp-tp=udp-tp-port=port-number=50013
            SA_ECU4_CRN_UDP_fixed_10_20_1_7_50013_Remote
              application endpoint AE_ECU4_CRN_UDP_fixed_10_20_1_7_50013_Remote: network-endpoint=NE_fixed_10_20_1_7, tp-configuration=udp-tp=udp-tp-port=port-number=50013
            SA_ECU4_CRN_UDP_fixed_10_20_1_4_50014: connector=ECU4_CRN_Eth_Cluster4_3l8iyw65auc022so95pkbhyzp
              application endpoint AE_ECU4_CRN_UDP_fixed_10_20_1_4_50014: network-endpoint=NE_fixed_10_20_1_4, tp-configuration=udp-tp=udp-tp-port=port-number=50014
            SA_ECU4_CRN_UDP_fixed_10_20_1_1_50014_Remote
              application endpoint AE_ECU4_CRN_UDP_fixed_10_20_1_1_50014_Remote: network-endpoint=NE_fixed_10_20_1_1, tp-configuration=udp-tp=udp-tp-port=port-number=50014
            SA_ECU4_CRN_UDP_fixed_10_20_1_4_50015: connector=ECU4_CRN_Eth_Cluster4_3l8iyw65auc022so95pkbhyzp
              application endpoint AE_ECU4_CRN_UDP_fixed_10_20_1_4_50015: network-endpoint=NE_fixed_10_20_1_4, tp-configuration=udp-tp=udp-tp-port=port-number=50015
            SA_ECU4_CRN_UDP_fixed_10_20_1_1_50015_Remote
              application endpoint AE_ECU4_CRN_UDP_fixed_10_20_1_1_50015_Remote: network-endpoint=NE_fixed_10_20_1_1, tp-configuration=udp-tp=udp-tp-port=port-number=50015
            SA_ECU4_CRN_UDP_fixed_10_20_1_7_50015_Remote
              application endpoint AE_ECU4_CRN_UDP_fixed_10_20_1_7_50015_Remote: network-endpoint=NE_fixed_10_20_1_7, tp-configuration=udp-tp=udp-tp-port=port-number=50015
            SA_ECU4_CRN_UDP_fixed_10_20_1_4_50016: connector=ECU4_CRN_Eth_Cluster4_3l8iyw65auc022so95pkbhyzp
              application endpoint AE_ECU4_CRN_UDP_fixed_10_20_1_4_50016: network-endpoint=NE_fixed_10_20_1_4, tp-configuration=udp-tp=udp-tp-port=port-number=50016
            SA_ECU4_CRN_UDP_fixed_10_20_1_1_50016_Remote
              application endpoint AE_ECU4_CRN_UDP_fixed_10_20_1_1_50016_Remote: network-endpoint=NE_fixed_10_20_1_1, tp-configuration=udp-tp=udp-tp-port=port-number=50016
            SA_ECU4_CRN_UDP_fixed_10_20_1_7_50016_Remote
              application endpoint AE_ECU4_CRN_UDP_fixed_10_20_1_7_50016_Remote: network-endpoint=NE_fixed_10_20_1_7, tp-configuration=udp-tp=udp-tp-port=port-number=50016
            SA_ECU4_CRN_UDP_fixed_10_20_1_4_50017: connector=ECU4_CRN_Eth_Cluster4_3l8iyw65auc022so95pkbhyzp
              application endpoint AE_ECU4_CRN_UDP_fixed_10_20_1_4_50017: network-endpoint=NE_fixed_10_20_1_4, tp-configuration=udp-tp=udp-tp-port=port-number=50017
            SA_ECU4_CRN_UDP_fixed_10_20_1_1_50017_Remote
              application endpoint AE_ECU4_CRN_UDP_fixed_10_20_1_1_50017_Remote: network-endpoint=NE_fixed_10_20_1_1, tp-configuration=udp-tp=udp-tp-port=port-number=50017
            SA_TCP_fixed_10_20_1_4_50021: connector=ECU4_CRN_Eth_Cluster4_3l8iyw65auc022so95pkbhyzp
              application endpoint AE_TCP_fixed_10_20_1_4_50021: network-endpoint=NE_fixed_10_20_1_4, tp-configuration=tcp-tp=tcp-tp-port=port-number=50021
            SA_TCP_fixed_10_20_1_1_50021
              application endpoint AE_TCP_fixed_10_20_1_1_50021: network-endpoint=NE_fixed_10_20_1_1, tp-configuration=tcp-tp=tcp-tp-port=port-number=50021
            SA_TCP_fixed_10_20_1_4_50030: connector=ECU4_CRN_Eth_Cluster4_3l8iyw65auc022so95pkbhyzp
              application endpoint AE_TCP_fixed_10_20_1_4_50030: network-endpoint=NE_fixed_10_20_1_4, tp-configuration=tcp-tp=tcp-tp-port=port-number=50030
            SA_TCP_fixed_10_20_1_1_50030
              application endpoint AE_TCP_fixed_10_20_1_1_50030: network-endpoint=NE_fixed_10_20_1_1, tp-configuration=tcp-tp=tcp-tp-port=port-number=50030
            SA_ECU4_CRN_UDP_fixed_10_20_1_7_50030_Remote
              application endpoint AE_ECU4_CRN_UDP_fixed_10_20_1_7_50030_Remote: network-endpoint=NE_fixed_10_20_1_7, tp-configuration=udp-tp=udp-tp-port=port-number=50030
            SA_ECU4_CRN_UDP_fixed_10_20_1_4_50031: connector=ECU4_CRN_Eth_Cluster4_3l8iyw65auc022so95pkbhyzp
              application endpoint AE_ECU4_CRN_UDP_fixed_10_20_1_4_50031: network-endpoint=NE_fixed_10_20_1_4, tp-configuration=udp-tp=udp-tp-port=port-number=50031
            SA_ECU4_CRN_UDP_fixed_10_20_1_7_50031_Remote
              application endpoint AE_ECU4_CRN_UDP_fixed_10_20_1_7_50031_Remote: network-endpoint=NE_fixed_10_20_1_7, tp-configuration=udp-tp=udp-tp-port=port-number=50031
            SA_ECU4_CRN_UDP_fixed_10_20_1_4_50032: connector=ECU4_CRN_Eth_Cluster4_3l8iyw65auc022so95pkbhyzp
              application endpoint AE_ECU4_CRN_UDP_fixed_10_20_1_4_50032: network-endpoint=NE_fixed_10_20_1_4, tp-configuration=udp-tp=udp-tp-port=port-number=50032
            SA_ECU4_CRN_UDP_fixed_10_20_1_7_50032_Remote
              application endpoint AE_ECU4_CRN_UDP_fixed_10_20_1_7_50032_Remote: network-endpoint=NE_fixed_10_20_1_7, tp-configuration=udp-tp=udp-tp-port=port-number=50032
            SA_ECU4_CRN_UDP_fixed_10_20_1_4_40000: connector=ECU4_CRN_Eth_Cluster4_3l8iyw65auc022so95pkbhyzp
              application endpoint AE_ECU4_CRN_UDP_fixed_10_20_1_4_40000: network-endpoint=NE_fixed_10_20_1_4, tp-configuration=udp-tp=udp-tp-port=port-number=40000
                7 x consumed service instance:
                  CSI_16640_VSS_Service_CTP_0: provided-service-instance=PSI_16640_VSS_Service_CTP_0, sd-client-config={client-service-major-version=1, client-service-minor-version=0, initial-find-behavior={initial-delay-max-value=0, initial-delay-min-value=0, initial-repetitions-base-delay=0.04, initial-repetitions-max=9}, request-response-delay={max-value=0.02, min-value=0}, ttl=16777215}  # VSS Service ST3
                    consumed event group EG_16640_0_VSS:  # Event Group for Security
                      application-endpoint=AE_ECU4_CRN_UDP_Multicast_Rx_Any_40000
                      event-group-identifier=0
                      routing-group=[Service_Id_16640_SI_ID_0_VSS_ACT, Service_Id_16640_SI_ID_0_VSS_AM]
                      sd-client-config={client-service-major-version=1, client-service-minor-version=0, initial-find-behavior={initial-delay-max-value=0, initial-delay-min-value=0, initial-repetitions-base-delay=0.04, initial-repetitions-max=9}, request-response-delay={max-value=0.02, min-value=0}, ttl=16777215}
                  CSI_14596_PT4_PTCoor_Service_ST3_0: provided-service-instance=PSI_14596_PT4_PTCoor_Service_ST3_0, sd-client-config={client-service-major-version=1, client-service-minor-version=0, initial-find-behavior={initial-delay-max-value=0.07, initial-delay-min-value=0.07, initial-repetitions-base-delay=0.04, initial-repetitions-max=9}, request-response-delay={max-value=0.02, min-value=0}, ttl=16777215}  # Antriebsstrangkoordination Service / Powertrain Coordination Service
                    consumed event group EG_14596_0_PT4_PTCoor4:
                      application-endpoint=AE_ECU4_CRN_UDP_Multicast_Rx_Any_40000
                      event-group-identifier=0
                      routing-group=[Service_Id_14596_SI_ID_0_PT4_PTCoor4_AC, Service_Id_14596_SI_ID_0_PT4_PTCoor4_AM]
                      sd-client-config={client-service-major-version=1, client-service-minor-version=0, initial-find-behavior={initial-delay-max-value=0.07, initial-delay-min-value=0.07, initial-repetitions-base-delay=0.04, initial-repetitions-max=9}, request-response-delay={max-value=0.02, min-value=0}, ttl=16777215}
                  CSI_7810_Veh_Speed_Service_ST3_1: provided-service-instance=PSI_7810_Veh_Speed_Service_ST3_1, sd-client-config={client-service-major-version=1, client-service-minor-version=0, initial-find-behavior={initial-delay-max-value=0.01, initial-delay-min-value=0.01, initial-repetitions-base-delay=0.04, initial-repetitions-max=9}, request-response-delay={max-value=0.02, min-value=0}, ttl=16777215}  # Bremssystem Service ST3 / Brake control system Service ST3
                    consumed event group EG_7810_7_Vehspd_8:
                      application-endpoint=AE_ECU4_CRN_UDP_Multicast_Rx_Any_40000
                      event-group-identifier=7
                      routing-group=[Service_Id_7810_SI_ID_1_Vehspd_8_AC, Service_Id_7810_SI_ID_1_Vehspd_8_AM]
                      sd-client-config={client-service-major-version=1, client-service-minor-version=0, initial-find-behavior={initial-delay-max-value=0.01, initial-delay-min-value=0.01, initial-repetitions-base-delay=0.04, initial-repetitions-max=9}, request-response-delay={max-value=0.02, min-value=0}, ttl=16777215}
                  CSI_12804_DI_OdoSpeedometer_Service_ST3_0: provided-service-instance=PSI_12804_DI_OdoSpeedometer_Service_ST3_0, sd-client-config={client-service-major-version=1, client-service-minor-version=0, initial-find-behavior={initial-delay-max-value=0.105, initial-delay-min-value=0.105, initial-repetitions-base-delay=0.04, initial-repetitions-max=9}, request-response-delay={max-value=0.02, min-value=0}, ttl=16777215}  # Fahrerinformation Odometer und Tacho / DriverInformation Odometer and speedometer
                    consumed event group EG_12804_0_DI_Master_Odometer:
                      application-endpoint=AE_ECU4_CRN_UDP_Multicast_Rx_Any_40000
                      event-group-identifier=0
                      routing-group=Service_Id_12804_SI_ID_0_DI_Master_Odometer_AC
                      sd-client-config={client-service-major-version=1, client-service-minor-version=0, initial-find-behavior={initial-delay-max-value=0.105, initial-delay-min-value=0.105, initial-repetitions-base-delay=0.04, initial-repetitions-max=9}, request-response-delay={max-value=0.02, min-value=0}, ttl=16777215}
                  CSI_14720_PN14_Master_Service_ST3_0: provided-service-instance=PSI_14720_PN14_Master_Service_ST3_0, sd-client-config={client-service-major-version=1, client-service-minor-version=0, initial-find-behavior={initial-delay-max-value=0.015, initial-delay-min-value=0.015, initial-repetitions-base-delay=0.04, initial-repetitions-max=9}, request-response-delay={max-value=0.02, min-value=0}, ttl=16777215}  # 12V Bordnetz Master / PowerNework 12V Master
                    consumed event group EG_14720_0_PN14_Master:  # PowerNetwork 12V Master
                      application-endpoint=AE_ECU4_CRN_UDP_Multicast_Rx_Any_40000
                      event-group-identifier=0
                      routing-group=[Service_Id_14720_SI_ID_0_PN14_Master_AC, Service_Id_14720_SI_ID_0_PN14_Master_AM]
                      sd-client-config={client-service-major-version=1, client-service-minor-version=0, initial-find-behavior={initial-delay-max-value=0.015, initial-delay-min-value=0.015, initial-repetitions-base-delay=0.04, initial-repetitions-max=9}, request-response-delay={max-value=0.02, min-value=0}, ttl=16777215}
                  CSI_4244_COM_C0X_Srv100_CTP_10: provided-service-instance=PSI_4244_COM_C0X_Srv100_CTP_10, sd-client-config={client-service-major-version=1, client-service-minor-version=0, initial-find-behavior={initial-delay-max-value=0.04, initial-delay-min-value=0.04, initial-repetitions-base-delay=0.04, initial-repetitions-max=9}, request-response-delay={max-value=0.02, min-value=0}, ttl=16777215}  # COM C0X Srv 100 CTP
                    consumed event group EG_4244_1_Event_1:  # ALIC Amb
                      application-endpoint=AE_ECU4_CRN_UDP_Multicast_Rx_Any_40000
                      event-group-identifier=1
                      routing-group=[Service_Id_4244_SI_ID_10_Event_1_AC, Service_Id_4244_SI_ID_10_Event_1_AM]
                      sd-client-config={client-service-major-version=1, client-service-minor-version=0, initial-find-behavior={initial-delay-max-value=0.04, initial-delay-min-value=0.04, initial-repetitions-base-delay=0.04, initial-repetitions-max=9}, request-response-delay={max-value=0.02, min-value=0}, ttl=16777215}
                    consumed event group EG_4244_2_Event_2:  # Control channels for basic ambient light
                      application-endpoint=AE_ECU4_CRN_UDP_Multicast_Rx_Any_40000
                      event-group-identifier=2
                      routing-group=[Service_Id_4244_SI_ID_10_Event_2_AC, Service_Id_4244_SI_ID_10_Event_2_AM]
                      sd-client-config={client-service-major-version=1, client-service-minor-version=0, initial-find-behavior={initial-delay-max-value=0.04, initial-delay-min-value=0.04, initial-repetitions-base-delay=0.04, initial-repetitions-max=9}, request-response-delay={max-value=0.02, min-value=0}, ttl=16777215}
                  CSI_128_Immobilizer_Master_Service_ST3_1_0: provided-service-instance=PSI_128_Immobilizer_Master_Service_ST3_1_0, sd-client-config={client-service-major-version=1, client-service-minor-version=0, initial-find-behavior={initial-delay-max-value=0, initial-delay-min-value=0, initial-repetitions-base-delay=0.04, initial-repetitions-max=9}, request-response-delay={max-value=0.02, min-value=0}, ttl=16777215}  # Immobilizer Master Service ST3 derived out of older version [0]
                    consumed event group EG_128_0_Ign_Stat:  # Ignition status Event Group
                      application-endpoint=AE_ECU4_CRN_UDP_Multicast_Rx_Any_40000
                      event-group-identifier=0
                      routing-group=[Service_Id_128_SI_ID_0_Ign_Stat_ACT, Service_Id_128_SI_ID_0_Ign_Stat_AM]
                      sd-client-config={client-service-major-version=1, client-service-minor-version=0, initial-find-behavior={initial-delay-max-value=0, initial-delay-min-value=0, initial-repetitions-base-delay=0.04, initial-repetitions-max=9}, request-response-delay={max-value=0.02, min-value=0}, ttl=16777215}
                provided service instance PSI_4116_COM_C04_Srv100_CTP_10: instance-identifier=10, priority=5, sd-server-config={initial-offer-behavior={initial-delay-max-value=0.005, initial-delay-min-value=0.005, initial-repetitions-base-delay=0.15, initial-repetitions-max=2}, offer-cyclic-delay=0, request-response-delay={max-value=0, min-value=0}, server-service-major-version=1, server-service-minor-version=0, ttl=16777215}, service-identifier=4116
                  event handler EH_4116_Event_1:
                    consumed-event-group=EG_4116_1_Event_1
                    multicast-threshold=7
                    routing-group=[Service_Id_4116_SI_ID_10_Event_1_AC, Service_Id_4116_SI_ID_10_Event_1_AM]
                    sd-server-config={initial-offer-behavior={initial-delay-max-value=0.005, initial-delay-min-value=0.005, initial-repetitions-base-delay=0.15, initial-repetitions-max=2}, offer-cyclic-delay=0, request-response-delay={max-value=0, min-value=0}, server-service-major-version=1, server-service-minor-version=0, ttl=16777215}
                  event handler EH_4116_Event_2:
                    consumed-event-group=EG_4116_2_Event_2
                    multicast-threshold=7
                    routing-group=[Service_Id_4116_SI_ID_10_Event_2_AC, Service_Id_4116_SI_ID_10_Event_2_AM]
                    sd-server-config={initial-offer-behavior={initial-delay-max-value=0.005, initial-delay-min-value=0.005, initial-repetitions-base-delay=0.15, initial-repetitions-max=2}, offer-cyclic-delay=0, request-response-delay={max-value=0, min-value=0}, server-service-major-version=1, server-service-minor-version=0, ttl=16777215}
                provided service instance PSI_1025_COM_C04_Frm02_1:  # CTP_Cluster: CTP-11414: SecOc secured and E2E protected signal transmitted as part of Event in SD service. ServiceID is <ECUnumber><sequentialnumber>. / CTP_Cluster: CTP-11414: SecOc secured and E2E protected signal transmitted as part of Event in SD service.
                  routing-group=Service_1025_SI_ID_1_Methods
                  instance-identifier=1
                  priority=1
                  sd-server-config={initial-offer-behavior={initial-delay-max-value=0.015, initial-delay-min-value=0.015, initial-repetitions-base-delay=0.15, initial-repetitions-max=2}, offer-cyclic-delay=0, request-response-delay={max-value=0, min-value=0}, server-service-major-version=1, server-service-minor-version=0, ttl=16777215}
                  service-identifier=1025
            SA_ECU4_CRN_UDP_Multicast_Rx_Any_40000: multicast-connector=ECU4_CRN_Eth_Cluster4_3l8iyw65auc022so95pkbhyzp
              application endpoint AE_ECU4_CRN_UDP_Multicast_Rx_Any_40000: network-endpoint=NE_Multicast_Rx_Any, tp-configuration=udp-tp=udp-tp-port=port-number=40000
            SA_ECU4_CRN_UDP_Multicast_fixed_239_20_0_3_40000_Remote
              application endpoint AE_ECU4_CRN_UDP_Multicast_fixed_239_20_0_3_40000_Remote: network-endpoint=NE_Multicast_Rx_fixed_239_20_0_3, tp-configuration=udp-tp=udp-tp-port=port-number=40000
            SA_ECU4_CRN_UDP_Any_DynamicPort_Remote
              application endpoint AE_ECU4_CRN_UDP_Any_DynamicPort_Remote: network-endpoint=Eth_Cluster4_20/NE_Any, tp-configuration=udp-tp=udp-tp-port=dynamically-assigned=true
                consumed service instance CSI_4116_COM_C04_Srv100_CTP_10: provided-service-instance=PSI_4116_COM_C04_Srv100_CTP_10  # COM_C04_Srv100_CTP
                  consumed event group EG_4116_1_Event_1: application-endpoint=AE_ECU4_CRN_UDP_Multicast_fixed_239_20_0_3_40000_Remote, event-group-identifier=1, routing-group=[Service_Id_4116_SI_ID_10_Event_1_AC, Service_Id_4116_SI_ID_10_Event_1_AM]  # ALIC Amb
                  consumed event group EG_4116_2_Event_2: application-endpoint=AE_ECU4_CRN_UDP_Multicast_fixed_239_20_0_3_40000_Remote, event-group-identifier=2, routing-group=[Service_Id_4116_SI_ID_10_Event_2_AC, Service_Id_4116_SI_ID_10_Event_2_AM]  # Control channels for basic ambient light
                consumed service instance CSI_1025_COM_C04_Frm02_1: routing-group=Service_1025_SI_ID_1_Methods, provided-service-instance=PSI_1025_COM_C04_Frm02_1  # COM C04 Frm 02
                7 x provided service instance:
                  PSI_16640_VSS_Service_CTP_0: instance-identifier=0, service-identifier=16640  # Configured as in Production database for the configuration of the security update.
                    event handler EH_16640_VSS: consumed-event-group=EG_16640_0_VSS, multicast-threshold=5, routing-group=[Service_Id_16640_SI_ID_0_VSS_ACT, Service_Id_16640_SI_ID_0_VSS_AM]
                  PSI_14596_PT4_PTCoor_Service_ST3_0: instance-identifier=0, service-identifier=14596
                    event handler EH_14596_PT4_PTCoor4: consumed-event-group=EG_14596_0_PT4_PTCoor4, multicast-threshold=7, routing-group=[Service_Id_14596_SI_ID_0_PT4_PTCoor4_AC, Service_Id_14596_SI_ID_0_PT4_PTCoor4_AM]
                  PSI_7810_Veh_Speed_Service_ST3_1: instance-identifier=1, service-identifier=7810
                    event handler EH_7810_Vehspd_8: consumed-event-group=EG_7810_7_Vehspd_8, multicast-threshold=7, routing-group=[Service_Id_7810_SI_ID_1_Vehspd_8_AC, Service_Id_7810_SI_ID_1_Vehspd_8_AM]
                  PSI_12804_DI_OdoSpeedometer_Service_ST3_0: instance-identifier=0, service-identifier=12804
                    event handler EH_12804_DI_Master_Odometer: consumed-event-group=EG_12804_0_DI_Master_Odometer, multicast-threshold=1, routing-group=Service_Id_12804_SI_ID_0_DI_Master_Odometer_AC
                  PSI_14720_PN14_Master_Service_ST3_0: instance-identifier=0, service-identifier=14720
                    event handler EH_14720_PN14_Master: consumed-event-group=EG_14720_0_PN14_Master, multicast-threshold=1, routing-group=[Service_Id_14720_SI_ID_0_PN14_Master_AC, Service_Id_14720_SI_ID_0_PN14_Master_AM]
                  PSI_4244_COM_C0X_Srv100_CTP_10: instance-identifier=10, service-identifier=4244
                    event handler EH_4244_Event_1: consumed-event-group=EG_4244_1_Event_1, multicast-threshold=7, routing-group=[Service_Id_4244_SI_ID_10_Event_1_AC, Service_Id_4244_SI_ID_10_Event_1_AM]
                    event handler EH_4244_Event_2: consumed-event-group=EG_4244_2_Event_2, multicast-threshold=7, routing-group=[Service_Id_4244_SI_ID_10_Event_2_AC, Service_Id_4244_SI_ID_10_Event_2_AM]
                  PSI_128_Immobilizer_Master_Service_ST3_1_0: instance-identifier=0, service-identifier=128
                    event handler EH_128_Ign_Stat: consumed-event-group=EG_128_0_Ign_Stat, multicast-threshold=5, routing-group=[Service_Id_128_SI_ID_0_Ign_Stat_ACT, Service_Id_128_SI_ID_0_Ign_Stat_AM]
            SA_TCP_TX_fixed_10_20_1_4_45000: connector=ECU4_CRN_Eth_Cluster4_3l8iyw65auc022so95pkbhyzp
              application endpoint AE_TCP_TX_fixed_10_20_1_4_45000: network-endpoint=NE_fixed_10_20_1_4, tp-configuration=tcp-tp=tcp-tp-port=port-number=45000
                provided service instance PSI_1026_COM_C04_Frm03_1: instance-identifier=1, priority=1, sd-server-config={initial-offer-behavior={initial-delay-max-value=0.025, initial-delay-min-value=0.025, initial-repetitions-base-delay=0.15, initial-repetitions-max=2}, offer-cyclic-delay=0, request-response-delay={max-value=0, min-value=0}, server-service-major-version=1, server-service-minor-version=0, ttl=16777215}, service-identifier=1026  # CTP_Cluster: CTP-11414: SecOc secured and E2E protected signal transmitted as part of Event in SD service.
                  event handler EH_1026_EG01:
                    consumed-event-group=EG_1026_1_EG01
                    multicast-threshold=0
                    routing-group=Service_Id_1026_SI_ID_1_EG01_AC
                    sd-server-config={initial-offer-behavior={initial-delay-max-value=0.025, initial-delay-min-value=0.025, initial-repetitions-base-delay=0.15, initial-repetitions-max=2}, offer-cyclic-delay=0, request-response-delay={max-value=0, min-value=0}, server-service-major-version=1, server-service-minor-version=0, ttl=16777215}
            SA_TCP_TX_Any_DynamicPort
              application endpoint AE_TCP_TX_Any_DynamicPort: network-endpoint=Eth_Cluster4_20/NE_Any, tp-configuration=tcp-tp=tcp-tp-port=dynamically-assigned=true
                consumed service instance CSI_1026_COM_C04_Frm03_1: provided-service-instance=PSI_1026_COM_C04_Frm03_1  # COM C04 Frm03
                  consumed event group EG_1026_1_EG01: event-group-identifier=1, routing-group=Service_Id_1026_SI_ID_1_EG01_AC
                consumed service instance CSI_12576_Service_CANFD_Eth_ST3_TPA_10: provided-service-instance=PSI_12576_Service_CANFD_Eth_ST3_TPA_10  # CANFD Eth ST3 TPA
                  consumed event group EG_12576_1_CANFD_Eth: event-group-identifier=1, routing-group=Service_Id_12576_SI_ID_10_CANFD_Eth_AC
            SA_TCP_TX_fixed_10_20_1_4_50022: connector=ECU4_CRN_Eth_Cluster4_3l8iyw65auc022so95pkbhyzp
              application endpoint AE_TCP_TX_fixed_10_20_1_4_50022: network-endpoint=NE_fixed_10_20_1_4, tp-configuration=tcp-tp=tcp-tp-port=port-number=50022
                provided service instance PSI_12576_Service_CANFD_Eth_ST3_TPA_10: instance-identifier=10, priority=5, sd-server-config={initial-offer-behavior={initial-delay-max-value=0.02, initial-delay-min-value=0.02, initial-repetitions-base-delay=0.15, initial-repetitions-max=2}, offer-cyclic-delay=0, request-response-delay={max-value=0, min-value=0}, server-service-major-version=1, server-service-minor-version=0, ttl=16777215}, service-identifier=12576
                  event handler EH_12576_CANFD_Eth:
                    consumed-event-group=EG_12576_1_CANFD_Eth
                    multicast-threshold=0
                    routing-group=Service_Id_12576_SI_ID_10_CANFD_Eth_AC
                    sd-server-config={initial-offer-behavior={initial-delay-max-value=0.02, initial-delay-min-value=0.02, initial-repetitions-base-delay=0.15, initial-repetitions-max=2}, offer-cyclic-delay=0, request-response-delay={max-value=0, min-value=0}, server-service-major-version=1, server-service-minor-version=0, ttl=16777215}
            SA_TCP_RX_Any_DynamicPort
              application endpoint AE_TCP_RX_Any_DynamicPort: network-endpoint=Eth_Cluster4_20/NE_Any, tp-configuration=tcp-tp=tcp-tp-port=dynamically-assigned=true
                provided service instance PSI_12577_Service_Eth_CANFD_ST3_TPA_10: instance-identifier=10, service-identifier=12577
                  event handler EH_12577_Eth_CANFD:
                    consumed-event-group=EG_12577_1_Eth_CANFD
                    multicast-threshold=0
                    routing-group=Service_Id_12577_SI_ID_10_Eth_CANFD_AC
                    sd-server-config={initial-offer-behavior={initial-delay-max-value=0.02, initial-delay-min-value=0.02, initial-repetitions-base-delay=0.04, initial-repetitions-max=9}, request-response-delay={max-value=0.02, min-value=0}, server-service-major-version=1, server-service-minor-version=0, ttl=16777215}
            SA_TCP_RX_fixed_10_20_1_4_50023: connector=ECU4_CRN_Eth_Cluster4_3l8iyw65auc022so95pkbhyzp
              application endpoint AE_TCP_RX_fixed_10_20_1_4_50023: network-endpoint=NE_fixed_10_20_1_4, tp-configuration=tcp-tp=tcp-tp-port=port-number=50023
                consumed service instance CSI_12577_Service_Eth_CANFD_ST3_TPA_10: provided-service-instance=PSI_12577_Service_Eth_CANFD_ST3_TPA_10, sd-client-config={client-service-major-version=1, client-service-minor-version=0, initial-find-behavior={initial-delay-max-value=0.02, initial-delay-min-value=0.02, initial-repetitions-base-delay=0.04, initial-repetitions-max=9}, request-response-delay={max-value=0.02, min-value=0}, ttl=16777215}  # Eth CANFD ST3 TPA
                  consumed event group EG_12577_1_Eth_CANFD: event-group-identifier=1, routing-group=Service_Id_12577_SI_ID_10_Eth_CANFD_AC, sd-client-config={client-service-major-version=1, client-service-minor-version=0, initial-find-behavior={initial-delay-max-value=0.02, initial-delay-min-value=0.02, initial-repetitions-base-delay=0.04, initial-repetitions-max=9}, request-response-delay={max-value=0.02, min-value=0}, ttl=16777215}
            SA_ECU4_CRN_SD_Ctrl_UDP_fixed_10_20_1_4_30490: connector=ECU4_CRN_Eth_Cluster4_3l8iyw65auc022so95pkbhyzp
              application endpoint AE_ECU4_CRN_SD_Ctrl_UDP_fixed_10_20_1_4_30490: network-endpoint=NE_fixed_10_20_1_4, tp-configuration=udp-tp=udp-tp-port=port-number=30490
            SA_ECU4_CRN_SD_DATA_UDP_Any_DynamicPort_Remote
              application endpoint AE_ECU4_CRN_SD_DATA_UDP_Any_DynamicPort_Remote: network-endpoint=Eth_Cluster4_20/NE_Any, tp-configuration=udp-tp=udp-tp-port=dynamically-assigned=true
            SA_ECU4_CRN_SD_Ctrl_UDP_Multicast_Rx_fixed_239_20_0_2_30490: multicast-connector=ECU4_CRN_Eth_Cluster4_3l8iyw65auc022so95pkbhyzp
              application endpoint AE_ECU4_CRN_SD_Ctrl_UDP_Multicast_Rx_fixed_239_20_0_2_30490: network-endpoint=NE_Multicast_Rx_fixed_239_20_0_2, tp-configuration=udp-tp=udp-tp-port=port-number=30490
        vlan Eth_Cluster4_20: vlan-identifier=20
      Eth_Cluster4_3
        vlan Eth_Cluster4_3: vlan-identifier=3
      Eth_Cluster4_4
        vlan Eth_Cluster4_4: vlan-identifier=4
      Eth_Cluster4_7
        vlan Eth_Cluster4_7: vlan-identifier=7
    4 x mac multicast group:
      MACMULTICASTADDRESS_01_00_5e_01_00_08: mac-multicast-address=01:00:5E:01:00:08  # 01:00:5e:01:00:08
      MACMULTICASTADDRESS_01_00_5e_7f_00_01: mac-multicast-address=01:00:5E:7F:00:01  # 01:00:5e:7f:00:01
      MACMULTICASTADDRESS_01_00_5e_00_00_01: mac-multicast-address=01:00:5E:00:00:01  # 01:00:5e:00:00:01
      MACMULTICASTADDRESS_01_00_5e_7f_00_02: mac-multicast-address=01:00:5E:7F:00:02  # 01:00:5e:7f:00:02
package /CommunicationClusters/LIN5_Cluster4
  lin cluster LIN5_Cluster4: baudrate=19200, protocol-name=LIN, protocol-version=lin2.1
    lin physical channel LIN5_Cluster4: comm-connectors=ECU4_CRN_LIN5_Cluster4_b21l9awrmlmhxxw03j6k8wiqt
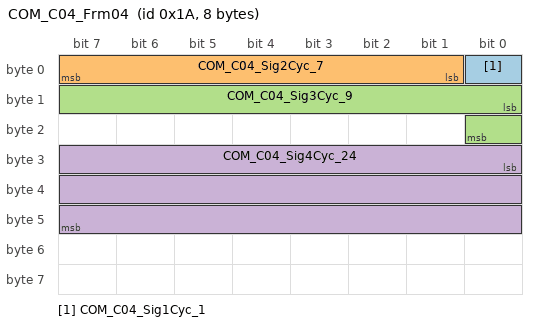
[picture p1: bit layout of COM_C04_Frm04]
      frame COM_C04_Frm04: id 0x1A, from ECU4_CRN, frame-length=8, lin-checksum=ENHANCED  # 8 Byte Frame cyclic
        pdu COM_C04_Pdu04: length=8, unused-bit-pattern=255  # PDU containing cyclic signals of size 1, 7, 9 and 24 bit.
          signal COM_C04_Sig1Cyc_1: start 0, 1 bit, little-endian, data-type-policy=OVERRIDE, i-signal-type=PRIMITIVE, init-value=0, base-type=boolean, transfer-property=PENDING, update-indication-bit-position=63  # 1 Bit cyclic Signal
          signal COM_C04_Sig2Cyc_7: start 1, 7 bit, little-endian, data-type-policy=OVERRIDE, i-signal-type=PRIMITIVE, init-value=0, base-type=uint8, invalid-value=127, data-constr=c07_na_0_to_127_1, transfer-property=PENDING, update-indication-bit-position=62  # 7 Bit Cyclic Signal
          signal COM_C04_Sig3Cyc_9: start 8, 9 bit, little-endian, data-type-policy=OVERRIDE, i-signal-type=PRIMITIVE, init-value=0, base-type=uint16, invalid-value=511, data-constr=c09_na_0_to_511_1, transfer-property=PENDING  # 9 Bit Cyclic Signal
          signal COM_C04_Sig4Cyc_24: start 24, 24 bit, little-endian, data-type-policy=OVERRIDE, i-signal-type=PRIMITIVE, init-value=0, base-type=uint32, invalid-value=16777215, data-constr=c24_na_0_to_16777215_1, transfer-property=PENDING  # 24 bit cyclic signal
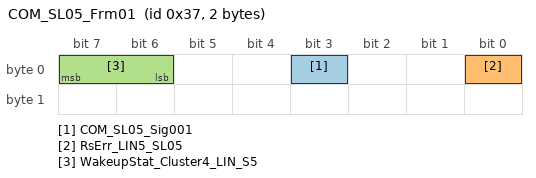
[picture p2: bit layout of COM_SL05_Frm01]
      frame COM_SL05_Frm01: id 0x37, to ECU4_CRN, frame-length=2, lin-checksum=ENHANCED  # Testframe for LIN created for Cluster ECU04 LIN slave node
        carries pdu COM_SL05_Pdu01: packing-byte-order=little-endian, start-position=8
        pdu COM_SL05_Pdu01: length=1, unused-bit-pattern=255
          signal COM_SL05_Sig001: start 3, 1 bit, little-endian, data-type-policy=OVERRIDE, i-signal-type=PRIMITIVE, init-value=0, base-type=boolean, invalid-value=1, data-constr=c01_bit_dummy, transfer-property=PENDING, to ECU4_CRN  # -
          signal RsErr_LIN5_SL05: start 0, 1 bit, little-endian, data-type-policy=OVERRIDE, i-signal-type=PRIMITIVE, init-value=0, base-type=boolean, transfer-property=PENDING, to ECU4_CRN
          signal WakeupStat_Cluster4_LIN_S5: start 6, 2 bit, little-endian, data-type-policy=OVERRIDE, i-signal-type=PRIMITIVE, init-value=3, base-type=uint8, invalid-value=3, compu-method=c02_WakeUp_Stat, data-constr=c02_WakeUp_Stat, transfer-property=PENDING, to ECU4_CRN  # Aufwachgrund - LIN Slave 5 Cluster 4 / Wakeup reason - LIN Slave 5 Cluster 4
      frame MasterReq: id 0x3C, from ECU4_CRN, frame-length=8, lin-checksum=CLASSIC
        n pdu MasterReq: length=8
      frame SlaveResp: id 0x3D, to ECU4_CRN, frame-length=8, lin-checksum=CLASSIC
        n pdu SlaveResp: length=8
      pdu triggering DIAG_NAD_5_RQ_LIN5_Cluster4_ST3_f4a8d5ia61l7fx7t2nwyjxh85: pdu=DIAG_NAD_5_RQ_LIN5_Cluster4_ST3, from ECU4_CRN
      pdu triggering DIAG_NAD_5_RS_LIN5_Cluster4_ST3_65usekbs1p0zme542ei23h0me: pdu=DIAG_NAD_5_RS_LIN5_Cluster4_ST3, to ECU4_CRN
      lin schedule table sch_appl_0: run-mode=RUN-CONTINUOUS
        table-entrys:
          delay=0.04, position-in-table=0, frame-triggering=COM_C04_Frm04_9m4e9s8snxdt2v1tshjqcauak
          delay=0.04, position-in-table=1, frame-triggering=COM_SL05_Frm01_d31ioqpgpujnqirldjwaglz4s
      lin schedule table sch_mreq: run-mode=RUN-CONTINUOUS, application-entry{delay=0.01, position-in-table=0, frame-triggering=MasterReq}
      lin schedule table sch_sresp: run-mode=RUN-CONTINUOUS, application-entry{delay=0.01, position-in-table=0, frame-triggering=XDIS_d8rs41pce8j439a3n5metj3ro}
package /NmConfigs
  nm config NM_CONFIG
    can nm cluster CAN1_Cluster4: communication-cluster=CAN1_Cluster4, nm-channel-id=32, nm-channel-sleep-master=false, nm-pnc-participation=true, nm-synchronizing-network=false, nm-busload-reduction-active=false, nm-cbv-position=0, nm-immediate-nm-cycle-time=0.02, nm-immediate-nm-transmissions=6, nm-message-timeout-time=0.5, nm-msg-cycle-time=1, nm-network-timeout=2.5, nm-repeat-message-time=3, nm-wait-bus-sleep-time=1.5
      can nm node ECU4_CRN_CAN1_Cluster4NMNODE: controller=ECU4_CRN_CAN1_Cluster4, nm-if-ecu=ECU4_CRN_CAN_NMECU, rx-nm-pdu=NM_C10, tx-nm-pdu=PKG_CAN1_Cluster4/NM_C04, nm-msg-cycle-offset=0, nm-msg-reduced-time=1.3
    can nm cluster CANFD1_Cluster4: communication-cluster=CANFD1_Cluster4, nm-channel-id=3, nm-channel-sleep-master=false, nm-pnc-participation=true, nm-synchronizing-network=false, nm-busload-reduction-active=false, nm-cbv-position=0, nm-immediate-nm-cycle-time=0.02, nm-immediate-nm-transmissions=6, nm-message-timeout-time=0.5, nm-msg-cycle-time=1, nm-network-timeout=2.5, nm-repeat-message-time=3, nm-wait-bus-sleep-time=1.5
      can nm node ECU4_CRN_CANFD1_Cluster4NMNODE: controller=ECU4_CRN_CANFD1_Cluster4, nm-if-ecu=ECU4_CRN_CAN_NMECU, rx-nm-pdu=NM_Dummy_ST3, tx-nm-pdu=PKG_CANFD1_Cluster4/NM_C04, nm-msg-cycle-offset=0, nm-msg-reduced-time=1.3
    udp nm cluster Eth_Cluster4_127: communication-cluster=Eth_Cluster4, nm-channel-id=1, nm-channel-sleep-master=false, nm-pnc-participation=true, nm-synchronizing-network=false, nm-cbv-position=0, nm-channel-active=true, nm-immediate-nm-cycle-time=0.02, nm-immediate-nm-transmissions=6, nm-message-timeout-time=0.5, nm-msg-cycle-time=1, nm-network-timeout=2.5, nm-repeat-message-time=3, nm-wait-bus-sleep-time=1.5, vlan=Eth_Cluster4_127
      udp nm node ECU4_CRN_Eth_Cluster4NMNODE_127: controller=ECU4_CRN_Eth_Cluster4, nm-if-ecu=ECU4_CRN_Ethernet_NMECU, nm-passive-mode-enabled=false, rx-nm-pdu=NM_Dummy__ST3, tx-nm-pdu=PKG_Eth_Cluster4_127/NM_C04, nm-msg-cycle-offset=0
    nm-cluster-couplings:
      can-nm-cluster-coupling={coupled-cluster=CAN1_Cluster4, nm-busload-reduction-enabled=false, nm-immediate-restart-enabled=false}
      can-nm-cluster-coupling={coupled-cluster=CANFD1_Cluster4, nm-busload-reduction-enabled=false, nm-immediate-restart-enabled=false}
      udp-nm-cluster-coupling={coupled-cluster=Eth_Cluster4_127, nm-bus-load-reduction-enabled=false, nm-immediate-restart-enabled=false}
    nm-if-ecus:
      nm ecu ECU4_CRN_CAN_NMECU: ecu-instance=ECU4_CRN, nm-com-control-enabled=true, nm-node-detection-enabled=false, nm-node-id-enabled=false, nm-remote-sleep-ind-enabled=false, nm-repeat-msg-ind-enabled=false, nm-user-data-enabled=false
      nm ecu ECU4_CRN_Ethernet_NMECU: ecu-instance=ECU4_CRN, nm-com-control-enabled=true, nm-node-detection-enabled=false, nm-node-id-enabled=false, nm-remote-sleep-ind-enabled=false, nm-repeat-msg-ind-enabled=false, nm-user-data-enabled=false
package /ISignalIPduGroups/CAN1_Cluster4/PKG_CAN1_Cluster4
  6 x i signal i pdu group, all with communication-mode=Partial Network:
    ECU4_CRN_CAN1_Cluster4_Tx_PNC_All_Active: communication-direction=OUT
      i-signal-i-pdus:
        PKG_CAN1_Cluster4/COM_C04_Pdu01_PN08
        PKG_CAN1_Cluster4/COM_C04_Pdu01_PN17
        ECU_Stat_C04_CAN1
        PKG_CAN1_Cluster4/Ign_Stat_ST3
        PKG_CAN1_Cluster4/VSS_TP_Auth_ST3
        PKG_CAN1_Cluster4/VSS_TP_RealTmOffset_ST3
        VSS_TP_SecTickCount_Lvl2_ST3
        PKG_CAN1_Cluster4/VSS_TP_SharedSecret_ST3
        PKG_CAN1_Cluster4/VSS_TP_VIN_ST3
    ECU4_CRN_CAN1_Cluster4_Tx_PNC_09: communication-direction=OUT
      i-signal-i-pdus:
        PKG_CAN1_Cluster4/COM_C04_Pdu01_PN17
        ECU_Stat_C04_CAN1
        PKG_CAN1_Cluster4/Ign_Stat_ST3
        PKG_CAN1_Cluster4/VSS_TP_Auth_ST3
        PKG_CAN1_Cluster4/VSS_TP_RealTmOffset_ST3
        PKG_CAN1_Cluster4/VSS_TP_SharedSecret_ST3
        PKG_CAN1_Cluster4/VSS_TP_VIN_ST3
    ECU4_CRN_CAN1_Cluster4_Tx_PNC_00: communication-direction=OUT
      i-signal-i-pdus:
        PKG_CAN1_Cluster4/COM_C04_Pdu01_PN08
        PKG_CAN1_Cluster4/COM_C04_Pdu01_PN17
        ECU_Stat_C04_CAN1
        PKG_CAN1_Cluster4/Ign_Stat_ST3
        PKG_CAN1_Cluster4/VSS_TP_Auth_ST3
        PKG_CAN1_Cluster4/VSS_TP_RealTmOffset_ST3
        PKG_CAN1_Cluster4/VSS_TP_SharedSecret_ST3
        PKG_CAN1_Cluster4/VSS_TP_VIN_ST3
    ECU4_CRN_CAN1_Cluster4_Rx_PNC_All_Active: communication-direction=IN, i-signal-i-pdus=[COM_C10_Pdu01_PN08, COM_C10_Pdu01_PN17]
    ECU4_CRN_CAN1_Cluster4_Rx_PNC_09: communication-direction=IN, i-signal-i-pdus=COM_C10_Pdu01_PN17
    ECU4_CRN_CAN1_Cluster4_Rx_PNC_00: communication-direction=IN, i-signal-i-pdus=[COM_C10_Pdu01_PN08, COM_C10_Pdu01_PN17]
package /ISignalIPduGroups/CANFD1_Cluster4/PKG_CANFD1_Cluster4
  6 x i signal i pdu group, all with communication-mode=Partial Network:
    ECU4_CRN_CANFD1_Cluster4_Tx_PNC_All_Active: communication-direction=OUT
      i-signal-i-pdus:
        C04_CANFD_1_Container_ST3_Ign_Stat_ST3
        C04_CANFD_1_Container_ST3_VSS_TP_Auth_ST3
        C04_CANFD_1_Container_ST3_VSS_TP_RealTmOffset_ST3
        C04_CANFD_1_Container_ST3_VSS_TP_SecTickCount_Lvl2_ST3
        C04_CANFD_1_Container_ST3_VSS_TP_SharedSecret_ST3
        C04_CANFD_1_Container_ST3_VSS_TP_VIN_ST3
        COM_C04_Frm05_COM_C04_Pdu{05..07}
        PKG_CANFD1_Cluster4/COM_C04_Pdu01_PN08
        PKG_CANFD1_Cluster4/COM_C04_Pdu01_PN44
        ECU_Stat_C04_CANFD1
        SDU_TPA_Eth_CANFD_ST3
    ECU4_CRN_CANFD1_Cluster4_Tx_PNC_36: communication-direction=OUT
      i-signal-i-pdus:
        C04_CANFD_1_Container_ST3_Ign_Stat_ST3
        C04_CANFD_1_Container_ST3_VSS_TP_Auth_ST3
        C04_CANFD_1_Container_ST3_VSS_TP_RealTmOffset_ST3
        C04_CANFD_1_Container_ST3_VSS_TP_SharedSecret_ST3
        C04_CANFD_1_Container_ST3_VSS_TP_VIN_ST3
        PKG_CANFD1_Cluster4/COM_C04_Pdu01_PN44
        ECU_Stat_C04_CANFD1
    ECU4_CRN_CANFD1_Cluster4_Tx_PNC_00: communication-direction=OUT
      i-signal-i-pdus:
        C04_CANFD_1_Container_ST3_Ign_Stat_ST3
        C04_CANFD_1_Container_ST3_VSS_TP_Auth_ST3
        C04_CANFD_1_Container_ST3_VSS_TP_RealTmOffset_ST3
        C04_CANFD_1_Container_ST3_VSS_TP_SharedSecret_ST3
        C04_CANFD_1_Container_ST3_VSS_TP_VIN_ST3
        COM_C04_Frm05_COM_C04_Pdu{05..07}
        PKG_CANFD1_Cluster4/COM_C04_Pdu01_PN08
        PKG_CANFD1_Cluster4/COM_C04_Pdu01_PN44
        ECU_Stat_C04_CANFD1
    ECU4_CRN_CANFD1_Cluster4_Rx_PNC_All_Active: communication-direction=IN
      i-signal-i-pdus:
        COM_C19_Frm02_COM_C19_Pdu{02..04}
        COM_C19_Pdu01_PN08
        COM_C19_Pdu01_PN44
        FBL_Cfg_Star3_ST3
        SDU_TPA_CANFD_Eth_ST3
    ECU4_CRN_CANFD1_Cluster4_Rx_PNC_36: communication-direction=IN, i-signal-i-pdus=COM_C19_Pdu01_PN44
    ECU4_CRN_CANFD1_Cluster4_Rx_PNC_00: communication-direction=IN
      i-signal-i-pdus:
        COM_C19_Frm02_COM_C19_Pdu{02..04}
        COM_C19_Pdu01_PN08
        COM_C19_Pdu01_PN44
package /ISignalIPduGroups/Eth_Cluster4/PKG_Eth_Cluster4_1
  i signal i pdu group ECU4_CRN_Eth_Cluster4_Tx_PNC_All_Active: communication-direction=OUT, communication-mode=Partial Network, i-signal-i-pdus=DIAG_ROE_C04_Container_ST3_ROE_C04_PDU01
package /ISignalIPduGroups/Eth_Cluster4/PKG_Eth_Cluster4_127
  8 x i signal i pdu group, all with communication-direction=OUT, communication-mode=Partial Network, i-signal-i-pdus=ECU_Stat_C04_ETH_Container_ECU_Stat_C04_ETH:
    ECU4_CRN_Eth_Cluster4_Tx_PNC_All_Active
    ECU4_CRN_Eth_Cluster4_Tx_PNC_09
    ECU4_CRN_Eth_Cluster4_Tx_PNC_18
    ECU4_CRN_Eth_Cluster4_Tx_PNC_27
    ECU4_CRN_Eth_Cluster4_Tx_PNC_36
    ECU4_CRN_Eth_Cluster4_Tx_PNC_45
    ECU4_CRN_Eth_Cluster4_Tx_PNC_54
    ECU4_CRN_Eth_Cluster4_Tx_PNC_00
package /ISignalIPduGroups/Eth_Cluster4/PKG_Eth_Cluster4_20
  12 x i signal i pdu group, all with communication-mode=Partial Network:
    ECU4_CRN_Eth_Cluster4_Tx_PNC_All_Active: communication-direction=OUT
      i-signal-i-pdus:
        CANFD_Eth_ST3_TPA
        PKG_Eth_Cluster4_20/COM_C04_Pdu01_PN08
        PKG_Eth_Cluster4_20/COM_C04_Pdu01_PN17
        PKG_Eth_Cluster4_20/COM_C04_Pdu01_PN44
        COM_C04_Pdu01_PN53
        COM_C04_Pdu01_PN62
        COM_C04_Pdu21
    ECU4_CRN_Eth_Cluster4_Tx_PNC_09: communication-direction=OUT, i-signal-i-pdus=PKG_Eth_Cluster4_20/COM_C04_Pdu01_PN17
    ECU4_CRN_Eth_Cluster4_Tx_PNC_36: communication-direction=OUT, i-signal-i-pdus=PKG_Eth_Cluster4_20/COM_C04_Pdu01_PN44
    ECU4_CRN_Eth_Cluster4_Tx_PNC_45: communication-direction=OUT, i-signal-i-pdus=COM_C04_Pdu01_PN53
    ECU4_CRN_Eth_Cluster4_Tx_PNC_54: communication-direction=OUT, i-signal-i-pdus=COM_C04_Pdu01_PN62
    ECU4_CRN_Eth_Cluster4_Tx_PNC_00: communication-direction=OUT
      i-signal-i-pdus:
        PKG_Eth_Cluster4_20/COM_C04_Pdu01_PN08
        PKG_Eth_Cluster4_20/COM_C04_Pdu01_PN17
        PKG_Eth_Cluster4_20/COM_C04_Pdu01_PN44
        COM_C04_Pdu01_PN53
        COM_C04_Pdu01_PN62
    ECU4_CRN_Eth_Cluster4_Rx_PNC_All_Active: communication-direction=IN
      i-signal-i-pdus:
        COM_C01_Pdu01_PN08
        COM_C01_Pdu01_PN17
        COM_C01_Pdu01_PN44
        COM_C01_Pdu01_PN53
        COM_C01_Pdu01_PN62
        COM_C07_Pdu01_PN08
        COM_C07_Pdu01_PN44
        COM_C07_Pdu01_PN53
        COM_C0X_Pdu21
        COM_C14_C04_Pdu01_TpConnection
        DI_OdoSpeedometer_ST3
        Eth_CANFD_ST3_TPA
        PKG_Eth_Cluster4_20/Ign_Stat_ST3
        PN14_Master_Stat1_ST3
        PT4_PTCoor4_ST3
        VehSpd_8_ST3
        PKG_Eth_Cluster4_20/VSS_TP_Auth_ST3
        PKG_Eth_Cluster4_20/VSS_TP_RealTmOffset_ST3
        VSS_TP_SecTickCount_Lvl1_ST3
        PKG_Eth_Cluster4_20/VSS_TP_SharedSecret_ST3
        PKG_Eth_Cluster4_20/VSS_TP_VIN_ST3
    ECU4_CRN_Eth_Cluster4_Rx_PNC_09: communication-direction=IN
      i-signal-i-pdus:
        COM_C01_Pdu01_PN17
        PKG_Eth_Cluster4_20/Ign_Stat_ST3
        PKG_Eth_Cluster4_20/VSS_TP_Auth_ST3
        PKG_Eth_Cluster4_20/VSS_TP_RealTmOffset_ST3
        VSS_TP_SecTickCount_Lvl1_ST3
        PKG_Eth_Cluster4_20/VSS_TP_SharedSecret_ST3
        PKG_Eth_Cluster4_20/VSS_TP_VIN_ST3
    ECU4_CRN_Eth_Cluster4_Rx_PNC_36: communication-direction=IN
      i-signal-i-pdus:
        COM_C01_Pdu01_PN44
        COM_C07_Pdu01_PN44
        PKG_Eth_Cluster4_20/Ign_Stat_ST3
        PKG_Eth_Cluster4_20/VSS_TP_Auth_ST3
        PKG_Eth_Cluster4_20/VSS_TP_RealTmOffset_ST3
        VSS_TP_SecTickCount_Lvl1_ST3
        PKG_Eth_Cluster4_20/VSS_TP_SharedSecret_ST3
        PKG_Eth_Cluster4_20/VSS_TP_VIN_ST3
    ECU4_CRN_Eth_Cluster4_Rx_PNC_45: communication-direction=IN
      i-signal-i-pdus:
        COM_C01_Pdu01_PN53
        COM_C07_Pdu01_PN53
        PKG_Eth_Cluster4_20/Ign_Stat_ST3
        PKG_Eth_Cluster4_20/VSS_TP_Auth_ST3
        PKG_Eth_Cluster4_20/VSS_TP_RealTmOffset_ST3
        VSS_TP_SecTickCount_Lvl1_ST3
        PKG_Eth_Cluster4_20/VSS_TP_SharedSecret_ST3
        PKG_Eth_Cluster4_20/VSS_TP_VIN_ST3
    ECU4_CRN_Eth_Cluster4_Rx_PNC_54: communication-direction=IN
      i-signal-i-pdus:
        COM_C01_Pdu01_PN62
        PKG_Eth_Cluster4_20/Ign_Stat_ST3
        PKG_Eth_Cluster4_20/VSS_TP_Auth_ST3
        PKG_Eth_Cluster4_20/VSS_TP_RealTmOffset_ST3
        VSS_TP_SecTickCount_Lvl1_ST3
        PKG_Eth_Cluster4_20/VSS_TP_SharedSecret_ST3
        PKG_Eth_Cluster4_20/VSS_TP_VIN_ST3
    ECU4_CRN_Eth_Cluster4_Rx_PNC_00: communication-direction=IN
      i-signal-i-pdus:
        COM_C01_Pdu01_PN08
        COM_C01_Pdu01_PN17
        COM_C01_Pdu01_PN44
        COM_C01_Pdu01_PN53
        COM_C01_Pdu01_PN62
        COM_C07_Pdu01_PN08
        COM_C07_Pdu01_PN44
        COM_C07_Pdu01_PN53
        COM_C14_C04_Pdu01_TpConnection
        PKG_Eth_Cluster4_20/Ign_Stat_ST3
        PKG_Eth_Cluster4_20/VSS_TP_Auth_ST3
        PKG_Eth_Cluster4_20/VSS_TP_RealTmOffset_ST3
        VSS_TP_SecTickCount_Lvl1_ST3
        PKG_Eth_Cluster4_20/VSS_TP_SharedSecret_ST3
        PKG_Eth_Cluster4_20/VSS_TP_VIN_ST3
package /ISignalIPduGroups/Eth_Cluster4/PKG_Eth_Cluster4_2
  i signal i pdu group ECU4_CRN_Eth_Cluster4_Rx_PNC_All_Active: communication-direction=IN, communication-mode=Partial Network, i-signal-i-pdus=DIAG_C01_ONBD_Container_ST3_DIAG_Stat_ST3
package /ISignalIPduGroups/LIN5_Cluster4/PKG_LIN5_Cluster4
  i signal i pdu group TxNorm_ECU4_CRN_LIN5_Cluster4: communication-direction=OUT, communication-mode=Normal, i-signal-i-pdus=COM_C04_Pdu04
  i signal i pdu group RxNorm_ECU4_CRN_LIN5_Cluster4: communication-direction=IN, communication-mode=Normal, i-signal-i-pdus=COM_SL05_Pdu01
package /TpConfigs/CAN1_Cluster4
  can tp config CAN1_Cluster4: communication-cluster=CAN1_Cluster4, can-tp-ecu=ECU4_CRN
    6 x can tp address:
      TPA_0ef8h: tp-address=3832
      TPA_0f0dh: tp-address=3853
      TPA_1010h: tp-address=4112
      TPA_eef8h: tp-address=61176
      TPA_ef0dh: tp-address=61197
      TPA_0441h: tp-address=1089
    4 x can tp channel, all with channel-id=32:
      CAN1_Cluster4_DIAG_C10_ExtEth_RQ_CAN1_CTP_DIAG_C10_ExtEth_RS_CAN1_CTP: channel-mode=FULL-DUPLEX-MODE
      CAN1_Cluster4_DIAG_C10_IntEth_RQ_CAN1_CTP_DIAG_C10_IntEth_RS_CAN1_CTP: channel-mode=FULL-DUPLEX-MODE
      CAN1_Cluster4_DIAG_GLOBAL_ExtEth_RQ_CAN1_ST3: channel-mode=HALF-DUPLEX-MODE
      CAN1_Cluster4_DIAG_GLOBAL_IntEth_RQ_CAN1_ST3: channel-mode=HALF-DUPLEX-MODE
    can-tp-connection addressing-format=STANDARD, can-tp-channel=CAN1_Cluster4_DIAG_C10_ExtEth_RQ_CAN1_CTP_DIAG_C10_ExtEth_RS_CAN1_CTP, data-pdu=DIAG_C10_ExtEth_RQ_CAN1_CTP, flow-control-pdu=DIAG_C10_ExtEth_RS_CAN1_CTP, max-block-size=8, padding-activation=true, receiver=TPN_TPA_1010h_ddfsjmsrh6y5in6lw21cljjof, ta-type=PHYSICAL, tp-sdu=SDU_DIAG_C10_ExtEth_RQ_CAN1_CTP, transmitter=TPN_TPA_0ef8h_10c7op4yk731gfizay8ow1tld:
      ident DIAG_C10_ExtEth_RQ_CAN1_CTP
    can-tp-connection addressing-format=STANDARD, can-tp-channel=CAN1_Cluster4_DIAG_C10_ExtEth_RQ_CAN1_CTP_DIAG_C10_ExtEth_RS_CAN1_CTP, data-pdu=DIAG_C10_ExtEth_RS_CAN1_CTP, flow-control-pdu=DIAG_C10_ExtEth_RQ_CAN1_CTP, max-block-size=8, padding-activation=true, receiver=TPN_TPA_0ef8h_10c7op4yk731gfizay8ow1tld, ta-type=PHYSICAL, tp-sdu=SDU_DIAG_C10_ExtEth_RS_CAN1_CTP, transmitter=TPN_TPA_1010h_ddfsjmsrh6y5in6lw21cljjof:
      ident DIAG_C10_ExtEth_RS_CAN1_CTP
    can-tp-connection addressing-format=STANDARD, can-tp-channel=CAN1_Cluster4_DIAG_C10_IntEth_RQ_CAN1_CTP_DIAG_C10_IntEth_RS_CAN1_CTP, data-pdu=DIAG_C10_IntEth_RQ_CAN1_CTP, flow-control-pdu=DIAG_C10_IntEth_RS_CAN1_CTP, max-block-size=8, padding-activation=true, receiver=TPN_TPA_1010h_ddfsjmsrh6y5in6lw21cljjof, ta-type=PHYSICAL, tp-sdu=SDU_DIAG_C10_IntEth_RQ_CAN1_CTP, transmitter=TPN_TPA_0f0dh_cns1h4sb48czf6mcrk8ucoukj:
      ident DIAG_C10_IntEth_RQ_CAN1_CTP
    can-tp-connection addressing-format=STANDARD, can-tp-channel=CAN1_Cluster4_DIAG_C10_IntEth_RQ_CAN1_CTP_DIAG_C10_IntEth_RS_CAN1_CTP, data-pdu=DIAG_C10_IntEth_RS_CAN1_CTP, flow-control-pdu=DIAG_C10_IntEth_RQ_CAN1_CTP, max-block-size=8, padding-activation=true, receiver=TPN_TPA_0f0dh_cns1h4sb48czf6mcrk8ucoukj, ta-type=PHYSICAL, tp-sdu=SDU_DIAG_C10_IntEth_RS_CAN1_CTP, transmitter=TPN_TPA_1010h_ddfsjmsrh6y5in6lw21cljjof:
      ident DIAG_C10_IntEth_RS_CAN1_CTP
    can-tp-connection addressing-format=STANDARD, can-tp-channel=CAN1_Cluster4_DIAG_GLOBAL_ExtEth_RQ_CAN1_ST3, data-pdu=DIAG_RQ_GLOBAL_ExtEth_ST3, max-block-size=0, multicast=CAN1_Cluster4/TPA_0441h, padding-activation=true, receiver=TPN_TPA_eef8h_e28gyflo0xscizl5vuqngx228, ta-type=FUNCTIONAL, tp-sdu=SDU_DIAG_GLOBAL_ExtEth_RQ_CAN1_ST3, transmitter=TPN_TPA_0ef8h_10c7op4yk731gfizay8ow1tld:
      ident DIAG_GLOBAL_ExtEth_RQ_CAN1_ST3
    can-tp-connection addressing-format=STANDARD, can-tp-channel=CAN1_Cluster4_DIAG_GLOBAL_IntEth_RQ_CAN1_ST3, data-pdu=DIAG_RQ_GLOBAL_IntEth_ST3, max-block-size=0, multicast=CAN1_Cluster4/TPA_0441h, padding-activation=true, receiver=TPN_TPA_ef0dh_38tqhigu1rnf2n5u9jsyv427k, ta-type=FUNCTIONAL, tp-sdu=SDU_DIAG_GLOBAL_IntEth_RQ_CAN1_ST3, transmitter=TPN_TPA_0f0dh_cns1h4sb48czf6mcrk8ucoukj:
      ident DIAG_GLOBAL_IntEth_RQ_CAN1_ST3
    5 x can tp node:
      TPN_TPA_0ef8h_10c7op4yk731gfizay8ow1tld: connector=ECU4_CRN_CAN1_Cluster4_6it1ke922hxi7y4c8scsqzzry, st-min=0.01, tp-address=CAN1_Cluster4/TPA_0ef8h
      TPN_TPA_0f0dh_cns1h4sb48czf6mcrk8ucoukj: connector=ECU4_CRN_CAN1_Cluster4_6it1ke922hxi7y4c8scsqzzry, st-min=0.01, tp-address=CAN1_Cluster4/TPA_0f0dh
      TPN_TPA_1010h_ddfsjmsrh6y5in6lw21cljjof: st-min=0.01, tp-address=TPA_1010h
      TPN_TPA_eef8h_e28gyflo0xscizl5vuqngx228: tp-address=CAN1_Cluster4/TPA_eef8h
      TPN_TPA_ef0dh_38tqhigu1rnf2n5u9jsyv427k: tp-address=CAN1_Cluster4/TPA_ef0dh
package /TpConfigs/CANFD1_Cluster4
  can tp config CANFD1_Cluster4: communication-cluster=CANFD1_Cluster4, can-tp-ecu=ECU4_CRN
    11 x can tp address:
      TPA_0ef8h: tp-address=3832
      TPA_0ef9h: tp-address=3833
      TPA_0f0dh: tp-address=3853
      TPA_1004h: tp-address=4100
      TPA_1019h: tp-address=4121
      TPA_4013h: tp-address=16403
      TPA_4014h: tp-address=16404
      TPA_eef8h: tp-address=61176
      TPA_eef9h: tp-address=61177
      TPA_ef0dh: tp-address=61197
      TPA_0441h: tp-address=1089
    7 x can tp channel, all with channel-id=3:
      CANFD1_Cluster4_DIAG_C19_ExtEth_RQ_CANFD1_CTP_DIAG_C19_ExtEth_RS_CANFD1_CTP: channel-mode=FULL-DUPLEX-MODE
      CANFD1_Cluster4_DIAG_C19_IntEth_RQ_CANFD1_CTP_DIAG_C19_IntEth_RS_CANFD1_CTP: channel-mode=FULL-DUPLEX-MODE
      CANFD1_Cluster4_DIAG_ECU4_CTP_03_ExtCAN_RQ_FD1_ST3_DIAG_ECU4_CTP_03_ExtCAN_RS_FD1_ST3: channel-mode=FULL-DUPLEX-MODE
      CANFD1_Cluster4_DIAG_GLOBAL_ExtCAN_RQ_CANFD1_ST3: channel-mode=HALF-DUPLEX-MODE
      CANFD1_Cluster4_DIAG_GLOBAL_ExtEth_RQ_CANFD1_ST3: channel-mode=HALF-DUPLEX-MODE
      CANFD1_Cluster4_DIAG_GLOBAL_IntEth_RQ_CANFD1_ST3: channel-mode=HALF-DUPLEX-MODE
      CANFD1_Cluster4_TPA_CANFD_Eth_ST3_TPA_Eth_CANFD_ST3: channel-mode=FULL-DUPLEX-MODE
    can-tp-connection addressing-format=STANDARD, can-tp-channel=CANFD1_Cluster4_DIAG_C19_ExtEth_RQ_CANFD1_CTP_DIAG_C19_ExtEth_RS_CANFD1_CTP, data-pdu=DIAG_C19_ExtEth_RQ_CANFD1_CTP, flow-control-pdu=DIAG_C19_ExtEth_RS_CANFD1_CTP, max-block-size=8, padding-activation=true, receiver=TPN_TPA_1019h_8x1gneobjd9lct717qe67naqw, ta-type=PHYSICAL-CAN-FD, tp-sdu=SDU_DIAG_C19_ExtEth_RQ_CANFD1_CTP, transmitter=TPN_TPA_0ef8h_7539z5cnmys6dfii5e74756k4:
      ident DIAG_C19_ExtEth_RQ_CANFD1_CTP
    can-tp-connection addressing-format=STANDARD, can-tp-channel=CANFD1_Cluster4_DIAG_C19_ExtEth_RQ_CANFD1_CTP_DIAG_C19_ExtEth_RS_CANFD1_CTP, data-pdu=DIAG_C19_ExtEth_RS_CANFD1_CTP, flow-control-pdu=DIAG_C19_ExtEth_RQ_CANFD1_CTP, max-block-size=8, padding-activation=true, receiver=TPN_TPA_0ef8h_7539z5cnmys6dfii5e74756k4, ta-type=PHYSICAL-CAN-FD, tp-sdu=SDU_DIAG_C19_ExtEth_RS_CANFD1_CTP, transmitter=TPN_TPA_1019h_8x1gneobjd9lct717qe67naqw:
      ident DIAG_C19_ExtEth_RS_CANFD1_CTP
    can-tp-connection addressing-format=STANDARD, can-tp-channel=CANFD1_Cluster4_DIAG_C19_IntEth_RQ_CANFD1_CTP_DIAG_C19_IntEth_RS_CANFD1_CTP, data-pdu=DIAG_C19_IntEth_RQ_CANFD1_CTP, flow-control-pdu=DIAG_C19_IntEth_RS_CANFD1_CTP, max-block-size=8, padding-activation=true, receiver=TPN_TPA_1019h_8x1gneobjd9lct717qe67naqw, ta-type=PHYSICAL-CAN-FD, tp-sdu=SDU_DIAG_C19_IntEth_RQ_CANFD1_CTP, transmitter=TPN_TPA_0f0dh_9ibncb5q7evue7pr54iaz2io0:
      ident DIAG_C19_IntEth_RQ_CANFD1_CTP
    can-tp-connection addressing-format=STANDARD, can-tp-channel=CANFD1_Cluster4_DIAG_C19_IntEth_RQ_CANFD1_CTP_DIAG_C19_IntEth_RS_CANFD1_CTP, data-pdu=DIAG_C19_IntEth_RS_CANFD1_CTP, flow-control-pdu=DIAG_C19_IntEth_RQ_CANFD1_CTP, max-block-size=8, padding-activation=true, receiver=TPN_TPA_0f0dh_9ibncb5q7evue7pr54iaz2io0, ta-type=PHYSICAL-CAN-FD, tp-sdu=SDU_DIAG_C19_IntEth_RS_CANFD1_CTP, transmitter=TPN_TPA_1019h_8x1gneobjd9lct717qe67naqw:
      ident DIAG_C19_IntEth_RS_CANFD1_CTP
    can-tp-connection addressing-format=STANDARD, can-tp-channel=CANFD1_Cluster4_DIAG_ECU4_CTP_03_ExtCAN_RQ_FD1_ST3_DIAG_ECU4_CTP_03_ExtCAN_RS_FD1_ST3, data-pdu=DIAG_ECU4_CTP_03_ExtCAN_RQ_FD_ST3, flow-control-pdu=DIAG_ECU4_CTP_03_ExtCAN_RS_FD_ST3, max-block-size=0, padding-activation=true, receiver=TPN_TPA_1004h_4zonoy2sa88t7tdjeumhkqjix, ta-type=PHYSICAL-CAN-FD, tp-sdu=SDU_DIAG_ECU4_CTP_03_ExtCAN_RQ_FD1_ST3, transmitter=TPN_TPA_0ef9h_akzwtlrfhovn56f0n7vuye1hs:
      ident DIAG_ECU4_CTP_03_ExtCAN_RQ_FD1_ST3
    can-tp-connection addressing-format=STANDARD, can-tp-channel=CANFD1_Cluster4_DIAG_ECU4_CTP_03_ExtCAN_RQ_FD1_ST3_DIAG_ECU4_CTP_03_ExtCAN_RS_FD1_ST3, data-pdu=DIAG_ECU4_CTP_03_ExtCAN_RS_FD_ST3, flow-control-pdu=DIAG_ECU4_CTP_03_ExtCAN_RQ_FD_ST3, max-block-size=1, padding-activation=true, receiver=TPN_TPA_0ef9h_akzwtlrfhovn56f0n7vuye1hs, ta-type=PHYSICAL-CAN-FD, tp-sdu=SDU_DIAG_ECU4_CTP_03_ExtCAN_RS_FD1_ST3, transmitter=TPN_TPA_1004h_4zonoy2sa88t7tdjeumhkqjix:
      ident DIAG_ECU4_CTP_03_ExtCAN_RS_FD1_ST3
    can-tp-connection addressing-format=STANDARD, can-tp-channel=CANFD1_Cluster4_DIAG_GLOBAL_ExtCAN_RQ_CANFD1_ST3, data-pdu=DIAG_RQ_GLOBAL_ExtCAN_FD_ST3, max-block-size=0, multicast=CANFD1_Cluster4/TPA_0441h, padding-activation=true, receiver=TPN_TPA_eef9h_20b464d6g7lf6bve6hm4bnvs5, ta-type=FUNCTIONAL-CAN-FD, tp-sdu=SDU_DIAG_GLOBAL_ExtCAN_RQ_CANFD1_ST3, transmitter=TPN_TPA_0ef9h_akzwtlrfhovn56f0n7vuye1hs:
      ident DIAG_GLOBAL_ExtCAN_RQ_CANFD1_ST3
    can-tp-connection addressing-format=STANDARD, can-tp-channel=CANFD1_Cluster4_DIAG_GLOBAL_ExtEth_RQ_CANFD1_ST3, data-pdu=DIAG_RQ_GLOBAL_ExtEth_FD_ST3, max-block-size=0, multicast=CANFD1_Cluster4/TPA_0441h, padding-activation=true, receiver=TPN_TPA_eef8h_34d0vj8c3w2qd1fjdb5of13ld, ta-type=FUNCTIONAL-CAN-FD, tp-sdu=SDU_DIAG_GLOBAL_ExtEth_RQ_CANFD1_ST3, transmitter=TPN_TPA_0ef8h_7539z5cnmys6dfii5e74756k4:
      ident DIAG_GLOBAL_ExtEth_RQ_CANFD1_ST3
    can-tp-connection addressing-format=STANDARD, can-tp-channel=CANFD1_Cluster4_DIAG_GLOBAL_IntEth_RQ_CANFD1_ST3, data-pdu=DIAG_RQ_GLOBAL_IntEth_FD_ST3, max-block-size=0, multicast=CANFD1_Cluster4/TPA_0441h, padding-activation=true, receiver=TPN_TPA_ef0dh_6z8it0qw577m7tgcsrql8yb17, ta-type=FUNCTIONAL-CAN-FD, tp-sdu=SDU_DIAG_GLOBAL_IntEth_RQ_CANFD1_ST3, transmitter=TPN_TPA_0f0dh_9ibncb5q7evue7pr54iaz2io0:
      ident DIAG_GLOBAL_IntEth_RQ_CANFD1_ST3
    can-tp-connection addressing-format=STANDARD, can-tp-channel=CANFD1_Cluster4_TPA_CANFD_Eth_ST3_TPA_Eth_CANFD_ST3, data-pdu=TPA_CANFD_Eth_ST3, flow-control-pdu=TPA_Eth_CANFD_ST3, max-block-size=64, padding-activation=false, receiver=TPN_TPA_4014h_ez9ksu56z7bl3xlxchiw3wgcx, ta-type=PHYSICAL-CAN-FD, tp-sdu=SDU_TPA_CANFD_Eth_ST3, transmitter=TPN_TPA_4013h_36ikz5ahxepcpakt73gorpjcc:
      ident TPA_CANFD_Eth_ST3
    can-tp-connection addressing-format=STANDARD, can-tp-channel=CANFD1_Cluster4_TPA_CANFD_Eth_ST3_TPA_Eth_CANFD_ST3, data-pdu=TPA_Eth_CANFD_ST3, flow-control-pdu=TPA_CANFD_Eth_ST3, max-block-size=64, padding-activation=false, receiver=TPN_TPA_4013h_36ikz5ahxepcpakt73gorpjcc, ta-type=PHYSICAL-CAN-FD, tp-sdu=SDU_TPA_Eth_CANFD_ST3, transmitter=TPN_TPA_4014h_ez9ksu56z7bl3xlxchiw3wgcx:
      ident TPA_Eth_CANFD_ST3
    10 x can tp node:
      TPN_TPA_0ef8h_7539z5cnmys6dfii5e74756k4: connector=ECU4_CRN_CANFD1_Cluster4_bx4qzxpu7xp7napnh6bsrtlzq, st-min=0.01, tp-address=CANFD1_Cluster4/TPA_0ef8h
      TPN_TPA_0ef9h_akzwtlrfhovn56f0n7vuye1hs: st-min=0.01, tp-address=TPA_0ef9h
      TPN_TPA_0f0dh_9ibncb5q7evue7pr54iaz2io0: connector=ECU4_CRN_CANFD1_Cluster4_bx4qzxpu7xp7napnh6bsrtlzq, st-min=0.01, tp-address=CANFD1_Cluster4/TPA_0f0dh
      TPN_TPA_1004h_4zonoy2sa88t7tdjeumhkqjix: connector=ECU4_CRN_CANFD1_Cluster4_bx4qzxpu7xp7napnh6bsrtlzq, st-min=0.01, tp-address=TPA_1004h
      TPN_TPA_1019h_8x1gneobjd9lct717qe67naqw: st-min=0.01, tp-address=TPA_1019h
      TPN_TPA_4013h_36ikz5ahxepcpakt73gorpjcc: st-min=0.04, tp-address=TPA_4013h
      TPN_TPA_4014h_ez9ksu56z7bl3xlxchiw3wgcx: connector=ECU4_CRN_CANFD1_Cluster4_bx4qzxpu7xp7napnh6bsrtlzq, st-min=0.04, tp-address=TPA_4014h
      TPN_TPA_eef8h_34d0vj8c3w2qd1fjdb5of13ld: tp-address=CANFD1_Cluster4/TPA_eef8h
      TPN_TPA_eef9h_20b464d6g7lf6bve6hm4bnvs5: connector=ECU4_CRN_CANFD1_Cluster4_bx4qzxpu7xp7napnh6bsrtlzq, tp-address=TPA_eef9h
      TPN_TPA_ef0dh_6z8it0qw577m7tgcsrql8yb17: tp-address=CANFD1_Cluster4/TPA_ef0dh
package /TpConfigs/Eth_Cluster4
  eth tp config Eth_Cluster4_20_EthernetTpConfig: communication-cluster=Eth_Cluster4
    tp-connections:
      tp-sdu=COM_C04_C08_Pdu02_TpConnection_38mgt7iec7njwdafureyvik07
      tp-sdu=COM_C04_C14_Pdu01_TpConnection_2suv1h3y7s8zil9mqelpj09fb
      tp-sdu=COM_C08_C04_Pdu02_TpConnection_ahupw1o3wkhij3htd6mdolsex
      tp-sdu=COM_C14_C04_Pdu01_TpConnection_99bzc1cznv5p7ploau5n3z3zj
  do ip tp config Eth_Cluster4_1_DoIpTpConfig: communication-cluster=Eth_Cluster4
    6 x do ip logic address:
      DoIP_EF8: address=3832
      DoIP_1004: address=4100
      DoIP_1010: address=4112
      DoIP_1019: address=4121
      DoIP_EEF8: address=61176
      DoIP_2005: address=8197
    do-ip-tp-connection do-ip-source-address=DoIP_EF8, do-ip-target-address=Eth_Cluster4_1_DoIpTpConfig/DoIP_1004, tp-sdu=SDU_DIAG_RQ_ExtEth_MAIN_OFBD_ST3_ECU04_C04_4dmveypo3w1bhqotywiq097t1:
      ident DIAG_RQ_ExtEth_MAIN_OFBD_ST3_ECU04_C04
    do-ip-tp-connection do-ip-source-address=DoIP_EF8, do-ip-target-address=Eth_Cluster4_1_DoIpTpConfig/DoIP_1010, tp-sdu=SDU_DIAG_RQ_ExtEth_MAIN_OFBD_ST3_ECU04_C10_8bs9x8gur62w6bwg0or3xlt1n:
      ident DIAG_RQ_ExtEth_MAIN_OFBD_ST3_ECU04_C10
    do-ip-tp-connection do-ip-source-address=DoIP_EF8, do-ip-target-address=Eth_Cluster4_1_DoIpTpConfig/DoIP_1019, tp-sdu=SDU_DIAG_RQ_ExtEth_MAIN_OFBD_ST3_ECU04_C19_e3yd3agiopsan0f18roz4lg4c:
      ident DIAG_RQ_ExtEth_MAIN_OFBD_ST3_ECU04_C19
    do-ip-tp-connection do-ip-source-address=DoIP_EF8, do-ip-target-address=DoIP_EEF8, tp-sdu=SDU_DIAG_RQ_ExtEth_MAIN_OFBD_ST3_ECU04_GLOBAL_6t0nz984eogl3mw7cjfi70hic:
      ident DIAG_RQ_ExtEth_MAIN_OFBD_ST3_ECU04_GLOBAL
    do-ip-tp-connection do-ip-source-address=DoIP_EF8, do-ip-target-address=Eth_Cluster4_1_DoIpTpConfig/DoIP_2005, tp-sdu=SDU_DIAG_RQ_ExtEth_MAIN_OFBD_ST3_ECU04_Lin_S5_6ggxi1acxe71ypczxg09dp6fi:
      ident DIAG_RQ_ExtEth_MAIN_OFBD_ST3_ECU04_Lin_S5
    do-ip-tp-connection do-ip-source-address=Eth_Cluster4_1_DoIpTpConfig/DoIP_1004, do-ip-target-address=DoIP_EF8, tp-sdu=SDU_DIAG_RS_ExtEth_MAIN_OFBD_ST3_ECU04_C04_3vlwsmbmh08dnwhynpcmg7w3:
      ident DIAG_RS_ExtEth_MAIN_OFBD_ST3_ECU04_C04
    do-ip-tp-connection do-ip-source-address=Eth_Cluster4_1_DoIpTpConfig/DoIP_1010, do-ip-target-address=DoIP_EF8, tp-sdu=SDU_DIAG_RS_ExtEth_MAIN_OFBD_ST3_ECU04_C10_4so8pe6xjjiiuv0vyru6o8ni0:
      ident DIAG_RS_ExtEth_MAIN_OFBD_ST3_ECU04_C10
    do-ip-tp-connection do-ip-source-address=Eth_Cluster4_1_DoIpTpConfig/DoIP_1019, do-ip-target-address=DoIP_EF8, tp-sdu=SDU_DIAG_RS_ExtEth_MAIN_OFBD_ST3_ECU04_C19_2rqbwg8zxyohi6w3cknvf6a5o:
      ident DIAG_RS_ExtEth_MAIN_OFBD_ST3_ECU04_C19
    do-ip-tp-connection do-ip-source-address=Eth_Cluster4_1_DoIpTpConfig/DoIP_2005, do-ip-target-address=DoIP_EF8, tp-sdu=SDU_DIAG_RS_ExtEth_MAIN_OFBD_ST3_ECU04_Lin_S5_68xvz5qpob04lqj41rwbz17ff:
      ident DIAG_RS_ExtEth_MAIN_OFBD_ST3_ECU04_Lin_S5
  do ip tp config Eth_Cluster4_2_DoIpTpConfig: communication-cluster=Eth_Cluster4
    6 x do ip logic address:
      DoIP_F0D: address=3853
      DoIP_1004: address=4100
      DoIP_1010: address=4112
      DoIP_1019: address=4121
      DoIP_EF0D: address=61197
      DoIP_2005: address=8197
    do-ip-tp-connection do-ip-source-address=DoIP_F0D, do-ip-target-address=Eth_Cluster4_2_DoIpTpConfig/DoIP_1004, tp-sdu=SDU_DIAG_RQ_IntEth_MAIN_ONBD_ST3_ECU04_C04_9sg7qwlojfjz042n6cetze6lz:
      ident DIAG_RQ_IntEth_MAIN_ONBD_ST3_ECU04_C04
    do-ip-tp-connection do-ip-source-address=DoIP_F0D, do-ip-target-address=Eth_Cluster4_2_DoIpTpConfig/DoIP_1010, tp-sdu=SDU_DIAG_RQ_IntEth_MAIN_ONBD_ST3_ECU04_C10_bu43aca6egev4kodpfgkbh2q1:
      ident DIAG_RQ_IntEth_MAIN_ONBD_ST3_ECU04_C10
    do-ip-tp-connection do-ip-source-address=DoIP_F0D, do-ip-target-address=Eth_Cluster4_2_DoIpTpConfig/DoIP_1019, tp-sdu=SDU_DIAG_RQ_IntEth_MAIN_ONBD_ST3_ECU04_C19_ewow239n0d9my3gr29d7sf5d9:
      ident DIAG_RQ_IntEth_MAIN_ONBD_ST3_ECU04_C19
    do-ip-tp-connection do-ip-source-address=DoIP_F0D, do-ip-target-address=DoIP_EF0D, tp-sdu=SDU_DIAG_RQ_IntEth_MAIN_ONBD_ST3_ECU04_GLOBAL_18bpy3o9ynyikhmp6htlekvij:
      ident DIAG_RQ_IntEth_MAIN_ONBD_ST3_ECU04_GLOBAL
    do-ip-tp-connection do-ip-source-address=DoIP_F0D, do-ip-target-address=Eth_Cluster4_2_DoIpTpConfig/DoIP_2005, tp-sdu=SDU_DIAG_RQ_IntEth_MAIN_ONBD_ST3_ECU04_Lin_S5_1axuns5to494ige1q6fv1uhrf:
      ident DIAG_RQ_IntEth_MAIN_ONBD_ST3_ECU04_Lin_S5
    do-ip-tp-connection do-ip-source-address=Eth_Cluster4_2_DoIpTpConfig/DoIP_1004, do-ip-target-address=DoIP_F0D, tp-sdu=SDU_DIAG_RS_IntEth_MAIN_ONBD_ST3_ECU04_C04_27f5t9nk82ncecf7od0bwxpx4:
      ident DIAG_RS_IntEth_MAIN_ONBD_ST3_ECU04_C04
    do-ip-tp-connection do-ip-source-address=Eth_Cluster4_2_DoIpTpConfig/DoIP_1010, do-ip-target-address=DoIP_F0D, tp-sdu=SDU_DIAG_RS_IntEth_MAIN_ONBD_ST3_ECU04_C10_b7en6eeo4kov60pvr8pzr8ijy:
      ident DIAG_RS_IntEth_MAIN_ONBD_ST3_ECU04_C10
    do-ip-tp-connection do-ip-source-address=Eth_Cluster4_2_DoIpTpConfig/DoIP_1019, do-ip-target-address=DoIP_F0D, tp-sdu=SDU_DIAG_RS_IntEth_MAIN_ONBD_ST3_ECU04_C19_b9uku0tcwh0dsl79rtmnbfkkp:
      ident DIAG_RS_IntEth_MAIN_ONBD_ST3_ECU04_C19
    do-ip-tp-connection do-ip-source-address=Eth_Cluster4_2_DoIpTpConfig/DoIP_2005, do-ip-target-address=DoIP_F0D, tp-sdu=SDU_DIAG_RS_IntEth_MAIN_ONBD_ST3_ECU04_Lin_S5_6wuc0r472khlvbka0p3xs4gvu:
      ident DIAG_RS_IntEth_MAIN_ONBD_ST3_ECU04_Lin_S5
package /TpConfigs/LIN5_Cluster4
  lin tp config LIN5_Cluster4: communication-cluster=LIN5_Cluster4
    tp address TPA_0005h: tp-address=5
    tp-connections:
      data-pdu=MasterReq, flow-control=SlaveResp, lin-tp-n-sdu=DIAG_NAD_5_RQ_LIN5_Cluster4_ST3, receiver=TPN_TPA_0005h_1zbsd690yizl348t6tgap8hom, transmitter=XDIS_evpdkhmquskwstylqov8jmerc
      data-pdu=SlaveResp, flow-control=MasterReq, lin-tp-n-sdu=DIAG_NAD_5_RS_LIN5_Cluster4_ST3, receiver=XDIS_evpdkhmquskwstylqov8jmerc, transmitter=TPN_TPA_0005h_1zbsd690yizl348t6tgap8hom
    lin tp node XDIS_evpdkhmquskwstylqov8jmerc: connector=ECU4_CRN_LIN5_Cluster4_b21l9awrmlmhxxw03j6k8wiqt
    lin tp node TPN_TPA_0005h_1zbsd690yizl348t6tgap8hom: tp-address=TPA_0005h
package /DiagnosticConnections/CAN1_Cluster4/PKG_CAN1_Cluster4
  diagnostic connection DIAG_C10_ExtEth_RQ_CAN1_CTP_DIAG_C10_ExtEth_RS_CAN1_CTP: functional-request=DIAG_GLOBAL_ExtEth_RQ_CAN1_ST3, physical-request=DIAG_C10_ExtEth_RQ_CAN1_CTP, response=DIAG_C10_ExtEth_RS_CAN1_CTP
  diagnostic connection DIAG_C10_IntEth_RQ_CAN1_CTP_DIAG_C10_IntEth_RS_CAN1_CTP: functional-request=DIAG_GLOBAL_IntEth_RQ_CAN1_ST3, physical-request=DIAG_C10_IntEth_RQ_CAN1_CTP, response=DIAG_C10_IntEth_RS_CAN1_CTP
package /DiagnosticConnections/CANFD1_Cluster4/PKG_CANFD1_Cluster4
  diagnostic connection DIAG_C19_ExtEth_RQ_CANFD1_CTP_DIAG_C19_ExtEth_RS_CANFD1_CTP: functional-request=DIAG_GLOBAL_ExtEth_RQ_CANFD1_ST3, physical-request=DIAG_C19_ExtEth_RQ_CANFD1_CTP, response=DIAG_C19_ExtEth_RS_CANFD1_CTP
  diagnostic connection DIAG_ECU4_CTP_03_ExtCAN_RQ_FD1_ST3_DIAG_ECU4_CTP_03_ExtCAN_RS_FD1_ST3: functional-request=DIAG_GLOBAL_ExtCAN_RQ_CANFD1_ST3, physical-request=DIAG_ECU4_CTP_03_ExtCAN_RQ_FD1_ST3, response=DIAG_ECU4_CTP_03_ExtCAN_RS_FD1_ST3
  diagnostic connection DIAG_C19_IntEth_RQ_CANFD1_CTP_DIAG_C19_IntEth_RS_CANFD1_CTP: functional-request=DIAG_GLOBAL_IntEth_RQ_CANFD1_ST3, physical-request=DIAG_C19_IntEth_RQ_CANFD1_CTP, response=DIAG_C19_IntEth_RS_CANFD1_CTP
package /DiagnosticConnections/Eth_Cluster4/PKG_Eth_Cluster4_1
  4 x diagnostic connection, all with functional-request=DIAG_RQ_ExtEth_MAIN_OFBD_ST3_ECU04_GLOBAL:
    DIAG_RQ_ExtEth_MAIN_OFBD_ST3_ECU04_C04_DIAG_RS_ExtEth_MAIN_OFBD_ST3_ECU04_C04: physical-request=DIAG_RQ_ExtEth_MAIN_OFBD_ST3_ECU04_C04, response=DIAG_RS_ExtEth_MAIN_OFBD_ST3_ECU04_C04
    DIAG_RQ_ExtEth_MAIN_OFBD_ST3_ECU04_C10_DIAG_RS_ExtEth_MAIN_OFBD_ST3_ECU04_C10: physical-request=DIAG_RQ_ExtEth_MAIN_OFBD_ST3_ECU04_C10, response=DIAG_RS_ExtEth_MAIN_OFBD_ST3_ECU04_C10
    DIAG_RQ_ExtEth_MAIN_OFBD_ST3_ECU04_C19_DIAG_RS_ExtEth_MAIN_OFBD_ST3_ECU04_C19: physical-request=DIAG_RQ_ExtEth_MAIN_OFBD_ST3_ECU04_C19, response=DIAG_RS_ExtEth_MAIN_OFBD_ST3_ECU04_C19
    DIAG_RQ_ExtEth_MAIN_OFBD_ST3_ECU04_Lin_S5_DIAG_RS_ExtEth_MAIN_OFBD_ST3_ECU04_Lin_S5: physical-request=DIAG_RQ_ExtEth_MAIN_OFBD_ST3_ECU04_Lin_S5, response=DIAG_RS_ExtEth_MAIN_OFBD_ST3_ECU04_Lin_S5
package /DiagnosticConnections/Eth_Cluster4/PKG_Eth_Cluster4_2
  4 x diagnostic connection, all with functional-request=DIAG_RQ_IntEth_MAIN_ONBD_ST3_ECU04_GLOBAL:
    DIAG_RQ_IntEth_MAIN_ONBD_ST3_ECU04_C04_DIAG_RS_IntEth_MAIN_ONBD_ST3_ECU04_C04: physical-request=DIAG_RQ_IntEth_MAIN_ONBD_ST3_ECU04_C04, response=DIAG_RS_IntEth_MAIN_ONBD_ST3_ECU04_C04
    DIAG_RQ_IntEth_MAIN_ONBD_ST3_ECU04_C10_DIAG_RS_IntEth_MAIN_ONBD_ST3_ECU04_C10: physical-request=DIAG_RQ_IntEth_MAIN_ONBD_ST3_ECU04_C10, response=DIAG_RS_IntEth_MAIN_ONBD_ST3_ECU04_C10
    DIAG_RQ_IntEth_MAIN_ONBD_ST3_ECU04_C19_DIAG_RS_IntEth_MAIN_ONBD_ST3_ECU04_C19: physical-request=DIAG_RQ_IntEth_MAIN_ONBD_ST3_ECU04_C19, response=DIAG_RS_IntEth_MAIN_ONBD_ST3_ECU04_C19
    DIAG_RQ_IntEth_MAIN_ONBD_ST3_ECU04_Lin_S5_DIAG_RS_IntEth_MAIN_ONBD_ST3_ECU04_Lin_S5: physical-request=DIAG_RQ_IntEth_MAIN_ONBD_ST3_ECU04_Lin_S5, response=DIAG_RS_IntEth_MAIN_ONBD_ST3_ECU04_Lin_S5
package /GlobalTimeDomains
  global time domain GTD_CAN1_Cluster4_0:  # CAN1_Cluster4
    category=SYNCHRONIZED
    communication-cluster=CAN1_Cluster4
    debounce-time=0.04
    domain-id=0
    global-time-domain-props=can-global-time-domain-props={fup-data-id-lists=[143, 78, 13, 199, 134, 69, 4, 190, 125, 60, 246, 181, 116, 51, 237, 172], sync-data-id-lists=[225, 102, 230, 107, 235, 112, 240, 117, 245, 122, 250, 127, 4, 132, 9, 137]}
    global-time-pdu-triggering=GTS_Main_CAN_CTP_84j6k0ap5loroit05ff8s99wx
    sync-loss-timeout=1.75
    global time gateway GTG_ECU4_CRN_0: host=ECU4_CRN, master=GTD_CAN1_Cluster4_0/GTM_ECU4_CRN_0, slave=GTS_ECU4_CRN_0_127  # ECU4_CRN
    global time can master GTM_ECU4_CRN_0: communication-connector=ECU4_CRN_CAN1_Cluster4_6it1ke922hxi7y4c8scsqzzry, immediate-resume-time=0.7, is-system-wide-global-time-master=false, sync-period=0.5, crc-secured=CRC-SUPPORTED, follow-up-offset=0.04, sync-confirmation-timeout=0.2  # ECU4_CRN
  global time domain GTD_CANFD1_Cluster4_0:  # CANFD1_Cluster4
    category=SYNCHRONIZED
    communication-cluster=CANFD1_Cluster4
    debounce-time=0.04
    domain-id=0
    global-time-domain-props=can-global-time-domain-props={fup-data-id-lists=[143, 78, 13, 199, 134, 69, 4, 190, 125, 60, 246, 181, 116, 51, 237, 172], sync-data-id-lists=[225, 102, 230, 107, 235, 112, 240, 117, 245, 122, 250, 127, 4, 132, 9, 137]}
    global-time-pdu-triggering=GTS_Main_CAN_CTP_de8wavvw30s7ryj73e6531mad
    sync-loss-timeout=1.75
    global time gateway GTG_ECU4_CRN_0: host=ECU4_CRN, master=GTD_CANFD1_Cluster4_0/GTM_ECU4_CRN_0, slave=GTS_ECU4_CRN_0_127  # ECU4_CRN
    global time can master GTM_ECU4_CRN_0: communication-connector=ECU4_CRN_CANFD1_Cluster4_bx4qzxpu7xp7napnh6bsrtlzq, immediate-resume-time=0.7, is-system-wide-global-time-master=false, sync-period=0.5, crc-secured=CRC-SUPPORTED, follow-up-offset=0.04, sync-confirmation-timeout=0.2  # ECU4_CRN
  global time domain GTD_Eth_Cluster4_0_127:  # Eth_Cluster4
    category=SYNCHRONIZED
    communication-cluster=Eth_Cluster4
    debounce-time=0.04
    domain-id=0
    global-time-domain-props=eth-global-time-domain-props={fup-data-id-lists=[204, 214, 224, 234, 244, 3, 13, 23, 33, 43, 53, 63, 73, 83, 93, 103], managed-coupling-ports=[{coupling-port=COUPLING_PORT, pdelay-request-period=0, pdelay-response-enabled=false}, {coupling-port=ECU1_CRN_Switch, pdelay-request-period=0, pdelay-response-enabled=false}, {coupling-port=ECU7, pdelay-request-period=0, pdelay-response-enabled=false}, {coupling-port=ECU4_CRN_Switch, pdelay-request-period=0, pdelay-response-enabled=false}, {coupling-port=ECU5, pdelay-request-period=0, pdelay-response-enabled=false}], message-compliance=IEEE802-1AS-AUTOSAR, vlan-priority=7}
    sub-domain=[GTD_CAN1_Cluster4_0, GTD_CANFD1_Cluster4_0]
    sync-loss-timeout=1.75
    global time eth slave GTS_ECU4_CRN_0_127: communication-connector=ECU4_CRN_Eth_Cluster4_3g6xoesclytkmkqofl9pi6ol1, follow-up-timeout-value=0.25, time-leap-future-threshold=0.0017, time-leap-healing-counter=3, time-leap-past-threshold=0.0017, crc-validated=CRC-VALIDATED  # ECU4_CRN
package /SoAdRoutingGroups/Eth_Cluster4/PKG_Eth_Cluster4_20/ECU4_CRN
  23 x so ad routing group:
    Service_Id_16640_SI_ID_0_VSS_ACT: event-group-control-type=ACTIVATION-AND-TRIGGER-UNICAST
    Service_Id_16640_SI_ID_0_VSS_AM: event-group-control-type=ACTIVATION-MULTICAST
    Service_Id_14596_SI_ID_0_PT4_PTCoor4_AC: event-group-control-type=ACTIVATION-UNICAST
    Service_Id_14596_SI_ID_0_PT4_PTCoor4_AM: event-group-control-type=ACTIVATION-MULTICAST
    Service_1025_SI_ID_1_Methods
    Service_Id_7810_SI_ID_1_Vehspd_8_AC: event-group-control-type=ACTIVATION-UNICAST
    Service_Id_7810_SI_ID_1_Vehspd_8_AM: event-group-control-type=ACTIVATION-MULTICAST
    Service_Id_12804_SI_ID_0_DI_Master_Odometer_AC: event-group-control-type=ACTIVATION-UNICAST
    Service_Id_4116_SI_ID_10_Event_1_AC: event-group-control-type=ACTIVATION-UNICAST
    Service_Id_4116_SI_ID_10_Event_1_AM: event-group-control-type=ACTIVATION-MULTICAST
    Service_Id_4116_SI_ID_10_Event_2_AC: event-group-control-type=ACTIVATION-UNICAST
    Service_Id_4116_SI_ID_10_Event_2_AM: event-group-control-type=ACTIVATION-MULTICAST
    Service_Id_14720_SI_ID_0_PN14_Master_AC: event-group-control-type=ACTIVATION-UNICAST
    Service_Id_14720_SI_ID_0_PN14_Master_AM: event-group-control-type=ACTIVATION-MULTICAST
    Service_Id_4244_SI_ID_10_Event_1_AC: event-group-control-type=ACTIVATION-UNICAST
    Service_Id_4244_SI_ID_10_Event_1_AM: event-group-control-type=ACTIVATION-MULTICAST
    Service_Id_4244_SI_ID_10_Event_2_AC: event-group-control-type=ACTIVATION-UNICAST
    Service_Id_4244_SI_ID_10_Event_2_AM: event-group-control-type=ACTIVATION-MULTICAST
    Service_Id_128_SI_ID_0_Ign_Stat_ACT: event-group-control-type=ACTIVATION-AND-TRIGGER-UNICAST
    Service_Id_128_SI_ID_0_Ign_Stat_AM: event-group-control-type=ACTIVATION-MULTICAST
    Service_Id_1026_SI_ID_1_EG01_AC: event-group-control-type=ACTIVATION-UNICAST
    Service_Id_12576_SI_ID_10_CANFD_Eth_AC: event-group-control-type=ACTIVATION-UNICAST
    Service_Id_12577_SI_ID_10_Eth_CANFD_AC: event-group-control-type=ACTIVATION-UNICAST
package /CouplingElements
  coupling element Cluster4_ECU4_CRN_Switch: communication-cluster=Eth_Cluster4, coupling-type=SWITCH, ecu-instance=ECU4_CRN  # Cluster 4 ECU4 Coordinator Switch
    4 x coupling port:
      ECU5: connection-negotiation-behavior=SLAVE, coupling-port-role=STANDARD-PORT, mac-multicast-address=[MACMULTICASTADDRESS_01_00_5e_7f_00_01, MACMULTICASTADDRESS_01_00_5e_00_00_01, MACMULTICASTADDRESS_01_00_5e_7f_00_02], physical-layer-type=100BASE-T1, pnc-mapping=[PNC_00_MAPPING, PNC_45_MAPPING, PNC_54_MAPPING]  # Cluster4_ECU4_CRN_Switch | Cluster 4 ECU4 Coordinator Switch
        coupling-port-details global-time-props=propagation-delay=0.000002, last-egress-scheduler=ECU5/STRICT_PRIORITY_SCHEDULAR:
          coupling-port-structural-elements:
            coupling port scheduler STRICT_PRIORITY_SCHEDULAR: port-scheduler=STRICT-PRIORITY, predecessor=[ECU5/FIFO_7, ECU5/FIFO_6, ECU5/FIFO_5, ECU5/FIFO_4_SHAPER, ECU5/FIFO_3, ECU5/FIFO_2, ECU5/FIFO_1, ECU5/FIFO_0]
            4 x coupling port fifo:
              FIFO_7: assigned-traffic-classs=7
              FIFO_6: assigned-traffic-classs=6
              FIFO_5: assigned-traffic-classs=5
              FIFO_4: assigned-traffic-classs=4
            coupling port shaper FIFO_4_SHAPER: idle-slope=80000000, predecessor-fifo=ECU5/FIFO_4
            4 x coupling port fifo:
              FIFO_3: assigned-traffic-classs=3
              FIFO_2: assigned-traffic-classs=2
              FIFO_1: assigned-traffic-classs=1
              FIFO_0: assigned-traffic-classs=0
          ethernet-traffic-class-assignments:
            8 x coupling port traffic class assignment:
              TrafficClass_{0..7}: prioritys={0..7}, traffic-class={0..7}
        vlan-memberships:
          default-priority=0, send-activity=SENT-TAGGED, vlan=Eth_Cluster4_1
          default-priority=0, send-activity=NOT-SENT, vlan=Eth_Cluster4_3
          default-priority=0, send-activity=SENT-TAGGED, vlan=Eth_Cluster4_4
          default-priority=0, send-activity=SENT-TAGGED, vlan=Eth_Cluster4_7
      ECU4_CRN_Switch: coupling-port-role=HOST-PORT, mac-layer-type=X-MII, mac-multicast-address=[MACMULTICASTADDRESS_01_00_5e_7f_00_02, MACMULTICASTADDRESS_01_00_5e_7f_00_01, MACMULTICASTADDRESS_01_00_5e_00_00_01], pnc-mapping=[PNC_00_MAPPING, PNC_09_MAPPING, PNC_18_MAPPING, PNC_27_MAPPING, PNC_36_MAPPING, PNC_45_MAPPING, PNC_54_MAPPING]  # Cluster4_ECU4_CRN_Switch | Cluster 4 ECU4 Coordinator Switch
        coupling-port-details global-time-props=propagation-delay=0, last-egress-scheduler=ECU4_CRN_Switch/STRICT_PRIORITY_SCHEDULAR:
          coupling-port-structural-elements:
            coupling port scheduler STRICT_PRIORITY_SCHEDULAR: port-scheduler=STRICT-PRIORITY, predecessor=[ECU4_CRN_Switch/FIFO_7, ECU4_CRN_Switch/FIFO_6, ECU4_CRN_Switch/FIFO_5, ECU4_CRN_Switch/FIFO_4_SHAPER, ECU4_CRN_Switch/FIFO_3, ECU4_CRN_Switch/FIFO_2, ECU4_CRN_Switch/FIFO_1, ECU4_CRN_Switch/FIFO_0]
            4 x coupling port fifo:
              FIFO_7: assigned-traffic-classs=7
              FIFO_6: assigned-traffic-classs=6
              FIFO_5: assigned-traffic-classs=5
              FIFO_4: assigned-traffic-classs=4
            coupling port shaper FIFO_4_SHAPER: idle-slope=80000000, predecessor-fifo=ECU4_CRN_Switch/FIFO_4
            4 x coupling port fifo:
              FIFO_3: assigned-traffic-classs=3
              FIFO_2: assigned-traffic-classs=2
              FIFO_1: assigned-traffic-classs=1
              FIFO_0: assigned-traffic-classs=0
          ethernet-traffic-class-assignments:
            8 x coupling port traffic class assignment:
              TrafficClass_{0..7}: prioritys={0..7}, traffic-class={0..7}
        vlan-memberships:
          default-priority=0, send-activity=SENT-TAGGED, vlan=Eth_Cluster4_1
          default-priority=0, send-activity=NOT-SENT, vlan=Eth_Cluster4_3
          default-priority=0, send-activity=SENT-TAGGED, vlan=Eth_Cluster4_4
          default-priority=0, send-activity=SENT-TAGGED, vlan=Eth_Cluster4_7
      ECU7: connection-negotiation-behavior=SLAVE, coupling-port-role=STANDARD-PORT, mac-multicast-address=[MACMULTICASTADDRESS_01_00_5e_7f_00_02, MACMULTICASTADDRESS_01_00_5e_00_00_01, MACMULTICASTADDRESS_01_00_5e_7f_00_01], physical-layer-type=100BASE-T1, pnc-mapping=[PNC_00_MAPPING, PNC_36_MAPPING, PNC_45_MAPPING]  # Cluster4_ECU4_CRN_Switch | Cluster 4 ECU4 Coordinator Switch
        coupling-port-details global-time-props=propagation-delay=0.000002, last-egress-scheduler=ECU7/STRICT_PRIORITY_SCHEDULAR:
          coupling-port-structural-elements:
            coupling port scheduler STRICT_PRIORITY_SCHEDULAR: port-scheduler=STRICT-PRIORITY, predecessor=[ECU7/FIFO_7, ECU7/FIFO_6, ECU7/FIFO_5, ECU7/FIFO_4_SHAPER, ECU7/FIFO_3, ECU7/FIFO_2, ECU7/FIFO_1, ECU7/FIFO_0]
            4 x coupling port fifo:
              FIFO_7: assigned-traffic-classs=7
              FIFO_6: assigned-traffic-classs=6
              FIFO_5: assigned-traffic-classs=5
              FIFO_4: assigned-traffic-classs=4
            coupling port shaper FIFO_4_SHAPER: idle-slope=80000000, predecessor-fifo=ECU7/FIFO_4
            4 x coupling port fifo:
              FIFO_3: assigned-traffic-classs=3
              FIFO_2: assigned-traffic-classs=2
              FIFO_1: assigned-traffic-classs=1
              FIFO_0: assigned-traffic-classs=0
          ethernet-traffic-class-assignments:
            8 x coupling port traffic class assignment:
              TrafficClass_{0..7}: prioritys={0..7}, traffic-class={0..7}
        vlan-memberships:
          default-priority=0, send-activity=SENT-TAGGED, vlan=Eth_Cluster4_1
          default-priority=0, send-activity=NOT-SENT, vlan=Eth_Cluster4_3
          default-priority=0, send-activity=SENT-TAGGED, vlan=Eth_Cluster4_4
          default-priority=0, send-activity=SENT-TAGGED, vlan=Eth_Cluster4_7
      ECU1_CRN_Switch: connection-negotiation-behavior=SLAVE, coupling-port-role=STANDARD-PORT, mac-multicast-address=[MACMULTICASTADDRESS_01_00_5e_00_00_01, MACMULTICASTADDRESS_01_00_5e_7f_00_02, MACMULTICASTADDRESS_01_00_5e_7f_00_01], physical-layer-type=100BASE-T1, pnc-mapping=[PNC_00_MAPPING, PNC_09_MAPPING, PNC_18_MAPPING, PNC_27_MAPPING, PNC_36_MAPPING, PNC_45_MAPPING, PNC_54_MAPPING]  # Cluster4_ECU4_CRN_Switch | Cluster 4 ECU4 Coordinator Switch
        coupling-port-details global-time-props=propagation-delay=0.000002, last-egress-scheduler=ECU1_CRN_Switch/STRICT_PRIORITY_SCHEDULAR:
          coupling-port-structural-elements:
            coupling port scheduler STRICT_PRIORITY_SCHEDULAR: port-scheduler=STRICT-PRIORITY, predecessor=[ECU1_CRN_Switch/FIFO_7, ECU1_CRN_Switch/FIFO_6, ECU1_CRN_Switch/FIFO_5, ECU1_CRN_Switch/FIFO_4_SHAPER, ECU1_CRN_Switch/FIFO_3, ECU1_CRN_Switch/FIFO_2, ECU1_CRN_Switch/FIFO_1, ECU1_CRN_Switch/FIFO_0]
            4 x coupling port fifo:
              FIFO_7: assigned-traffic-classs=7
              FIFO_6: assigned-traffic-classs=6
              FIFO_5: assigned-traffic-classs=5
              FIFO_4: assigned-traffic-classs=4
            coupling port shaper FIFO_4_SHAPER: idle-slope=80000000, predecessor-fifo=ECU1_CRN_Switch/FIFO_4
            4 x coupling port fifo:
              FIFO_3: assigned-traffic-classs=3
              FIFO_2: assigned-traffic-classs=2
              FIFO_1: assigned-traffic-classs=1
              FIFO_0: assigned-traffic-classs=0
          ethernet-traffic-class-assignments:
            8 x coupling port traffic class assignment:
              TrafficClass_{0..7}: prioritys={0..7}, traffic-class={0..7}
        vlan-memberships:
          default-priority=0, send-activity=SENT-TAGGED, vlan=Eth_Cluster4_1
          default-priority=0, send-activity=NOT-SENT, vlan=Eth_Cluster4_3
          default-priority=0, send-activity=SENT-TAGGED, vlan=Eth_Cluster4_4
          default-priority=0, send-activity=SENT-TAGGED, vlan=Eth_Cluster4_7
package /Gateways
  gateway ECU4_CRN: ecu=ECU4_CRN
    i-pdu-mappings:
      {source-i-pdu=Ign_Stat_ST3_323m4iypknq8f8i8a46eo81mh, target-i-pdu={default-value=default-value-elements=[{element-byte-value=150, element-position=0}, {element-byte-value=81, element-position=1}, {element-byte-value=0, element-position=2}, {element-byte-value=7, element-position=3}, {element-byte-value=0, element-position=4}, {element-byte-value=0, element-position=5}, {element-byte-value=0, element-position=6}, {element-byte-value=0, element-position=7}], target-i-pdu=Ign_Stat_ST3_3ymsrx5hnsw2j8h3yjncw5h30}}
      {source-i-pdu=VSS_TP_SharedSecret_ST3_107qjbgt3r0kjosska3jxxrb9, target-i-pdu={default-value=default-value-elements=[{element-byte-value=255, element-position=0}, {element-byte-value=255, element-position=1}, {element-byte-value=255, element-position=2}, {element-byte-value=255, element-position=3}, {element-byte-value=255, element-position=4}, {element-byte-value=255, element-position=5}, {element-byte-value=255, element-position=6}, {element-byte-value=255, element-position=7}], target-i-pdu=VSS_TP_SharedSecret_ST3_3ojy4iemp710d5kp84838fsi}}
      {source-i-pdu=VSS_TP_Auth_ST3_brlg54e6j6ut3jgrbyrvds5r1, target-i-pdu={default-value=default-value-elements=[{element-byte-value=255, element-position=0}, {element-byte-value=255, element-position=1}, {element-byte-value=255, element-position=2}, {element-byte-value=255, element-position=3}, {element-byte-value=255, element-position=4}, {element-byte-value=255, element-position=5}, {element-byte-value=255, element-position=6}, {element-byte-value=255, element-position=7}], target-i-pdu=VSS_TP_Auth_ST3_2fd2bofxyvg8f1sh6pskv39oj}}
      {source-i-pdu=VSS_TP_RealTmOffset_ST3_4ref1poho6hv4l0gks5bbceub, target-i-pdu={default-value=default-value-elements=[{element-byte-value=255, element-position=0}, {element-byte-value=255, element-position=1}, {element-byte-value=255, element-position=2}, {element-byte-value=255, element-position=3}, {element-byte-value=255, element-position=4}, {element-byte-value=255, element-position=5}, {element-byte-value=255, element-position=6}, {element-byte-value=255, element-position=7}], target-i-pdu=VSS_TP_RealTmOffset_ST3_blb8sv2vbzrg5vn6snsfp3oih}}
      {source-i-pdu=VSS_TP_VIN_ST3_6rtjf8y29spxl705nvbfxtc9t, target-i-pdu={default-value=default-value-elements=[{element-byte-value=63, element-position=0}, {element-byte-value=63, element-position=1}, {element-byte-value=63, element-position=2}, {element-byte-value=63, element-position=3}, {element-byte-value=63, element-position=4}, {element-byte-value=63, element-position=5}, {element-byte-value=63, element-position=6}, {element-byte-value=63, element-position=7}], target-i-pdu=VSS_TP_VIN_ST3_bvehnncicls6kkjp2blvuza9w}}
      {source-i-pdu=VSS_TP_SharedSecret_ST3_107qjbgt3r0kjosska3jxxrb9, target-i-pdu={default-value=default-value-elements=[{element-byte-value=255, element-position=0}, {element-byte-value=255, element-position=1}, {element-byte-value=255, element-position=2}, {element-byte-value=255, element-position=3}, {element-byte-value=255, element-position=4}, {element-byte-value=255, element-position=5}, {element-byte-value=255, element-position=6}, {element-byte-value=255, element-position=7}], target-i-pdu=C04_CANFD_1_Container_ST3_C04_CANFD_1_Container_ST3_VSS_TP_SharedSecret_ST3_f0ex48v4v693mvj1jphzyeobi}}
      {source-i-pdu=VSS_TP_Auth_ST3_brlg54e6j6ut3jgrbyrvds5r1, target-i-pdu={default-value=default-value-elements=[{element-byte-value=255, element-position=0}, {element-byte-value=255, element-position=1}, {element-byte-value=255, element-position=2}, {element-byte-value=255, element-position=3}, {element-byte-value=255, element-position=4}, {element-byte-value=255, element-position=5}, {element-byte-value=255, element-position=6}, {element-byte-value=255, element-position=7}], target-i-pdu=C04_CANFD_1_Container_ST3_C04_CANFD_1_Container_ST3_VSS_TP_Auth_ST3_2eg1fyiq81m97nelj47qvj2c4}}
      {source-i-pdu=VSS_TP_RealTmOffset_ST3_4ref1poho6hv4l0gks5bbceub, target-i-pdu={default-value=default-value-elements=[{element-byte-value=255, element-position=0}, {element-byte-value=255, element-position=1}, {element-byte-value=255, element-position=2}, {element-byte-value=255, element-position=3}, {element-byte-value=255, element-position=4}, {element-byte-value=255, element-position=5}, {element-byte-value=255, element-position=6}, {element-byte-value=255, element-position=7}], target-i-pdu=C04_CANFD_1_Container_ST3_C04_CANFD_1_Container_ST3_VSS_TP_RealTmOffset_ST3_767nxsua3lonorooj3kljw1y8}}
      {source-i-pdu=VSS_TP_VIN_ST3_6rtjf8y29spxl705nvbfxtc9t, target-i-pdu={default-value=default-value-elements=[{element-byte-value=63, element-position=0}, {element-byte-value=63, element-position=1}, {element-byte-value=63, element-position=2}, {element-byte-value=63, element-position=3}, {element-byte-value=63, element-position=4}, {element-byte-value=63, element-position=5}, {element-byte-value=63, element-position=6}, {element-byte-value=63, element-position=7}], target-i-pdu=C04_CANFD_1_Container_ST3_C04_CANFD_1_Container_ST3_VSS_TP_VIN_ST3_do07meelbyu42egzxd3kh7khc}}
      {source-i-pdu=Ign_Stat_ST3_323m4iypknq8f8i8a46eo81mh, target-i-pdu={default-value=default-value-elements=[{element-byte-value=150, element-position=0}, {element-byte-value=81, element-position=1}, {element-byte-value=0, element-position=2}, {element-byte-value=7, element-position=3}, {element-byte-value=0, element-position=4}, {element-byte-value=0, element-position=5}, {element-byte-value=0, element-position=6}, {element-byte-value=0, element-position=7}], target-i-pdu=C04_CANFD_1_Container_ST3_C04_CANFD_1_Container_ST3_Ign_Stat_ST3_1992kn5c94live1gqwsimzuwp}}
      pdur-tp-chunk-size=4095, source-i-pdu=SDU_DIAG_C10_ExtEth_RS_CAN1_CTP_45kqv8rapkarohdgmhy5qdbfv, target-i-pdu=SDU_DIAG_RS_ExtEth_MAIN_OFBD_ST3_ECU04_C10_4so8pe6xjjiiuv0vyru6o8ni0
      pdur-tp-chunk-size=4095, source-i-pdu=SDU_DIAG_C10_IntEth_RS_CAN1_CTP_38dhwswv8v6eorqh74kzv6kpk, target-i-pdu=SDU_DIAG_RS_IntEth_MAIN_ONBD_ST3_ECU04_C10_b7en6eeo4kov60pvr8pzr8ijy
      pdur-tp-chunk-size=8191, source-i-pdu=SDU_DIAG_C19_ExtEth_RS_CANFD1_CTP_bhijhykhhudk93cghpikxa48z, target-i-pdu=SDU_DIAG_RS_ExtEth_MAIN_OFBD_ST3_ECU04_C19_2rqbwg8zxyohi6w3cknvf6a5o
      pdur-tp-chunk-size=8191, source-i-pdu=SDU_DIAG_C19_IntEth_RS_CANFD1_CTP_2y5n7celggbq23uuvdl3soavl, target-i-pdu=SDU_DIAG_RS_IntEth_MAIN_ONBD_ST3_ECU04_C19_b9uku0tcwh0dsl79rtmnbfkkp
      pdur-tp-chunk-size=4095, source-i-pdu=SDU_DIAG_RQ_ExtEth_MAIN_OFBD_ST3_ECU04_C10_8bs9x8gur62w6bwg0or3xlt1n, target-i-pdu=SDU_DIAG_C10_ExtEth_RQ_CAN1_CTP_d4iii1s9z0h8hlc7hd91jnf9
      source-i-pdu=SDU_DIAG_RQ_IntEth_MAIN_ONBD_ST3_ECU04_GLOBAL_18bpy3o9ynyikhmp6htlekvij, target-i-pdu=SDU_DIAG_GLOBAL_IntEth_RQ_CAN1_ST3_apowalkvpk3lw0lvb9c7jm62x
      pdur-tp-chunk-size=4095, source-i-pdu=SDU_DIAG_RQ_IntEth_MAIN_ONBD_ST3_ECU04_C10_bu43aca6egev4kodpfgkbh2q1, target-i-pdu=SDU_DIAG_C10_IntEth_RQ_CAN1_CTP_8e7f66cvttnp4uopo5ud8svmb
      source-i-pdu=SDU_DIAG_RQ_ExtEth_MAIN_OFBD_ST3_ECU04_GLOBAL_6t0nz984eogl3mw7cjfi70hic, target-i-pdu=SDU_DIAG_GLOBAL_ExtEth_RQ_CAN1_ST3_4pxg5bdbxi1ved5j8nlzal2yb
      pdur-tp-chunk-size=8191, source-i-pdu=SDU_DIAG_RQ_ExtEth_MAIN_OFBD_ST3_ECU04_C19_e3yd3agiopsan0f18roz4lg4c, target-i-pdu=SDU_DIAG_C19_ExtEth_RQ_CANFD1_CTP_eyvcacykr98fcvkcggj4dhrfu
      source-i-pdu=SDU_DIAG_RQ_ExtEth_MAIN_OFBD_ST3_ECU04_GLOBAL_6t0nz984eogl3mw7cjfi70hic, target-i-pdu=SDU_DIAG_GLOBAL_ExtEth_RQ_CANFD1_ST3_bm2khh4k5j0ahsiarvpnr3xfw
      pdur-tp-chunk-size=8191, source-i-pdu=SDU_DIAG_RQ_IntEth_MAIN_ONBD_ST3_ECU04_C19_ewow239n0d9my3gr29d7sf5d9, target-i-pdu=SDU_DIAG_C19_IntEth_RQ_CANFD1_CTP_2akb334vpy7broagwjotlwysj
      source-i-pdu=SDU_DIAG_RQ_IntEth_MAIN_ONBD_ST3_ECU04_GLOBAL_18bpy3o9ynyikhmp6htlekvij, target-i-pdu=SDU_DIAG_GLOBAL_IntEth_RQ_CANFD1_ST3_er43low3fmuv5pz3oqfwqhzx6
      pdur-tp-chunk-size=4095, source-i-pdu=SDU_DIAG_RQ_IntEth_MAIN_ONBD_ST3_ECU04_Lin_S5_1axuns5to494ige1q6fv1uhrf, target-i-pdu=DIAG_NAD_5_RQ_LIN5_Cluster4_ST3_f4a8d5ia61l7fx7t2nwyjxh85
      pdur-tp-chunk-size=4095, source-i-pdu=SDU_DIAG_RQ_ExtEth_MAIN_OFBD_ST3_ECU04_Lin_S5_6ggxi1acxe71ypczxg09dp6fi, target-i-pdu=DIAG_NAD_5_RQ_LIN5_Cluster4_ST3_f4a8d5ia61l7fx7t2nwyjxh85
      pdur-tp-chunk-size=4095, source-i-pdu=DIAG_NAD_5_RS_LIN5_Cluster4_ST3_65usekbs1p0zme542ei23h0me, target-i-pdu=SDU_DIAG_RS_ExtEth_MAIN_OFBD_ST3_ECU04_Lin_S5_68xvz5qpob04lqj41rwbz17ff
      pdur-tp-chunk-size=4095, source-i-pdu=DIAG_NAD_5_RS_LIN5_Cluster4_ST3_65usekbs1p0zme542ei23h0me, target-i-pdu=SDU_DIAG_RS_IntEth_MAIN_ONBD_ST3_ECU04_Lin_S5_6wuc0r472khlvbka0p3xs4gvu
      source-i-pdu=SDU_TPA_CANFD_Eth_ST3_223y18kpjajvocx2jd9qi9m6d, target-i-pdu=CANFD_Eth_ST3_TPA_7ek96ff2ffqu2r1f6vuo3klkz
      source-i-pdu=Eth_CANFD_ST3_TPA_4j0ewx68js6iny6awlpfddx9g, target-i-pdu=SDU_TPA_Eth_CANFD_ST3_3qyvbrq6q4y6bx7f9mo5p0pxc
